VERSION ""

NS_ :

BS_:

BU_: AGSM BCM BSM CADM DMSM DTCM ECM EVCU2 GNMM HCP IPC RFHM SGW TCM
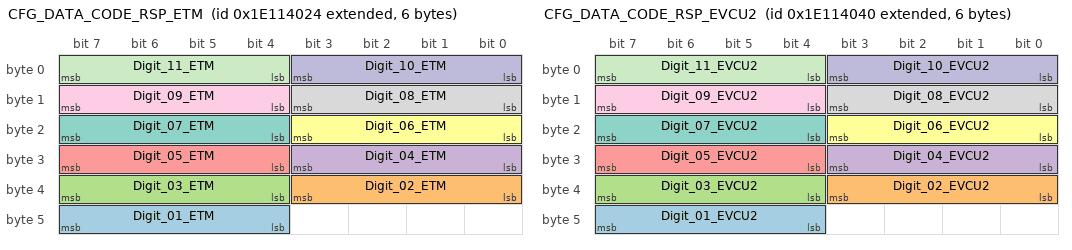
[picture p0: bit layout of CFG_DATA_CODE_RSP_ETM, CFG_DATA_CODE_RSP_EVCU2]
BO_ 2651930660 CFG_DATA_CODE_RSP_ETM: 6 SGW
 SG_ Digit_01_ETM : 47|4@0+ (1,0) [0|15] "-" BCM
 SG_ Digit_02_ETM : 35|4@0+ (1,0) [0|15] "-" BCM
 SG_ Digit_03_ETM : 39|4@0+ (1,0) [0|15] "-" BCM
 SG_ Digit_04_ETM : 27|4@0+ (1,0) [0|15] "-" BCM
 SG_ Digit_05_ETM : 31|4@0+ (1,0) [0|15] "-" BCM
 SG_ Digit_06_ETM : 19|4@0+ (1,0) [0|15] "-" BCM
 SG_ Digit_07_ETM : 23|4@0+ (1,0) [0|15] "-" BCM
 SG_ Digit_08_ETM : 11|4@0+ (1,0) [0|15] "-" BCM
 SG_ Digit_09_ETM : 15|4@0+ (1,0) [0|15] "-" BCM
 SG_ Digit_10_ETM : 3|4@0+ (1,0) [0|15] "-" BCM
 SG_ Digit_11_ETM : 7|4@0+ (1,0) [0|15] "-" BCM

BO_ 2651930688 CFG_DATA_CODE_RSP_EVCU2: 6 EVCU2
 SG_ Digit_01_EVCU2 : 47|4@0+ (1,0) [0|15] "-" BCM
 SG_ Digit_02_EVCU2 : 35|4@0+ (1,0) [0|15] "-" BCM
 SG_ Digit_03_EVCU2 : 39|4@0+ (1,0) [0|15] "-" BCM
 SG_ Digit_04_EVCU2 : 27|4@0+ (1,0) [0|15] "-" BCM
 SG_ Digit_05_EVCU2 : 31|4@0+ (1,0) [0|15] "-" BCM
 SG_ Digit_06_EVCU2 : 19|4@0+ (1,0) [0|15] "-" BCM
 SG_ Digit_07_EVCU2 : 23|4@0+ (1,0) [0|15] "-" BCM
 SG_ Digit_08_EVCU2 : 11|4@0+ (1,0) [0|15] "-" BCM
 SG_ Digit_09_EVCU2 : 15|4@0+ (1,0) [0|15] "-" BCM
 SG_ Digit_10_EVCU2 : 3|4@0+ (1,0) [0|15] "-" BCM
 SG_ Digit_11_EVCU2 : 7|4@0+ (1,0) [0|15] "-" BCM

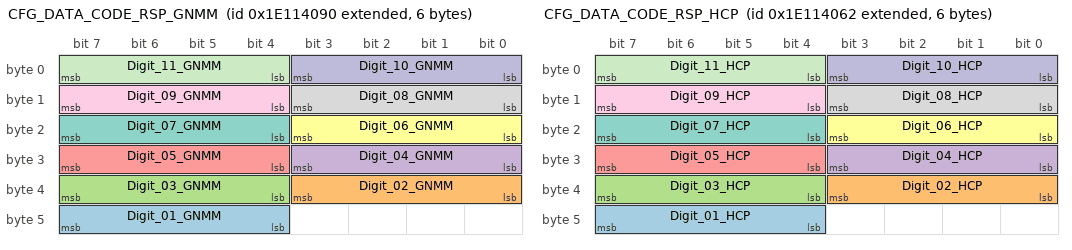
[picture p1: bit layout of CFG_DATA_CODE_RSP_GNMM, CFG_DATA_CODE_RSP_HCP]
BO_ 2651930768 CFG_DATA_CODE_RSP_GNMM: 6 GNMM
 SG_ Digit_01_GNMM : 47|4@0+ (1,0) [0|15] "-" BCM
 SG_ Digit_02_GNMM : 35|4@0+ (1,0) [0|15] "-" BCM
 SG_ Digit_03_GNMM : 39|4@0+ (1,0) [0|15] "-" BCM
 SG_ Digit_04_GNMM : 27|4@0+ (1,0) [0|15] "-" BCM
 SG_ Digit_05_GNMM : 31|4@0+ (1,0) [0|15] "-" BCM
 SG_ Digit_06_GNMM : 19|4@0+ (1,0) [0|15] "-" BCM
 SG_ Digit_07_GNMM : 23|4@0+ (1,0) [0|15] "-" BCM
 SG_ Digit_08_GNMM : 11|4@0+ (1,0) [0|15] "-" BCM
 SG_ Digit_09_GNMM : 15|4@0+ (1,0) [0|15] "-" BCM
 SG_ Digit_10_GNMM : 3|4@0+ (1,0) [0|15] "-" BCM
 SG_ Digit_11_GNMM : 7|4@0+ (1,0) [0|15] "-" BCM

BO_ 2651930722 CFG_DATA_CODE_RSP_HCP: 6 HCP
 SG_ Digit_01_HCP : 47|4@0+ (1,0) [0|15] "-" BCM
 SG_ Digit_02_HCP : 35|4@0+ (1,0) [0|15] "-" BCM
 SG_ Digit_03_HCP : 39|4@0+ (1,0) [0|15] "-" BCM
 SG_ Digit_04_HCP : 27|4@0+ (1,0) [0|15] "-" BCM
 SG_ Digit_05_HCP : 31|4@0+ (1,0) [0|15] "-" BCM
 SG_ Digit_06_HCP : 19|4@0+ (1,0) [0|15] "-" BCM
 SG_ Digit_07_HCP : 23|4@0+ (1,0) [0|15] "-" BCM
 SG_ Digit_08_HCP : 11|4@0+ (1,0) [0|15] "-" BCM
 SG_ Digit_09_HCP : 15|4@0+ (1,0) [0|15] "-" BCM
 SG_ Digit_10_HCP : 3|4@0+ (1,0) [0|15] "-" BCM
 SG_ Digit_11_HCP : 7|4@0+ (1,0) [0|15] "-" BCM

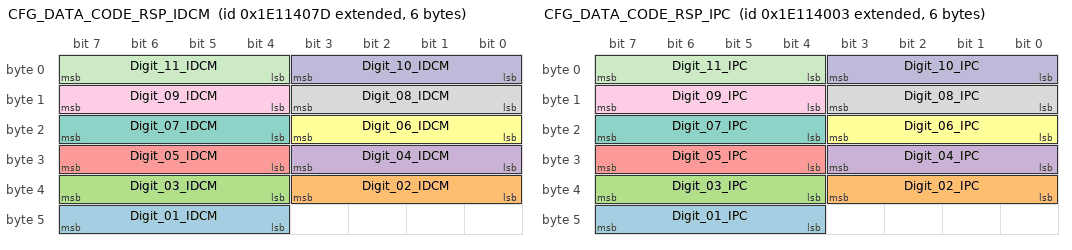
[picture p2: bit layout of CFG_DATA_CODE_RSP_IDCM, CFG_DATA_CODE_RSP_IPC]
BO_ 2651930749 CFG_DATA_CODE_RSP_IDCM: 6 EVCU2
 SG_ Digit_01_IDCM : 47|4@0+ (1,0) [0|15] "-" BCM
 SG_ Digit_02_IDCM : 35|4@0+ (1,0) [0|15] "-" BCM
 SG_ Digit_03_IDCM : 39|4@0+ (1,0) [0|15] "-" BCM
 SG_ Digit_04_IDCM : 27|4@0+ (1,0) [0|15] "-" BCM
 SG_ Digit_05_IDCM : 31|4@0+ (1,0) [0|15] "-" BCM
 SG_ Digit_06_IDCM : 19|4@0+ (1,0) [0|15] "-" BCM
 SG_ Digit_07_IDCM : 23|4@0+ (1,0) [0|15] "-" BCM
 SG_ Digit_08_IDCM : 11|4@0+ (1,0) [0|15] "-" BCM
 SG_ Digit_09_IDCM : 15|4@0+ (1,0) [0|15] "-" BCM
 SG_ Digit_10_IDCM : 3|4@0+ (1,0) [0|15] "-" BCM
 SG_ Digit_11_IDCM : 7|4@0+ (1,0) [0|15] "-" BCM

BO_ 2651930627 CFG_DATA_CODE_RSP_IPC: 6 IPC
 SG_ Digit_01_IPC : 47|4@0+ (1,0) [0|15] "-" BCM
 SG_ Digit_02_IPC : 35|4@0+ (1,0) [0|15] "-" BCM
 SG_ Digit_03_IPC : 39|4@0+ (1,0) [0|15] "-" BCM
 SG_ Digit_04_IPC : 27|4@0+ (1,0) [0|15] "-" BCM
 SG_ Digit_05_IPC : 31|4@0+ (1,0) [0|15] "-" BCM
 SG_ Digit_06_IPC : 19|4@0+ (1,0) [0|15] "-" BCM
 SG_ Digit_07_IPC : 23|4@0+ (1,0) [0|15] "-" BCM
 SG_ Digit_08_IPC : 11|4@0+ (1,0) [0|15] "-" BCM
 SG_ Digit_09_IPC : 15|4@0+ (1,0) [0|15] "-" BCM
 SG_ Digit_10_IPC : 3|4@0+ (1,0) [0|15] "-" BCM
 SG_ Digit_11_IPC : 7|4@0+ (1,0) [0|15] "-" BCM

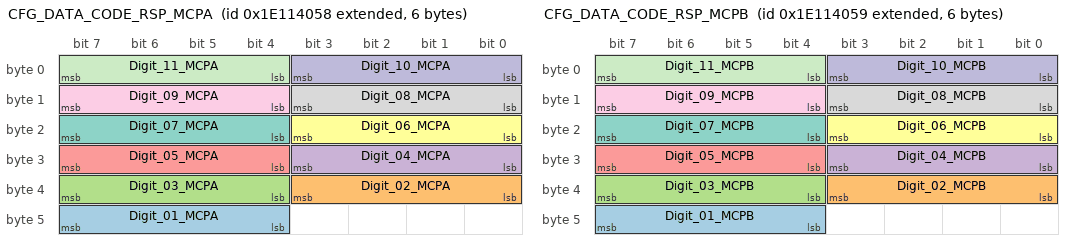
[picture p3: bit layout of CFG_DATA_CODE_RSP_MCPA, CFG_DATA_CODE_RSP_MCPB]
BO_ 2651930712 CFG_DATA_CODE_RSP_MCPA: 6 EVCU2
 SG_ Digit_01_MCPA : 47|4@0+ (1,0) [0|15] "-" BCM
 SG_ Digit_02_MCPA : 35|4@0+ (1,0) [0|15] "-" BCM
 SG_ Digit_03_MCPA : 39|4@0+ (1,0) [0|15] "-" BCM
 SG_ Digit_04_MCPA : 27|4@0+ (1,0) [0|15] "-" BCM
 SG_ Digit_05_MCPA : 31|4@0+ (1,0) [0|15] "-" BCM
 SG_ Digit_06_MCPA : 19|4@0+ (1,0) [0|15] "-" BCM
 SG_ Digit_07_MCPA : 23|4@0+ (1,0) [0|15] "-" BCM
 SG_ Digit_08_MCPA : 11|4@0+ (1,0) [0|15] "-" BCM
 SG_ Digit_09_MCPA : 15|4@0+ (1,0) [0|15] "-" BCM
 SG_ Digit_10_MCPA : 3|4@0+ (1,0) [0|15] "-" BCM
 SG_ Digit_11_MCPA : 7|4@0+ (1,0) [0|15] "-" BCM

BO_ 2651930713 CFG_DATA_CODE_RSP_MCPB: 6 EVCU2
 SG_ Digit_01_MCPB : 47|4@0+ (1,0) [0|15] "-" BCM
 SG_ Digit_02_MCPB : 35|4@0+ (1,0) [0|15] "-" BCM
 SG_ Digit_03_MCPB : 39|4@0+ (1,0) [0|15] "-" BCM
 SG_ Digit_04_MCPB : 27|4@0+ (1,0) [0|15] "-" BCM
 SG_ Digit_05_MCPB : 31|4@0+ (1,0) [0|15] "-" BCM
 SG_ Digit_06_MCPB : 19|4@0+ (1,0) [0|15] "-" BCM
 SG_ Digit_07_MCPB : 23|4@0+ (1,0) [0|15] "-" BCM
 SG_ Digit_08_MCPB : 11|4@0+ (1,0) [0|15] "-" BCM
 SG_ Digit_09_MCPB : 15|4@0+ (1,0) [0|15] "-" BCM
 SG_ Digit_10_MCPB : 3|4@0+ (1,0) [0|15] "-" BCM
 SG_ Digit_11_MCPB : 7|4@0+ (1,0) [0|15] "-" BCM

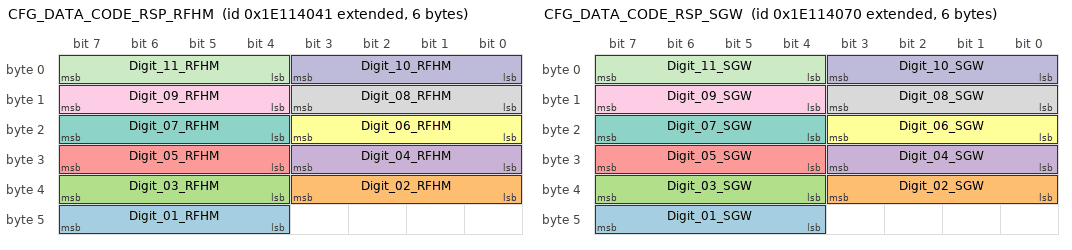
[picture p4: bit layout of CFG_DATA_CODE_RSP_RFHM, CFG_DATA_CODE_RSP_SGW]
BO_ 2651930689 CFG_DATA_CODE_RSP_RFHM: 6 RFHM
 SG_ Digit_01_RFHM : 47|4@0+ (1,0) [0|15] "-" BCM
 SG_ Digit_02_RFHM : 35|4@0+ (1,0) [0|15] "-" BCM
 SG_ Digit_03_RFHM : 39|4@0+ (1,0) [0|15] "-" BCM
 SG_ Digit_04_RFHM : 27|4@0+ (1,0) [0|15] "-" BCM
 SG_ Digit_05_RFHM : 31|4@0+ (1,0) [0|15] "-" BCM
 SG_ Digit_06_RFHM : 19|4@0+ (1,0) [0|15] "-" BCM
 SG_ Digit_07_RFHM : 23|4@0+ (1,0) [0|15] "-" BCM
 SG_ Digit_08_RFHM : 11|4@0+ (1,0) [0|15] "-" BCM
 SG_ Digit_09_RFHM : 15|4@0+ (1,0) [0|15] "-" BCM
 SG_ Digit_10_RFHM : 3|4@0+ (1,0) [0|15] "-" BCM
 SG_ Digit_11_RFHM : 7|4@0+ (1,0) [0|15] "-" BCM

BO_ 2651930736 CFG_DATA_CODE_RSP_SGW: 6 SGW
 SG_ Digit_01_SGW : 47|4@0+ (1,0) [0|15] "-" BCM
 SG_ Digit_02_SGW : 35|4@0+ (1,0) [0|15] "-" BCM
 SG_ Digit_03_SGW : 39|4@0+ (1,0) [0|15] "-" BCM
 SG_ Digit_04_SGW : 27|4@0+ (1,0) [0|15] "-" BCM
 SG_ Digit_05_SGW : 31|4@0+ (1,0) [0|15] "-" BCM
 SG_ Digit_06_SGW : 19|4@0+ (1,0) [0|15] "-" BCM
 SG_ Digit_07_SGW : 23|4@0+ (1,0) [0|15] "-" BCM
 SG_ Digit_08_SGW : 11|4@0+ (1,0) [0|15] "-" BCM
 SG_ Digit_09_SGW : 15|4@0+ (1,0) [0|15] "-" BCM
 SG_ Digit_10_SGW : 3|4@0+ (1,0) [0|15] "-" BCM
 SG_ Digit_11_SGW : 7|4@0+ (1,0) [0|15] "-" BCM

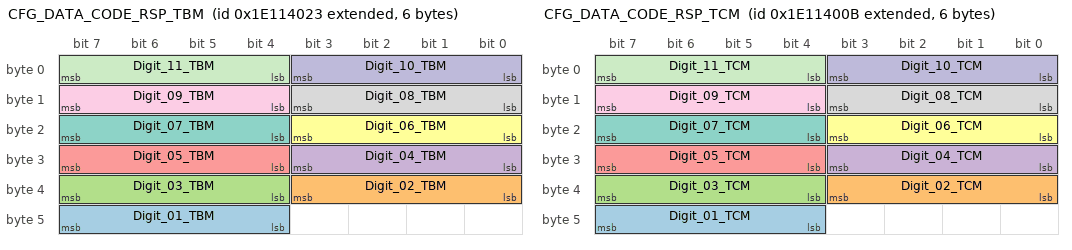
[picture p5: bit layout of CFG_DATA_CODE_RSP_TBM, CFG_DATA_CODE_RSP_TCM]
BO_ 2651930659 CFG_DATA_CODE_RSP_TBM: 6 SGW
 SG_ Digit_01_TBM : 47|4@0+ (1,0) [0|15] "-" BCM
 SG_ Digit_02_TBM : 35|4@0+ (1,0) [0|15] "-" BCM
 SG_ Digit_03_TBM : 39|4@0+ (1,0) [0|15] "-" BCM
 SG_ Digit_04_TBM : 27|4@0+ (1,0) [0|15] "-" BCM
 SG_ Digit_05_TBM : 31|4@0+ (1,0) [0|15] "-" BCM
 SG_ Digit_06_TBM : 19|4@0+ (1,0) [0|15] "-" BCM
 SG_ Digit_07_TBM : 23|4@0+ (1,0) [0|15] "-" BCM
 SG_ Digit_08_TBM : 11|4@0+ (1,0) [0|15] "-" BCM
 SG_ Digit_09_TBM : 15|4@0+ (1,0) [0|15] "-" BCM
 SG_ Digit_10_TBM : 3|4@0+ (1,0) [0|15] "-" BCM
 SG_ Digit_11_TBM : 7|4@0+ (1,0) [0|15] "-" BCM

BO_ 2651930635 CFG_DATA_CODE_RSP_TCM: 6 TCM
 SG_ Digit_01_TCM : 47|4@0+ (1,0) [0|15] "-" BCM
 SG_ Digit_02_TCM : 35|4@0+ (1,0) [0|15] "-" BCM
 SG_ Digit_03_TCM : 39|4@0+ (1,0) [0|15] "-" BCM
 SG_ Digit_04_TCM : 27|4@0+ (1,0) [0|15] "-" BCM
 SG_ Digit_05_TCM : 31|4@0+ (1,0) [0|15] "-" BCM
 SG_ Digit_06_TCM : 19|4@0+ (1,0) [0|15] "-" BCM
 SG_ Digit_07_TCM : 23|4@0+ (1,0) [0|15] "-" BCM
 SG_ Digit_08_TCM : 11|4@0+ (1,0) [0|15] "-" BCM
 SG_ Digit_09_TCM : 15|4@0+ (1,0) [0|15] "-" BCM
 SG_ Digit_10_TCM : 3|4@0+ (1,0) [0|15] "-" BCM
 SG_ Digit_11_TCM : 7|4@0+ (1,0) [0|15] "-" BCM

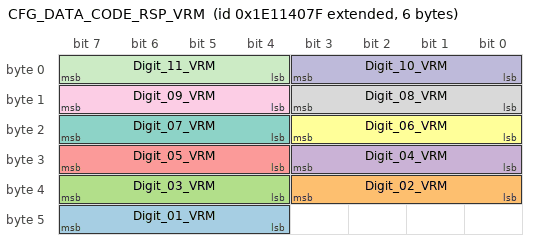
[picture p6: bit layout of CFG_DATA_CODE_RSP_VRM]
BO_ 2651930751 CFG_DATA_CODE_RSP_VRM: 6 SGW
 SG_ Digit_01_VRM : 47|4@0+ (1,0) [0|15] "-" BCM
 SG_ Digit_02_VRM : 35|4@0+ (1,0) [0|15] "-" BCM
 SG_ Digit_03_VRM : 39|4@0+ (1,0) [0|15] "-" BCM
 SG_ Digit_04_VRM : 27|4@0+ (1,0) [0|15] "-" BCM
 SG_ Digit_05_VRM : 31|4@0+ (1,0) [0|15] "-" BCM
 SG_ Digit_06_VRM : 19|4@0+ (1,0) [0|15] "-" BCM
 SG_ Digit_07_VRM : 23|4@0+ (1,0) [0|15] "-" BCM
 SG_ Digit_08_VRM : 11|4@0+ (1,0) [0|15] "-" BCM
 SG_ Digit_09_VRM : 15|4@0+ (1,0) [0|15] "-" BCM
 SG_ Digit_10_VRM : 3|4@0+ (1,0) [0|15] "-" BCM
 SG_ Digit_11_VRM : 7|4@0+ (1,0) [0|15] "-" BCM

BO_ 1457 CHARGE_SCHEDULE_HCP1: 32 EVCU2
 SG_ Charge_Schedule_Type1_Sts : 98|2@0+ (1,0) [0|3] "" SGW
 SG_ Charge_Schedule_Type2_Sts : 107|2@0+ (1,0) [0|3] "" SGW
 SG_ ChargeUntilFull1_Sts : 8|1@0+ (1,0) [0|1] "-" SGW
 SG_ ChargeUntilFull2_Sts : 32|1@0+ (1,0) [0|1] "-" SGW
 SG_ End_Time_Hr1_Sts : 39|5@0+ (1,0) [0|23] "Hours" SGW
 SG_ End_Time_Hr2_Sts : 71|5@0+ (1,0) [0|23] "Hours" SGW
 SG_ End_Time_Min1_Sts : 27|4@0+ (5,0) [0|55] "min" SGW
 SG_ End_Time_Min2_Sts : 79|4@0+ (5,0) [0|55] "min" SGW
 SG_ External_ChargeTarget1_Sts : 120|4@0+ (5,50) [50|125] "%" SGW
 SG_ External_ChargeTarget2_Sts : 132|4@0+ (5,50) [50|125] "%" SGW
 SG_ Immediate_ChargeTarget1_Sts : 117|4@0+ (5,0) [0|15] "%" SGW
 SG_ Immediate_ChargeTarget2_Sts : 124|4@0+ (5,0) [0|15] "%" SGW
 SG_ Schedule_Confirmed1 : 16|1@0+ (1,0) [0|1] "-" SGW
 SG_ Schedule_Confirmed2 : 48|1@0+ (1,0) [0|1] "-" SGW
 SG_ Schedule_Day1_Sts : 7|8@0+ (1,0) [0|255] "-" SGW
 SG_ Schedule_Day2_Sts : 47|8@0+ (1,0) [0|255] "-" SGW
 SG_ Start_Time_Hr1_Sts : 22|5@0+ (1,0) [0|23] "Hours" SGW
 SG_ Start_Time_Hr2_Sts : 54|5@0+ (1,0) [0|23] "Hours" SGW
 SG_ Start_Time_Min1_Sts : 31|4@0+ (5,0) [0|55] "min" SGW
 SG_ Start_Time_Min2_Sts : 63|4@0+ (5,0) [0|55] "min" SGW

BO_ 1464 CHARGE_SCHEDULE_HU1: 32 SGW
 SG_ Charge_Schedule_Type1 : 98|2@0+ (1,0) [0|3] "" EVCU2
 SG_ Charge_Schedule_Type2 : 106|2@0+ (1,0) [0|3] "" EVCU2
 SG_ ChargeUntilFull1 : 8|1@0+ (1,0) [0|1] "-" EVCU2
 SG_ ChargeUntilFull2 : 32|1@0+ (1,0) [0|1] "-" EVCU2
 SG_ Enable_Schedule1 : 72|1@0+ (1,0) [0|1] "-" EVCU2
 SG_ Enable_Schedule2 : 73|1@0+ (1,0) [0|1] "-" EVCU2
 SG_ End_Time_Hr1 : 39|5@0+ (1,0) [0|23] "Hours" EVCU2
 SG_ End_Time_Hr2 : 71|5@0+ (1,0) [0|23] "Hours" EVCU2
 SG_ End_Time_Min1 : 27|4@0+ (5,0) [0|55] "min" EVCU2
 SG_ End_Time_Min2 : 79|4@0+ (5,0) [0|55] "min" EVCU2
 SG_ External_ChargeTarget1 : 143|4@0+ (5,50) [50|125] "%" EVCU2
 SG_ External_ChargeTarget2 : 139|4@0+ (5,50) [50|125] "%" EVCU2
 SG_ Immediate_ChargeTarget1 : 135|4@0+ (5,0) [0|75] "%" EVCU2
 SG_ Immediate_ChargeTarget2 : 131|4@0+ (5,0) [0|75] "%" EVCU2
 SG_ Schedule_Day1 : 7|8@0+ (1,0) [0|255] "-" EVCU2
 SG_ Schedule_Day2 : 47|8@0+ (1,0) [0|255] "-" EVCU2
 SG_ Start_Time_Hr1 : 22|5@0+ (1,0) [0|23] "Hours" EVCU2
 SG_ Start_Time_Hr2 : 54|5@0+ (1,0) [0|23] "Hours" EVCU2
 SG_ Start_Time_Min1 : 31|4@0+ (5,0) [0|55] "min" EVCU2
 SG_ Start_Time_Min2 : 63|4@0+ (5,0) [0|55] "min" EVCU2
 SG_ Submit_Schedule1 : 16|1@0+ (1,0) [0|1] "-" EVCU2
 SG_ Submit_Schedule2 : 48|1@0+ (1,0) [0|1] "-" EVCU2

CM_ SG_ 1457 Charge_Schedule_Type1_Sts "ECVU/HCP Schedule 1 Currently Set Charge Schedule Type";
CM_ SG_ 1457 Charge_Schedule_Type2_Sts "ECVU/HCP Schedule 2 Currently Set Charge Schedule Type";
CM_ SG_ 1457 ChargeUntilFull1_Sts "Charge until battery is fully charged with schedule 1";
CM_ SG_ 1457 ChargeUntilFull2_Sts "Charge until battery is fully charged with schedule 2 confirmation";
CM_ SG_ 1457 End_Time_Hr1_Sts "End Time of schedule 1 (hours in 24 hrs. format)";
CM_ SG_ 1457 End_Time_Hr2_Sts "End Time of schedule  2 (hours in 24 hrs. format) feedback";
CM_ SG_ 1457 End_Time_Min1_Sts "End Time of schedule 1(Minutes)";
CM_ SG_ 1457 End_Time_Min2_Sts "End Time of schedule  2 (Minutes) feedback";
CM_ SG_ 1457 External_ChargeTarget1_Sts "ECVU/HCP Schedule 1 Currently Set External Charge Target Value";
CM_ SG_ 1457 External_ChargeTarget2_Sts "ECVU/HCP Schedule 2 Currently Set External Charge Target Value";
CM_ SG_ 1457 Immediate_ChargeTarget1_Sts "ECVU/HCP Schedule 1 Currently Set Immediate Charge Target Value";
CM_ SG_ 1457 Immediate_ChargeTarget2_Sts "ECVU/HCP Schedule 2 Currently Set Immediate Charge Target Value
0 to 50% with 5% Increment";
CM_ SG_ 1457 Schedule_Confirmed1 "Confirm the requested schedule 1";
CM_ SG_ 1457 Schedule_Confirmed2 "Confirm the requested schedule 2";
CM_ SG_ 1457 Schedule_Day1_Sts "Schedule#1 Day for charging or cabin conditioning";
CM_ SG_ 1457 Schedule_Day2_Sts "Scheduled#2 Day for charging or cabin conditioning confirmation";
CM_ SG_ 1457 Start_Time_Hr1_Sts "Start Time of schedule  1 (hours in 24 hrs. format)";
CM_ SG_ 1457 Start_Time_Hr2_Sts "Start Time of schedule  2(hours in 24 hrs. format) feedback";
CM_ SG_ 1457 Start_Time_Min1_Sts "Start Time of schedule  1 (minutes)";
CM_ SG_ 1457 Start_Time_Min2_Sts "Start Time of schedule  2 (minutes) feedback";
CM_ SG_ 1464 Charge_Schedule_Type1 "HU Schedule 1 Setter Signal for Changing the Current Charge Schedule Type";
CM_ SG_ 1464 Charge_Schedule_Type2 "HU Schedule 2 Setter Signal for Changing the Current Charge Schedule Type";
CM_ SG_ 1464 ChargeUntilFull1 "Charge until battery is fully charged with schedule 1";
CM_ SG_ 1464 ChargeUntilFull2 "Charge until battery is fully charged with schedule 2";
CM_ SG_ 1464 Enable_Schedule1 "Schedule 1 checkbox enabled";
CM_ SG_ 1464 Enable_Schedule2 "Schedule 2 checkbox enabled";
CM_ SG_ 1464 End_Time_Hr1 "End Time of schedule 1 (hours in 24 hrs. format)";
CM_ SG_ 1464 End_Time_Hr2 "End Time of schedule  2 (hours in 24 hrs. format)";
CM_ SG_ 1464 End_Time_Min1 "End Time of schedule 1(Minutes)";
CM_ SG_ 1464 End_Time_Min2 "End Time of schedule  2(Minutes)";
CM_ SG_ 1464 External_ChargeTarget1 "HU Schedule 1 Setter Signal for Changing the Current External Charge Target Value 50 to 100% with 5% Increment";
CM_ SG_ 1464 External_ChargeTarget2 "HU Schedule 2 Setter Signal for Changing the Current External Charge Target Value";
CM_ SG_ 1464 Immediate_ChargeTarget1 "HU Schedule 1 Setter Signal for Changing the Current Immediate Charge Target Value";
CM_ SG_ 1464 Immediate_ChargeTarget2 "HU Schedule 2 Setter Signal for Changing the Current Immediate Charge Target Value";
CM_ SG_ 1464 Schedule_Day1 "Schedule#1 Day for charging or cabin conditioning";
CM_ SG_ 1464 Schedule_Day2 "Schedule#2 Day for charging or cabin conditioning";
CM_ SG_ 1464 Start_Time_Hr1 "Start Time of schedule  1 (hours in 24 hrs. format)";
CM_ SG_ 1464 Start_Time_Hr2 "Start Time of schedule  2(hours in 24 hrs. format)";
CM_ SG_ 1464 Start_Time_Min1 "Start Time of schedule  1 (minutes)";
CM_ SG_ 1464 Start_Time_Min2 "Start Time of schedule  2 (minutes)";
CM_ SG_ 1464 Submit_Schedule1 "Schedule 1 submitted";
CM_ SG_ 1464 Submit_Schedule2 "Schedule 2 submitted";

BA_DEF_ SG_ "GenSigStartValue" INT 0 2147483647;
BA_DEF_ SG_ "GenSigInactiveValue" INT 0 2147483647;
BA_DEF_ SG_ "GenSigSendType" ENUM "NotUsed","OnWrite","OnWriteWithRepetition","OnChange","OnChangeWithRepetition","IfActive","IfActiveWithRepetition","NoSigSendType";
BA_DEF_ SG_ "SystemSignalLongSymbol" STRING ;
BA_DEF_ SG_ "GenSigTimeoutTime_AGSM" INT 0 65535;
BA_DEF_ SG_ "GenSigTimeoutTime_BCM" INT 0 65535;
BA_DEF_ SG_ "GenSigTimeoutTime_BSM" INT 0 65535;
BA_DEF_ SG_ "GenSigTimeoutTime_CADM" INT 0 65535;
BA_DEF_ SG_ "GenSigTimeoutTime_DMSM" INT 0 65535;
BA_DEF_ SG_ "GenSigTimeoutTime_DTCM" INT 0 65535;
BA_DEF_ SG_ "GenSigTimeoutTime_ECM" INT 0 65535;
BA_DEF_ SG_ "GenSigTimeoutTime_EVCU2" INT 0 65535;
BA_DEF_ SG_ "GenSigTimeoutTime_GNMM" INT 0 65535;
BA_DEF_ SG_ "GenSigTimeoutTime_HCP" INT 0 65535;
BA_DEF_ SG_ "GenSigTimeoutTime_IPC" INT 0 65535;
BA_DEF_ SG_ "GenSigTimeoutTime_RFHM" INT 0 65535;
BA_DEF_ SG_ "GenSigTimeoutTime_SGW" INT 0 65535;
BA_DEF_ SG_ "GenSigTimeoutTime_TCM" INT 0 65535;
BA_DEF_ BO_ "DiagRequest" ENUM "No","Yes";
BA_DEF_ BO_ "Type" ENUM "P","C","PE","COC","PE_Cntrl","E","E_Cntrl","OC","S","BAF","DC","EM","MM","ISO-TP","-";
BA_DEF_ BO_ "DiagResponse" ENUM "No","Yes";
BA_DEF_ BO_ "NmMessage" ENUM "No","Yes";
BA_DEF_ BO_ "GenMsgSendType" ENUM "Cyclic","NotUsed","NotUsed","NotUsed","NotUsed","NotUsed","NotUsed","NotUsed","NoMsgSendType";
BA_DEF_ BO_ "GenMsgNrOfRepetition" INT 0 255;
BA_DEF_ BO_ "GenMsgILSupport" ENUM "No","Yes";
BA_DEF_ BO_ "GenMsgStartDelayTime" INT 0 65535;
BA_DEF_ BO_ "GenMsgCycleTimeFast" INT 0 65535;
BA_DEF_ BO_ "GenMsgCycleTime" INT 0 65535;
BA_DEF_ BO_ "GenMsgDelayTime" INT 0 65535;
BA_DEF_ BO_ "NmAsrMessage" ENUM "No","Yes";
BA_DEF_ BO_ "DiagState" ENUM "No","Yes";
BA_DEF_ BO_ "DiagConnection" HEX 0 65535;
BA_DEF_ BO_ "VFrameFormat" ENUM "StandardCAN","ExtendedCAN","reserved","reserved","reserved","reserved","reserved","reserved","reserved","reserved","reserved","reserved","reserved","reserved","StandardCAN_FD","ExtendedCAN_FD";
BA_DEF_ BO_ "CANFD_BRS" ENUM "0","1";
BA_DEF_DEF_ "DiagRequest" "No";
BA_DEF_DEF_ "Type" "-";
BA_DEF_DEF_ "DiagResponse" "No";
BA_DEF_DEF_ "NmMessage" "No";
BA_DEF_DEF_ "GenMsgSendType" "NoMsgSendType";
BA_DEF_DEF_ "GenMsgNrOfRepetition" 0;
BA_DEF_DEF_ "GenMsgILSupport" "No";
BA_DEF_DEF_ "GenMsgStartDelayTime" 0;
BA_DEF_DEF_ "GenMsgCycleTimeFast" 0;
BA_DEF_DEF_ "GenMsgCycleTime" 0;
BA_DEF_DEF_ "GenMsgDelayTime" 0;
BA_DEF_DEF_ "NmAsrMessage" "No";
BA_DEF_DEF_ "DiagState" "No";
BA_DEF_DEF_ "DiagConnection" 0;
BA_DEF_DEF_ "VFrameFormat" "StandardCAN_FD";
BA_DEF_DEF_ "CANFD_BRS" "0";
BA_DEF_DEF_ "GenSigStartValue" 0;
BA_DEF_DEF_ "GenSigInactiveValue" 0;
BA_DEF_DEF_ "GenSigSendType" "NoSigSendType";
BA_DEF_DEF_ "SystemSignalLongSymbol" "";
BA_DEF_DEF_ "GenSigTimeoutTime_AGSM" 2500;
BA_DEF_DEF_ "GenSigTimeoutTime_BCM" 2500;
BA_DEF_DEF_ "GenSigTimeoutTime_BSM" 2500;
BA_DEF_DEF_ "GenSigTimeoutTime_CADM" 2500;
BA_DEF_DEF_ "GenSigTimeoutTime_DMSM" 2500;
BA_DEF_DEF_ "GenSigTimeoutTime_DTCM" 2500;
BA_DEF_DEF_ "GenSigTimeoutTime_ECM" 2500;
BA_DEF_DEF_ "GenSigTimeoutTime_EVCU2" 2500;
BA_DEF_DEF_ "GenSigTimeoutTime_GNMM" 2500;
BA_DEF_DEF_ "GenSigTimeoutTime_HCP" 2500;
BA_DEF_DEF_ "GenSigTimeoutTime_IPC" 2500;
BA_DEF_DEF_ "GenSigTimeoutTime_RFHM" 2500;
BA_DEF_DEF_ "GenSigTimeoutTime_SGW" 2500;
BA_DEF_DEF_ "GenSigTimeoutTime_TCM" 2500;
BA_ "Type" BO_ 2651930660 11;
BA_ "GenMsgILSupport" BO_ 2651930660 1;
BA_ "VFrameFormat" BO_ 2651930660 15;
BA_ "CANFD_BRS" BO_ 2651930660 1;
BA_ "Type" BO_ 2651930688 11;
BA_ "GenMsgILSupport" BO_ 2651930688 1;
BA_ "VFrameFormat" BO_ 2651930688 15;
BA_ "CANFD_BRS" BO_ 2651930688 1;
BA_ "Type" BO_ 2651930768 11;
BA_ "GenMsgILSupport" BO_ 2651930768 1;
BA_ "VFrameFormat" BO_ 2651930768 15;
BA_ "CANFD_BRS" BO_ 2651930768 1;
BA_ "Type" BO_ 2651930722 11;
BA_ "GenMsgILSupport" BO_ 2651930722 1;
BA_ "VFrameFormat" BO_ 2651930722 15;
BA_ "CANFD_BRS" BO_ 2651930722 1;
BA_ "Type" BO_ 2651930749 11;
BA_ "GenMsgILSupport" BO_ 2651930749 1;
BA_ "VFrameFormat" BO_ 2651930749 15;
BA_ "CANFD_BRS" BO_ 2651930749 1;
BA_ "Type" BO_ 2651930627 11;
BA_ "GenMsgILSupport" BO_ 2651930627 1;
BA_ "VFrameFormat" BO_ 2651930627 15;
BA_ "CANFD_BRS" BO_ 2651930627 1;
BA_ "Type" BO_ 2651930712 11;
BA_ "GenMsgILSupport" BO_ 2651930712 1;
BA_ "VFrameFormat" BO_ 2651930712 15;
BA_ "CANFD_BRS" BO_ 2651930712 1;
BA_ "Type" BO_ 2651930713 11;
BA_ "GenMsgILSupport" BO_ 2651930713 1;
BA_ "VFrameFormat" BO_ 2651930713 15;
BA_ "CANFD_BRS" BO_ 2651930713 1;
BA_ "Type" BO_ 2651930689 11;
BA_ "GenMsgILSupport" BO_ 2651930689 1;
BA_ "VFrameFormat" BO_ 2651930689 15;
BA_ "CANFD_BRS" BO_ 2651930689 1;
BA_ "Type" BO_ 2651930736 11;
BA_ "GenMsgILSupport" BO_ 2651930736 1;
BA_ "VFrameFormat" BO_ 2651930736 15;
BA_ "CANFD_BRS" BO_ 2651930736 1;
BA_ "Type" BO_ 2651930659 11;
BA_ "GenMsgILSupport" BO_ 2651930659 1;
BA_ "VFrameFormat" BO_ 2651930659 15;
BA_ "CANFD_BRS" BO_ 2651930659 1;
BA_ "Type" BO_ 2651930635 11;
BA_ "GenMsgILSupport" BO_ 2651930635 1;
BA_ "VFrameFormat" BO_ 2651930635 15;
BA_ "CANFD_BRS" BO_ 2651930635 1;
BA_ "Type" BO_ 2651930751 11;
BA_ "GenMsgILSupport" BO_ 2651930751 1;
BA_ "VFrameFormat" BO_ 2651930751 15;
BA_ "CANFD_BRS" BO_ 2651930751 1;
BA_ "Type" BO_ 1457 3;
BA_ "GenMsgSendType" BO_ 1457 0;
BA_ "GenMsgILSupport" BO_ 1457 1;
BA_ "GenMsgCycleTime" BO_ 1457 1000;
BA_ "GenMsgDelayTime" BO_ 1457 20;
BA_ "CANFD_BRS" BO_ 1457 1;
BA_ "Type" BO_ 1464 3;
BA_ "GenMsgSendType" BO_ 1464 0;
BA_ "GenMsgILSupport" BO_ 1464 1;
BA_ "GenMsgCycleTime" BO_ 1464 1000;
BA_ "GenMsgDelayTime" BO_ 1464 20;
BA_ "CANFD_BRS" BO_ 1464 1;
BA_ "GenSigSendType" SG_ 2651930660 Digit_01_ETM 1;
BA_ "GenSigTimeoutTime_AGSM" SG_ 2651930660 Digit_01_ETM 0;
BA_ "GenSigTimeoutTime_BSM" SG_ 2651930660 Digit_01_ETM 0;
BA_ "GenSigTimeoutTime_CADM" SG_ 2651930660 Digit_01_ETM 0;
BA_ "GenSigTimeoutTime_DMSM" SG_ 2651930660 Digit_01_ETM 0;
BA_ "GenSigTimeoutTime_DTCM" SG_ 2651930660 Digit_01_ETM 0;
BA_ "GenSigTimeoutTime_ECM" SG_ 2651930660 Digit_01_ETM 0;
BA_ "GenSigTimeoutTime_EVCU2" SG_ 2651930660 Digit_01_ETM 0;
BA_ "GenSigTimeoutTime_GNMM" SG_ 2651930660 Digit_01_ETM 0;
BA_ "GenSigTimeoutTime_HCP" SG_ 2651930660 Digit_01_ETM 0;
BA_ "GenSigTimeoutTime_IPC" SG_ 2651930660 Digit_01_ETM 0;
BA_ "GenSigTimeoutTime_RFHM" SG_ 2651930660 Digit_01_ETM 0;
BA_ "GenSigTimeoutTime_SGW" SG_ 2651930660 Digit_01_ETM 0;
BA_ "GenSigTimeoutTime_TCM" SG_ 2651930660 Digit_01_ETM 0;
BA_ "GenSigTimeoutTime_AGSM" SG_ 2651930660 Digit_02_ETM 0;
BA_ "GenSigTimeoutTime_BSM" SG_ 2651930660 Digit_02_ETM 0;
BA_ "GenSigTimeoutTime_CADM" SG_ 2651930660 Digit_02_ETM 0;
BA_ "GenSigTimeoutTime_DMSM" SG_ 2651930660 Digit_02_ETM 0;
BA_ "GenSigTimeoutTime_DTCM" SG_ 2651930660 Digit_02_ETM 0;
BA_ "GenSigTimeoutTime_ECM" SG_ 2651930660 Digit_02_ETM 0;
BA_ "GenSigTimeoutTime_EVCU2" SG_ 2651930660 Digit_02_ETM 0;
BA_ "GenSigTimeoutTime_GNMM" SG_ 2651930660 Digit_02_ETM 0;
BA_ "GenSigTimeoutTime_HCP" SG_ 2651930660 Digit_02_ETM 0;
BA_ "GenSigTimeoutTime_IPC" SG_ 2651930660 Digit_02_ETM 0;
BA_ "GenSigTimeoutTime_RFHM" SG_ 2651930660 Digit_02_ETM 0;
BA_ "GenSigTimeoutTime_SGW" SG_ 2651930660 Digit_02_ETM 0;
BA_ "GenSigTimeoutTime_TCM" SG_ 2651930660 Digit_02_ETM 0;
BA_ "GenSigTimeoutTime_AGSM" SG_ 2651930660 Digit_03_ETM 0;
BA_ "GenSigTimeoutTime_BSM" SG_ 2651930660 Digit_03_ETM 0;
BA_ "GenSigTimeoutTime_CADM" SG_ 2651930660 Digit_03_ETM 0;
BA_ "GenSigTimeoutTime_DMSM" SG_ 2651930660 Digit_03_ETM 0;
BA_ "GenSigTimeoutTime_DTCM" SG_ 2651930660 Digit_03_ETM 0;
BA_ "GenSigTimeoutTime_ECM" SG_ 2651930660 Digit_03_ETM 0;
BA_ "GenSigTimeoutTime_EVCU2" SG_ 2651930660 Digit_03_ETM 0;
BA_ "GenSigTimeoutTime_GNMM" SG_ 2651930660 Digit_03_ETM 0;
BA_ "GenSigTimeoutTime_HCP" SG_ 2651930660 Digit_03_ETM 0;
BA_ "GenSigTimeoutTime_IPC" SG_ 2651930660 Digit_03_ETM 0;
BA_ "GenSigTimeoutTime_RFHM" SG_ 2651930660 Digit_03_ETM 0;
BA_ "GenSigTimeoutTime_SGW" SG_ 2651930660 Digit_03_ETM 0;
BA_ "GenSigTimeoutTime_TCM" SG_ 2651930660 Digit_03_ETM 0;
BA_ "GenSigTimeoutTime_AGSM" SG_ 2651930660 Digit_04_ETM 0;
BA_ "GenSigTimeoutTime_BSM" SG_ 2651930660 Digit_04_ETM 0;
BA_ "GenSigTimeoutTime_CADM" SG_ 2651930660 Digit_04_ETM 0;
BA_ "GenSigTimeoutTime_DMSM" SG_ 2651930660 Digit_04_ETM 0;
BA_ "GenSigTimeoutTime_DTCM" SG_ 2651930660 Digit_04_ETM 0;
BA_ "GenSigTimeoutTime_ECM" SG_ 2651930660 Digit_04_ETM 0;
BA_ "GenSigTimeoutTime_EVCU2" SG_ 2651930660 Digit_04_ETM 0;
BA_ "GenSigTimeoutTime_GNMM" SG_ 2651930660 Digit_04_ETM 0;
BA_ "GenSigTimeoutTime_HCP" SG_ 2651930660 Digit_04_ETM 0;
BA_ "GenSigTimeoutTime_IPC" SG_ 2651930660 Digit_04_ETM 0;
BA_ "GenSigTimeoutTime_RFHM" SG_ 2651930660 Digit_04_ETM 0;
BA_ "GenSigTimeoutTime_SGW" SG_ 2651930660 Digit_04_ETM 0;
BA_ "GenSigTimeoutTime_TCM" SG_ 2651930660 Digit_04_ETM 0;
BA_ "GenSigTimeoutTime_AGSM" SG_ 2651930660 Digit_05_ETM 0;
BA_ "GenSigTimeoutTime_BSM" SG_ 2651930660 Digit_05_ETM 0;
BA_ "GenSigTimeoutTime_CADM" SG_ 2651930660 Digit_05_ETM 0;
BA_ "GenSigTimeoutTime_DMSM" SG_ 2651930660 Digit_05_ETM 0;
BA_ "GenSigTimeoutTime_DTCM" SG_ 2651930660 Digit_05_ETM 0;
BA_ "GenSigTimeoutTime_ECM" SG_ 2651930660 Digit_05_ETM 0;
BA_ "GenSigTimeoutTime_EVCU2" SG_ 2651930660 Digit_05_ETM 0;
BA_ "GenSigTimeoutTime_GNMM" SG_ 2651930660 Digit_05_ETM 0;
BA_ "GenSigTimeoutTime_HCP" SG_ 2651930660 Digit_05_ETM 0;
BA_ "GenSigTimeoutTime_IPC" SG_ 2651930660 Digit_05_ETM 0;
BA_ "GenSigTimeoutTime_RFHM" SG_ 2651930660 Digit_05_ETM 0;
BA_ "GenSigTimeoutTime_SGW" SG_ 2651930660 Digit_05_ETM 0;
BA_ "GenSigTimeoutTime_TCM" SG_ 2651930660 Digit_05_ETM 0;
BA_ "GenSigTimeoutTime_AGSM" SG_ 2651930660 Digit_06_ETM 0;
BA_ "GenSigTimeoutTime_BSM" SG_ 2651930660 Digit_06_ETM 0;
BA_ "GenSigTimeoutTime_CADM" SG_ 2651930660 Digit_06_ETM 0;
BA_ "GenSigTimeoutTime_DMSM" SG_ 2651930660 Digit_06_ETM 0;
BA_ "GenSigTimeoutTime_DTCM" SG_ 2651930660 Digit_06_ETM 0;
BA_ "GenSigTimeoutTime_ECM" SG_ 2651930660 Digit_06_ETM 0;
BA_ "GenSigTimeoutTime_EVCU2" SG_ 2651930660 Digit_06_ETM 0;
BA_ "GenSigTimeoutTime_GNMM" SG_ 2651930660 Digit_06_ETM 0;
BA_ "GenSigTimeoutTime_HCP" SG_ 2651930660 Digit_06_ETM 0;
BA_ "GenSigTimeoutTime_IPC" SG_ 2651930660 Digit_06_ETM 0;
BA_ "GenSigTimeoutTime_RFHM" SG_ 2651930660 Digit_06_ETM 0;
BA_ "GenSigTimeoutTime_SGW" SG_ 2651930660 Digit_06_ETM 0;
BA_ "GenSigTimeoutTime_TCM" SG_ 2651930660 Digit_06_ETM 0;
BA_ "GenSigTimeoutTime_AGSM" SG_ 2651930660 Digit_07_ETM 0;
BA_ "GenSigTimeoutTime_BSM" SG_ 2651930660 Digit_07_ETM 0;
BA_ "GenSigTimeoutTime_CADM" SG_ 2651930660 Digit_07_ETM 0;
BA_ "GenSigTimeoutTime_DMSM" SG_ 2651930660 Digit_07_ETM 0;
BA_ "GenSigTimeoutTime_DTCM" SG_ 2651930660 Digit_07_ETM 0;
BA_ "GenSigTimeoutTime_ECM" SG_ 2651930660 Digit_07_ETM 0;
BA_ "GenSigTimeoutTime_EVCU2" SG_ 2651930660 Digit_07_ETM 0;
BA_ "GenSigTimeoutTime_GNMM" SG_ 2651930660 Digit_07_ETM 0;
BA_ "GenSigTimeoutTime_HCP" SG_ 2651930660 Digit_07_ETM 0;
BA_ "GenSigTimeoutTime_IPC" SG_ 2651930660 Digit_07_ETM 0;
BA_ "GenSigTimeoutTime_RFHM" SG_ 2651930660 Digit_07_ETM 0;
BA_ "GenSigTimeoutTime_SGW" SG_ 2651930660 Digit_07_ETM 0;
BA_ "GenSigTimeoutTime_TCM" SG_ 2651930660 Digit_07_ETM 0;
BA_ "GenSigTimeoutTime_AGSM" SG_ 2651930660 Digit_08_ETM 0;
BA_ "GenSigTimeoutTime_BSM" SG_ 2651930660 Digit_08_ETM 0;
BA_ "GenSigTimeoutTime_CADM" SG_ 2651930660 Digit_08_ETM 0;
BA_ "GenSigTimeoutTime_DMSM" SG_ 2651930660 Digit_08_ETM 0;
BA_ "GenSigTimeoutTime_DTCM" SG_ 2651930660 Digit_08_ETM 0;
BA_ "GenSigTimeoutTime_ECM" SG_ 2651930660 Digit_08_ETM 0;
BA_ "GenSigTimeoutTime_EVCU2" SG_ 2651930660 Digit_08_ETM 0;
BA_ "GenSigTimeoutTime_GNMM" SG_ 2651930660 Digit_08_ETM 0;
BA_ "GenSigTimeoutTime_HCP" SG_ 2651930660 Digit_08_ETM 0;
BA_ "GenSigTimeoutTime_IPC" SG_ 2651930660 Digit_08_ETM 0;
BA_ "GenSigTimeoutTime_RFHM" SG_ 2651930660 Digit_08_ETM 0;
BA_ "GenSigTimeoutTime_SGW" SG_ 2651930660 Digit_08_ETM 0;
BA_ "GenSigTimeoutTime_TCM" SG_ 2651930660 Digit_08_ETM 0;
BA_ "GenSigTimeoutTime_AGSM" SG_ 2651930660 Digit_09_ETM 0;
BA_ "GenSigTimeoutTime_BSM" SG_ 2651930660 Digit_09_ETM 0;
BA_ "GenSigTimeoutTime_CADM" SG_ 2651930660 Digit_09_ETM 0;
BA_ "GenSigTimeoutTime_DMSM" SG_ 2651930660 Digit_09_ETM 0;
BA_ "GenSigTimeoutTime_DTCM" SG_ 2651930660 Digit_09_ETM 0;
BA_ "GenSigTimeoutTime_ECM" SG_ 2651930660 Digit_09_ETM 0;
BA_ "GenSigTimeoutTime_EVCU2" SG_ 2651930660 Digit_09_ETM 0;
BA_ "GenSigTimeoutTime_GNMM" SG_ 2651930660 Digit_09_ETM 0;
BA_ "GenSigTimeoutTime_HCP" SG_ 2651930660 Digit_09_ETM 0;
BA_ "GenSigTimeoutTime_IPC" SG_ 2651930660 Digit_09_ETM 0;
BA_ "GenSigTimeoutTime_RFHM" SG_ 2651930660 Digit_09_ETM 0;
BA_ "GenSigTimeoutTime_SGW" SG_ 2651930660 Digit_09_ETM 0;
BA_ "GenSigTimeoutTime_TCM" SG_ 2651930660 Digit_09_ETM 0;
BA_ "GenSigTimeoutTime_AGSM" SG_ 2651930660 Digit_10_ETM 0;
BA_ "GenSigTimeoutTime_BSM" SG_ 2651930660 Digit_10_ETM 0;
BA_ "GenSigTimeoutTime_CADM" SG_ 2651930660 Digit_10_ETM 0;
BA_ "GenSigTimeoutTime_DMSM" SG_ 2651930660 Digit_10_ETM 0;
BA_ "GenSigTimeoutTime_DTCM" SG_ 2651930660 Digit_10_ETM 0;
BA_ "GenSigTimeoutTime_ECM" SG_ 2651930660 Digit_10_ETM 0;
BA_ "GenSigTimeoutTime_EVCU2" SG_ 2651930660 Digit_10_ETM 0;
BA_ "GenSigTimeoutTime_GNMM" SG_ 2651930660 Digit_10_ETM 0;
BA_ "GenSigTimeoutTime_HCP" SG_ 2651930660 Digit_10_ETM 0;
BA_ "GenSigTimeoutTime_IPC" SG_ 2651930660 Digit_10_ETM 0;
BA_ "GenSigTimeoutTime_RFHM" SG_ 2651930660 Digit_10_ETM 0;
BA_ "GenSigTimeoutTime_SGW" SG_ 2651930660 Digit_10_ETM 0;
BA_ "GenSigTimeoutTime_TCM" SG_ 2651930660 Digit_10_ETM 0;
BA_ "GenSigTimeoutTime_AGSM" SG_ 2651930660 Digit_11_ETM 0;
BA_ "GenSigTimeoutTime_BSM" SG_ 2651930660 Digit_11_ETM 0;
BA_ "GenSigTimeoutTime_CADM" SG_ 2651930660 Digit_11_ETM 0;
BA_ "GenSigTimeoutTime_DMSM" SG_ 2651930660 Digit_11_ETM 0;
BA_ "GenSigTimeoutTime_DTCM" SG_ 2651930660 Digit_11_ETM 0;
BA_ "GenSigTimeoutTime_ECM" SG_ 2651930660 Digit_11_ETM 0;
BA_ "GenSigTimeoutTime_EVCU2" SG_ 2651930660 Digit_11_ETM 0;
BA_ "GenSigTimeoutTime_GNMM" SG_ 2651930660 Digit_11_ETM 0;
BA_ "GenSigTimeoutTime_HCP" SG_ 2651930660 Digit_11_ETM 0;
BA_ "GenSigTimeoutTime_IPC" SG_ 2651930660 Digit_11_ETM 0;
BA_ "GenSigTimeoutTime_RFHM" SG_ 2651930660 Digit_11_ETM 0;
BA_ "GenSigTimeoutTime_SGW" SG_ 2651930660 Digit_11_ETM 0;
BA_ "GenSigTimeoutTime_TCM" SG_ 2651930660 Digit_11_ETM 0;
BA_ "GenSigSendType" SG_ 2651930688 Digit_01_EVCU2 1;
BA_ "GenSigTimeoutTime_AGSM" SG_ 2651930688 Digit_01_EVCU2 0;
BA_ "GenSigTimeoutTime_BSM" SG_ 2651930688 Digit_01_EVCU2 0;
BA_ "GenSigTimeoutTime_CADM" SG_ 2651930688 Digit_01_EVCU2 0;
BA_ "GenSigTimeoutTime_DMSM" SG_ 2651930688 Digit_01_EVCU2 0;
BA_ "GenSigTimeoutTime_DTCM" SG_ 2651930688 Digit_01_EVCU2 0;
BA_ "GenSigTimeoutTime_ECM" SG_ 2651930688 Digit_01_EVCU2 0;
BA_ "GenSigTimeoutTime_EVCU2" SG_ 2651930688 Digit_01_EVCU2 0;
BA_ "GenSigTimeoutTime_GNMM" SG_ 2651930688 Digit_01_EVCU2 0;
BA_ "GenSigTimeoutTime_HCP" SG_ 2651930688 Digit_01_EVCU2 0;
BA_ "GenSigTimeoutTime_IPC" SG_ 2651930688 Digit_01_EVCU2 0;
BA_ "GenSigTimeoutTime_RFHM" SG_ 2651930688 Digit_01_EVCU2 0;
BA_ "GenSigTimeoutTime_SGW" SG_ 2651930688 Digit_01_EVCU2 0;
BA_ "GenSigTimeoutTime_TCM" SG_ 2651930688 Digit_01_EVCU2 0;
BA_ "GenSigTimeoutTime_AGSM" SG_ 2651930688 Digit_02_EVCU2 0;
BA_ "GenSigTimeoutTime_BSM" SG_ 2651930688 Digit_02_EVCU2 0;
BA_ "GenSigTimeoutTime_CADM" SG_ 2651930688 Digit_02_EVCU2 0;
BA_ "GenSigTimeoutTime_DMSM" SG_ 2651930688 Digit_02_EVCU2 0;
BA_ "GenSigTimeoutTime_DTCM" SG_ 2651930688 Digit_02_EVCU2 0;
BA_ "GenSigTimeoutTime_ECM" SG_ 2651930688 Digit_02_EVCU2 0;
BA_ "GenSigTimeoutTime_EVCU2" SG_ 2651930688 Digit_02_EVCU2 0;
BA_ "GenSigTimeoutTime_GNMM" SG_ 2651930688 Digit_02_EVCU2 0;
BA_ "GenSigTimeoutTime_HCP" SG_ 2651930688 Digit_02_EVCU2 0;
BA_ "GenSigTimeoutTime_IPC" SG_ 2651930688 Digit_02_EVCU2 0;
BA_ "GenSigTimeoutTime_RFHM" SG_ 2651930688 Digit_02_EVCU2 0;
BA_ "GenSigTimeoutTime_SGW" SG_ 2651930688 Digit_02_EVCU2 0;
BA_ "GenSigTimeoutTime_TCM" SG_ 2651930688 Digit_02_EVCU2 0;
BA_ "GenSigTimeoutTime_AGSM" SG_ 2651930688 Digit_03_EVCU2 0;
BA_ "GenSigTimeoutTime_BSM" SG_ 2651930688 Digit_03_EVCU2 0;
BA_ "GenSigTimeoutTime_CADM" SG_ 2651930688 Digit_03_EVCU2 0;
BA_ "GenSigTimeoutTime_DMSM" SG_ 2651930688 Digit_03_EVCU2 0;
BA_ "GenSigTimeoutTime_DTCM" SG_ 2651930688 Digit_03_EVCU2 0;
BA_ "GenSigTimeoutTime_ECM" SG_ 2651930688 Digit_03_EVCU2 0;
BA_ "GenSigTimeoutTime_EVCU2" SG_ 2651930688 Digit_03_EVCU2 0;
BA_ "GenSigTimeoutTime_GNMM" SG_ 2651930688 Digit_03_EVCU2 0;
BA_ "GenSigTimeoutTime_HCP" SG_ 2651930688 Digit_03_EVCU2 0;
BA_ "GenSigTimeoutTime_IPC" SG_ 2651930688 Digit_03_EVCU2 0;
BA_ "GenSigTimeoutTime_RFHM" SG_ 2651930688 Digit_03_EVCU2 0;
BA_ "GenSigTimeoutTime_SGW" SG_ 2651930688 Digit_03_EVCU2 0;
BA_ "GenSigTimeoutTime_TCM" SG_ 2651930688 Digit_03_EVCU2 0;
BA_ "GenSigTimeoutTime_AGSM" SG_ 2651930688 Digit_04_EVCU2 0;
BA_ "GenSigTimeoutTime_BSM" SG_ 2651930688 Digit_04_EVCU2 0;
BA_ "GenSigTimeoutTime_CADM" SG_ 2651930688 Digit_04_EVCU2 0;
BA_ "GenSigTimeoutTime_DMSM" SG_ 2651930688 Digit_04_EVCU2 0;
BA_ "GenSigTimeoutTime_DTCM" SG_ 2651930688 Digit_04_EVCU2 0;
BA_ "GenSigTimeoutTime_ECM" SG_ 2651930688 Digit_04_EVCU2 0;
BA_ "GenSigTimeoutTime_EVCU2" SG_ 2651930688 Digit_04_EVCU2 0;
BA_ "GenSigTimeoutTime_GNMM" SG_ 2651930688 Digit_04_EVCU2 0;
BA_ "GenSigTimeoutTime_HCP" SG_ 2651930688 Digit_04_EVCU2 0;
BA_ "GenSigTimeoutTime_IPC" SG_ 2651930688 Digit_04_EVCU2 0;
BA_ "GenSigTimeoutTime_RFHM" SG_ 2651930688 Digit_04_EVCU2 0;
BA_ "GenSigTimeoutTime_SGW" SG_ 2651930688 Digit_04_EVCU2 0;
BA_ "GenSigTimeoutTime_TCM" SG_ 2651930688 Digit_04_EVCU2 0;
BA_ "GenSigTimeoutTime_AGSM" SG_ 2651930688 Digit_05_EVCU2 0;
BA_ "GenSigTimeoutTime_BSM" SG_ 2651930688 Digit_05_EVCU2 0;
BA_ "GenSigTimeoutTime_CADM" SG_ 2651930688 Digit_05_EVCU2 0;
BA_ "GenSigTimeoutTime_DMSM" SG_ 2651930688 Digit_05_EVCU2 0;
BA_ "GenSigTimeoutTime_DTCM" SG_ 2651930688 Digit_05_EVCU2 0;
BA_ "GenSigTimeoutTime_ECM" SG_ 2651930688 Digit_05_EVCU2 0;
BA_ "GenSigTimeoutTime_EVCU2" SG_ 2651930688 Digit_05_EVCU2 0;
BA_ "GenSigTimeoutTime_GNMM" SG_ 2651930688 Digit_05_EVCU2 0;
BA_ "GenSigTimeoutTime_HCP" SG_ 2651930688 Digit_05_EVCU2 0;
BA_ "GenSigTimeoutTime_IPC" SG_ 2651930688 Digit_05_EVCU2 0;
BA_ "GenSigTimeoutTime_RFHM" SG_ 2651930688 Digit_05_EVCU2 0;
BA_ "GenSigTimeoutTime_SGW" SG_ 2651930688 Digit_05_EVCU2 0;
BA_ "GenSigTimeoutTime_TCM" SG_ 2651930688 Digit_05_EVCU2 0;
BA_ "GenSigTimeoutTime_AGSM" SG_ 2651930688 Digit_06_EVCU2 0;
BA_ "GenSigTimeoutTime_BSM" SG_ 2651930688 Digit_06_EVCU2 0;
BA_ "GenSigTimeoutTime_CADM" SG_ 2651930688 Digit_06_EVCU2 0;
BA_ "GenSigTimeoutTime_DMSM" SG_ 2651930688 Digit_06_EVCU2 0;
BA_ "GenSigTimeoutTime_DTCM" SG_ 2651930688 Digit_06_EVCU2 0;
BA_ "GenSigTimeoutTime_ECM" SG_ 2651930688 Digit_06_EVCU2 0;
BA_ "GenSigTimeoutTime_EVCU2" SG_ 2651930688 Digit_06_EVCU2 0;
BA_ "GenSigTimeoutTime_GNMM" SG_ 2651930688 Digit_06_EVCU2 0;
BA_ "GenSigTimeoutTime_HCP" SG_ 2651930688 Digit_06_EVCU2 0;
BA_ "GenSigTimeoutTime_IPC" SG_ 2651930688 Digit_06_EVCU2 0;
BA_ "GenSigTimeoutTime_RFHM" SG_ 2651930688 Digit_06_EVCU2 0;
BA_ "GenSigTimeoutTime_SGW" SG_ 2651930688 Digit_06_EVCU2 0;
BA_ "GenSigTimeoutTime_TCM" SG_ 2651930688 Digit_06_EVCU2 0;
BA_ "GenSigTimeoutTime_AGSM" SG_ 2651930688 Digit_07_EVCU2 0;
BA_ "GenSigTimeoutTime_BSM" SG_ 2651930688 Digit_07_EVCU2 0;
BA_ "GenSigTimeoutTime_CADM" SG_ 2651930688 Digit_07_EVCU2 0;
BA_ "GenSigTimeoutTime_DMSM" SG_ 2651930688 Digit_07_EVCU2 0;
BA_ "GenSigTimeoutTime_DTCM" SG_ 2651930688 Digit_07_EVCU2 0;
BA_ "GenSigTimeoutTime_ECM" SG_ 2651930688 Digit_07_EVCU2 0;
BA_ "GenSigTimeoutTime_EVCU2" SG_ 2651930688 Digit_07_EVCU2 0;
BA_ "GenSigTimeoutTime_GNMM" SG_ 2651930688 Digit_07_EVCU2 0;
BA_ "GenSigTimeoutTime_HCP" SG_ 2651930688 Digit_07_EVCU2 0;
BA_ "GenSigTimeoutTime_IPC" SG_ 2651930688 Digit_07_EVCU2 0;
BA_ "GenSigTimeoutTime_RFHM" SG_ 2651930688 Digit_07_EVCU2 0;
BA_ "GenSigTimeoutTime_SGW" SG_ 2651930688 Digit_07_EVCU2 0;
BA_ "GenSigTimeoutTime_TCM" SG_ 2651930688 Digit_07_EVCU2 0;
BA_ "GenSigTimeoutTime_AGSM" SG_ 2651930688 Digit_08_EVCU2 0;
BA_ "GenSigTimeoutTime_BSM" SG_ 2651930688 Digit_08_EVCU2 0;
BA_ "GenSigTimeoutTime_CADM" SG_ 2651930688 Digit_08_EVCU2 0;
BA_ "GenSigTimeoutTime_DMSM" SG_ 2651930688 Digit_08_EVCU2 0;
BA_ "GenSigTimeoutTime_DTCM" SG_ 2651930688 Digit_08_EVCU2 0;
BA_ "GenSigTimeoutTime_ECM" SG_ 2651930688 Digit_08_EVCU2 0;
BA_ "GenSigTimeoutTime_EVCU2" SG_ 2651930688 Digit_08_EVCU2 0;
BA_ "GenSigTimeoutTime_GNMM" SG_ 2651930688 Digit_08_EVCU2 0;
BA_ "GenSigTimeoutTime_HCP" SG_ 2651930688 Digit_08_EVCU2 0;
BA_ "GenSigTimeoutTime_IPC" SG_ 2651930688 Digit_08_EVCU2 0;
BA_ "GenSigTimeoutTime_RFHM" SG_ 2651930688 Digit_08_EVCU2 0;
BA_ "GenSigTimeoutTime_SGW" SG_ 2651930688 Digit_08_EVCU2 0;
BA_ "GenSigTimeoutTime_TCM" SG_ 2651930688 Digit_08_EVCU2 0;
BA_ "GenSigTimeoutTime_AGSM" SG_ 2651930688 Digit_09_EVCU2 0;
BA_ "GenSigTimeoutTime_BSM" SG_ 2651930688 Digit_09_EVCU2 0;
BA_ "GenSigTimeoutTime_CADM" SG_ 2651930688 Digit_09_EVCU2 0;
BA_ "GenSigTimeoutTime_DMSM" SG_ 2651930688 Digit_09_EVCU2 0;
BA_ "GenSigTimeoutTime_DTCM" SG_ 2651930688 Digit_09_EVCU2 0;
BA_ "GenSigTimeoutTime_ECM" SG_ 2651930688 Digit_09_EVCU2 0;
BA_ "GenSigTimeoutTime_EVCU2" SG_ 2651930688 Digit_09_EVCU2 0;
BA_ "GenSigTimeoutTime_GNMM" SG_ 2651930688 Digit_09_EVCU2 0;
BA_ "GenSigTimeoutTime_HCP" SG_ 2651930688 Digit_09_EVCU2 0;
BA_ "GenSigTimeoutTime_IPC" SG_ 2651930688 Digit_09_EVCU2 0;
BA_ "GenSigTimeoutTime_RFHM" SG_ 2651930688 Digit_09_EVCU2 0;
BA_ "GenSigTimeoutTime_SGW" SG_ 2651930688 Digit_09_EVCU2 0;
BA_ "GenSigTimeoutTime_TCM" SG_ 2651930688 Digit_09_EVCU2 0;
BA_ "GenSigTimeoutTime_AGSM" SG_ 2651930688 Digit_10_EVCU2 0;
BA_ "GenSigTimeoutTime_BSM" SG_ 2651930688 Digit_10_EVCU2 0;
BA_ "GenSigTimeoutTime_CADM" SG_ 2651930688 Digit_10_EVCU2 0;
BA_ "GenSigTimeoutTime_DMSM" SG_ 2651930688 Digit_10_EVCU2 0;
BA_ "GenSigTimeoutTime_DTCM" SG_ 2651930688 Digit_10_EVCU2 0;
BA_ "GenSigTimeoutTime_ECM" SG_ 2651930688 Digit_10_EVCU2 0;
BA_ "GenSigTimeoutTime_EVCU2" SG_ 2651930688 Digit_10_EVCU2 0;
BA_ "GenSigTimeoutTime_GNMM" SG_ 2651930688 Digit_10_EVCU2 0;
BA_ "GenSigTimeoutTime_HCP" SG_ 2651930688 Digit_10_EVCU2 0;
BA_ "GenSigTimeoutTime_IPC" SG_ 2651930688 Digit_10_EVCU2 0;
BA_ "GenSigTimeoutTime_RFHM" SG_ 2651930688 Digit_10_EVCU2 0;
BA_ "GenSigTimeoutTime_SGW" SG_ 2651930688 Digit_10_EVCU2 0;
BA_ "GenSigTimeoutTime_TCM" SG_ 2651930688 Digit_10_EVCU2 0;
BA_ "GenSigTimeoutTime_AGSM" SG_ 2651930688 Digit_11_EVCU2 0;
BA_ "GenSigTimeoutTime_BSM" SG_ 2651930688 Digit_11_EVCU2 0;
BA_ "GenSigTimeoutTime_CADM" SG_ 2651930688 Digit_11_EVCU2 0;
BA_ "GenSigTimeoutTime_DMSM" SG_ 2651930688 Digit_11_EVCU2 0;
BA_ "GenSigTimeoutTime_DTCM" SG_ 2651930688 Digit_11_EVCU2 0;
BA_ "GenSigTimeoutTime_ECM" SG_ 2651930688 Digit_11_EVCU2 0;
BA_ "GenSigTimeoutTime_EVCU2" SG_ 2651930688 Digit_11_EVCU2 0;
BA_ "GenSigTimeoutTime_GNMM" SG_ 2651930688 Digit_11_EVCU2 0;
BA_ "GenSigTimeoutTime_HCP" SG_ 2651930688 Digit_11_EVCU2 0;
BA_ "GenSigTimeoutTime_IPC" SG_ 2651930688 Digit_11_EVCU2 0;
BA_ "GenSigTimeoutTime_RFHM" SG_ 2651930688 Digit_11_EVCU2 0;
BA_ "GenSigTimeoutTime_SGW" SG_ 2651930688 Digit_11_EVCU2 0;
BA_ "GenSigTimeoutTime_TCM" SG_ 2651930688 Digit_11_EVCU2 0;
BA_ "GenSigSendType" SG_ 2651930768 Digit_01_GNMM 1;
BA_ "GenSigTimeoutTime_AGSM" SG_ 2651930768 Digit_01_GNMM 0;
BA_ "GenSigTimeoutTime_BSM" SG_ 2651930768 Digit_01_GNMM 0;
BA_ "GenSigTimeoutTime_CADM" SG_ 2651930768 Digit_01_GNMM 0;
BA_ "GenSigTimeoutTime_DMSM" SG_ 2651930768 Digit_01_GNMM 0;
BA_ "GenSigTimeoutTime_DTCM" SG_ 2651930768 Digit_01_GNMM 0;
BA_ "GenSigTimeoutTime_ECM" SG_ 2651930768 Digit_01_GNMM 0;
BA_ "GenSigTimeoutTime_EVCU2" SG_ 2651930768 Digit_01_GNMM 0;
BA_ "GenSigTimeoutTime_GNMM" SG_ 2651930768 Digit_01_GNMM 0;
BA_ "GenSigTimeoutTime_HCP" SG_ 2651930768 Digit_01_GNMM 0;
BA_ "GenSigTimeoutTime_IPC" SG_ 2651930768 Digit_01_GNMM 0;
BA_ "GenSigTimeoutTime_RFHM" SG_ 2651930768 Digit_01_GNMM 0;
BA_ "GenSigTimeoutTime_SGW" SG_ 2651930768 Digit_01_GNMM 0;
BA_ "GenSigTimeoutTime_TCM" SG_ 2651930768 Digit_01_GNMM 0;
BA_ "GenSigTimeoutTime_AGSM" SG_ 2651930768 Digit_02_GNMM 0;
BA_ "GenSigTimeoutTime_BSM" SG_ 2651930768 Digit_02_GNMM 0;
BA_ "GenSigTimeoutTime_CADM" SG_ 2651930768 Digit_02_GNMM 0;
BA_ "GenSigTimeoutTime_DMSM" SG_ 2651930768 Digit_02_GNMM 0;
BA_ "GenSigTimeoutTime_DTCM" SG_ 2651930768 Digit_02_GNMM 0;
BA_ "GenSigTimeoutTime_ECM" SG_ 2651930768 Digit_02_GNMM 0;
BA_ "GenSigTimeoutTime_EVCU2" SG_ 2651930768 Digit_02_GNMM 0;
BA_ "GenSigTimeoutTime_GNMM" SG_ 2651930768 Digit_02_GNMM 0;
BA_ "GenSigTimeoutTime_HCP" SG_ 2651930768 Digit_02_GNMM 0;
BA_ "GenSigTimeoutTime_IPC" SG_ 2651930768 Digit_02_GNMM 0;
BA_ "GenSigTimeoutTime_RFHM" SG_ 2651930768 Digit_02_GNMM 0;
BA_ "GenSigTimeoutTime_SGW" SG_ 2651930768 Digit_02_GNMM 0;
BA_ "GenSigTimeoutTime_TCM" SG_ 2651930768 Digit_02_GNMM 0;
BA_ "GenSigTimeoutTime_AGSM" SG_ 2651930768 Digit_03_GNMM 0;
BA_ "GenSigTimeoutTime_BSM" SG_ 2651930768 Digit_03_GNMM 0;
BA_ "GenSigTimeoutTime_CADM" SG_ 2651930768 Digit_03_GNMM 0;
BA_ "GenSigTimeoutTime_DMSM" SG_ 2651930768 Digit_03_GNMM 0;
BA_ "GenSigTimeoutTime_DTCM" SG_ 2651930768 Digit_03_GNMM 0;
BA_ "GenSigTimeoutTime_ECM" SG_ 2651930768 Digit_03_GNMM 0;
BA_ "GenSigTimeoutTime_EVCU2" SG_ 2651930768 Digit_03_GNMM 0;
BA_ "GenSigTimeoutTime_GNMM" SG_ 2651930768 Digit_03_GNMM 0;
BA_ "GenSigTimeoutTime_HCP" SG_ 2651930768 Digit_03_GNMM 0;
BA_ "GenSigTimeoutTime_IPC" SG_ 2651930768 Digit_03_GNMM 0;
BA_ "GenSigTimeoutTime_RFHM" SG_ 2651930768 Digit_03_GNMM 0;
BA_ "GenSigTimeoutTime_SGW" SG_ 2651930768 Digit_03_GNMM 0;
BA_ "GenSigTimeoutTime_TCM" SG_ 2651930768 Digit_03_GNMM 0;
BA_ "GenSigTimeoutTime_AGSM" SG_ 2651930768 Digit_04_GNMM 0;
BA_ "GenSigTimeoutTime_BSM" SG_ 2651930768 Digit_04_GNMM 0;
BA_ "GenSigTimeoutTime_CADM" SG_ 2651930768 Digit_04_GNMM 0;
BA_ "GenSigTimeoutTime_DMSM" SG_ 2651930768 Digit_04_GNMM 0;
BA_ "GenSigTimeoutTime_DTCM" SG_ 2651930768 Digit_04_GNMM 0;
BA_ "GenSigTimeoutTime_ECM" SG_ 2651930768 Digit_04_GNMM 0;
BA_ "GenSigTimeoutTime_EVCU2" SG_ 2651930768 Digit_04_GNMM 0;
BA_ "GenSigTimeoutTime_GNMM" SG_ 2651930768 Digit_04_GNMM 0;
BA_ "GenSigTimeoutTime_HCP" SG_ 2651930768 Digit_04_GNMM 0;
BA_ "GenSigTimeoutTime_IPC" SG_ 2651930768 Digit_04_GNMM 0;
BA_ "GenSigTimeoutTime_RFHM" SG_ 2651930768 Digit_04_GNMM 0;
BA_ "GenSigTimeoutTime_SGW" SG_ 2651930768 Digit_04_GNMM 0;
BA_ "GenSigTimeoutTime_TCM" SG_ 2651930768 Digit_04_GNMM 0;
BA_ "GenSigTimeoutTime_AGSM" SG_ 2651930768 Digit_05_GNMM 0;
BA_ "GenSigTimeoutTime_BSM" SG_ 2651930768 Digit_05_GNMM 0;
BA_ "GenSigTimeoutTime_CADM" SG_ 2651930768 Digit_05_GNMM 0;
BA_ "GenSigTimeoutTime_DMSM" SG_ 2651930768 Digit_05_GNMM 0;
BA_ "GenSigTimeoutTime_DTCM" SG_ 2651930768 Digit_05_GNMM 0;
BA_ "GenSigTimeoutTime_ECM" SG_ 2651930768 Digit_05_GNMM 0;
BA_ "GenSigTimeoutTime_EVCU2" SG_ 2651930768 Digit_05_GNMM 0;
BA_ "GenSigTimeoutTime_GNMM" SG_ 2651930768 Digit_05_GNMM 0;
BA_ "GenSigTimeoutTime_HCP" SG_ 2651930768 Digit_05_GNMM 0;
BA_ "GenSigTimeoutTime_IPC" SG_ 2651930768 Digit_05_GNMM 0;
BA_ "GenSigTimeoutTime_RFHM" SG_ 2651930768 Digit_05_GNMM 0;
BA_ "GenSigTimeoutTime_SGW" SG_ 2651930768 Digit_05_GNMM 0;
BA_ "GenSigTimeoutTime_TCM" SG_ 2651930768 Digit_05_GNMM 0;
BA_ "GenSigTimeoutTime_AGSM" SG_ 2651930768 Digit_06_GNMM 0;
BA_ "GenSigTimeoutTime_BSM" SG_ 2651930768 Digit_06_GNMM 0;
BA_ "GenSigTimeoutTime_CADM" SG_ 2651930768 Digit_06_GNMM 0;
BA_ "GenSigTimeoutTime_DMSM" SG_ 2651930768 Digit_06_GNMM 0;
BA_ "GenSigTimeoutTime_DTCM" SG_ 2651930768 Digit_06_GNMM 0;
BA_ "GenSigTimeoutTime_ECM" SG_ 2651930768 Digit_06_GNMM 0;
BA_ "GenSigTimeoutTime_EVCU2" SG_ 2651930768 Digit_06_GNMM 0;
BA_ "GenSigTimeoutTime_GNMM" SG_ 2651930768 Digit_06_GNMM 0;
BA_ "GenSigTimeoutTime_HCP" SG_ 2651930768 Digit_06_GNMM 0;
BA_ "GenSigTimeoutTime_IPC" SG_ 2651930768 Digit_06_GNMM 0;
BA_ "GenSigTimeoutTime_RFHM" SG_ 2651930768 Digit_06_GNMM 0;
BA_ "GenSigTimeoutTime_SGW" SG_ 2651930768 Digit_06_GNMM 0;
BA_ "GenSigTimeoutTime_TCM" SG_ 2651930768 Digit_06_GNMM 0;
BA_ "GenSigTimeoutTime_AGSM" SG_ 2651930768 Digit_07_GNMM 0;
BA_ "GenSigTimeoutTime_BSM" SG_ 2651930768 Digit_07_GNMM 0;
BA_ "GenSigTimeoutTime_CADM" SG_ 2651930768 Digit_07_GNMM 0;
BA_ "GenSigTimeoutTime_DMSM" SG_ 2651930768 Digit_07_GNMM 0;
BA_ "GenSigTimeoutTime_DTCM" SG_ 2651930768 Digit_07_GNMM 0;
BA_ "GenSigTimeoutTime_ECM" SG_ 2651930768 Digit_07_GNMM 0;
BA_ "GenSigTimeoutTime_EVCU2" SG_ 2651930768 Digit_07_GNMM 0;
BA_ "GenSigTimeoutTime_GNMM" SG_ 2651930768 Digit_07_GNMM 0;
BA_ "GenSigTimeoutTime_HCP" SG_ 2651930768 Digit_07_GNMM 0;
BA_ "GenSigTimeoutTime_IPC" SG_ 2651930768 Digit_07_GNMM 0;
BA_ "GenSigTimeoutTime_RFHM" SG_ 2651930768 Digit_07_GNMM 0;
BA_ "GenSigTimeoutTime_SGW" SG_ 2651930768 Digit_07_GNMM 0;
BA_ "GenSigTimeoutTime_TCM" SG_ 2651930768 Digit_07_GNMM 0;
BA_ "GenSigTimeoutTime_AGSM" SG_ 2651930768 Digit_08_GNMM 0;
BA_ "GenSigTimeoutTime_BSM" SG_ 2651930768 Digit_08_GNMM 0;
BA_ "GenSigTimeoutTime_CADM" SG_ 2651930768 Digit_08_GNMM 0;
BA_ "GenSigTimeoutTime_DMSM" SG_ 2651930768 Digit_08_GNMM 0;
BA_ "GenSigTimeoutTime_DTCM" SG_ 2651930768 Digit_08_GNMM 0;
BA_ "GenSigTimeoutTime_ECM" SG_ 2651930768 Digit_08_GNMM 0;
BA_ "GenSigTimeoutTime_EVCU2" SG_ 2651930768 Digit_08_GNMM 0;
BA_ "GenSigTimeoutTime_GNMM" SG_ 2651930768 Digit_08_GNMM 0;
BA_ "GenSigTimeoutTime_HCP" SG_ 2651930768 Digit_08_GNMM 0;
BA_ "GenSigTimeoutTime_IPC" SG_ 2651930768 Digit_08_GNMM 0;
BA_ "GenSigTimeoutTime_RFHM" SG_ 2651930768 Digit_08_GNMM 0;
BA_ "GenSigTimeoutTime_SGW" SG_ 2651930768 Digit_08_GNMM 0;
BA_ "GenSigTimeoutTime_TCM" SG_ 2651930768 Digit_08_GNMM 0;
BA_ "GenSigTimeoutTime_AGSM" SG_ 2651930768 Digit_09_GNMM 0;
BA_ "GenSigTimeoutTime_BSM" SG_ 2651930768 Digit_09_GNMM 0;
BA_ "GenSigTimeoutTime_CADM" SG_ 2651930768 Digit_09_GNMM 0;
BA_ "GenSigTimeoutTime_DMSM" SG_ 2651930768 Digit_09_GNMM 0;
BA_ "GenSigTimeoutTime_DTCM" SG_ 2651930768 Digit_09_GNMM 0;
BA_ "GenSigTimeoutTime_ECM" SG_ 2651930768 Digit_09_GNMM 0;
BA_ "GenSigTimeoutTime_EVCU2" SG_ 2651930768 Digit_09_GNMM 0;
BA_ "GenSigTimeoutTime_GNMM" SG_ 2651930768 Digit_09_GNMM 0;
BA_ "GenSigTimeoutTime_HCP" SG_ 2651930768 Digit_09_GNMM 0;
BA_ "GenSigTimeoutTime_IPC" SG_ 2651930768 Digit_09_GNMM 0;
BA_ "GenSigTimeoutTime_RFHM" SG_ 2651930768 Digit_09_GNMM 0;
BA_ "GenSigTimeoutTime_SGW" SG_ 2651930768 Digit_09_GNMM 0;
BA_ "GenSigTimeoutTime_TCM" SG_ 2651930768 Digit_09_GNMM 0;
BA_ "GenSigTimeoutTime_AGSM" SG_ 2651930768 Digit_10_GNMM 0;
BA_ "GenSigTimeoutTime_BSM" SG_ 2651930768 Digit_10_GNMM 0;
BA_ "GenSigTimeoutTime_CADM" SG_ 2651930768 Digit_10_GNMM 0;
BA_ "GenSigTimeoutTime_DMSM" SG_ 2651930768 Digit_10_GNMM 0;
BA_ "GenSigTimeoutTime_DTCM" SG_ 2651930768 Digit_10_GNMM 0;
BA_ "GenSigTimeoutTime_ECM" SG_ 2651930768 Digit_10_GNMM 0;
BA_ "GenSigTimeoutTime_EVCU2" SG_ 2651930768 Digit_10_GNMM 0;
BA_ "GenSigTimeoutTime_GNMM" SG_ 2651930768 Digit_10_GNMM 0;
BA_ "GenSigTimeoutTime_HCP" SG_ 2651930768 Digit_10_GNMM 0;
BA_ "GenSigTimeoutTime_IPC" SG_ 2651930768 Digit_10_GNMM 0;
BA_ "GenSigTimeoutTime_RFHM" SG_ 2651930768 Digit_10_GNMM 0;
BA_ "GenSigTimeoutTime_SGW" SG_ 2651930768 Digit_10_GNMM 0;
BA_ "GenSigTimeoutTime_TCM" SG_ 2651930768 Digit_10_GNMM 0;
BA_ "GenSigTimeoutTime_AGSM" SG_ 2651930768 Digit_11_GNMM 0;
BA_ "GenSigTimeoutTime_BSM" SG_ 2651930768 Digit_11_GNMM 0;
BA_ "GenSigTimeoutTime_CADM" SG_ 2651930768 Digit_11_GNMM 0;
BA_ "GenSigTimeoutTime_DMSM" SG_ 2651930768 Digit_11_GNMM 0;
BA_ "GenSigTimeoutTime_DTCM" SG_ 2651930768 Digit_11_GNMM 0;
BA_ "GenSigTimeoutTime_ECM" SG_ 2651930768 Digit_11_GNMM 0;
BA_ "GenSigTimeoutTime_EVCU2" SG_ 2651930768 Digit_11_GNMM 0;
BA_ "GenSigTimeoutTime_GNMM" SG_ 2651930768 Digit_11_GNMM 0;
BA_ "GenSigTimeoutTime_HCP" SG_ 2651930768 Digit_11_GNMM 0;
BA_ "GenSigTimeoutTime_IPC" SG_ 2651930768 Digit_11_GNMM 0;
BA_ "GenSigTimeoutTime_RFHM" SG_ 2651930768 Digit_11_GNMM 0;
BA_ "GenSigTimeoutTime_SGW" SG_ 2651930768 Digit_11_GNMM 0;
BA_ "GenSigTimeoutTime_TCM" SG_ 2651930768 Digit_11_GNMM 0;
BA_ "GenSigSendType" SG_ 2651930722 Digit_01_HCP 1;
BA_ "GenSigTimeoutTime_AGSM" SG_ 2651930722 Digit_01_HCP 0;
BA_ "GenSigTimeoutTime_BSM" SG_ 2651930722 Digit_01_HCP 0;
BA_ "GenSigTimeoutTime_CADM" SG_ 2651930722 Digit_01_HCP 0;
BA_ "GenSigTimeoutTime_DMSM" SG_ 2651930722 Digit_01_HCP 0;
BA_ "GenSigTimeoutTime_DTCM" SG_ 2651930722 Digit_01_HCP 0;
BA_ "GenSigTimeoutTime_ECM" SG_ 2651930722 Digit_01_HCP 0;
BA_ "GenSigTimeoutTime_EVCU2" SG_ 2651930722 Digit_01_HCP 0;
BA_ "GenSigTimeoutTime_GNMM" SG_ 2651930722 Digit_01_HCP 0;
BA_ "GenSigTimeoutTime_HCP" SG_ 2651930722 Digit_01_HCP 0;
BA_ "GenSigTimeoutTime_IPC" SG_ 2651930722 Digit_01_HCP 0;
BA_ "GenSigTimeoutTime_RFHM" SG_ 2651930722 Digit_01_HCP 0;
BA_ "GenSigTimeoutTime_SGW" SG_ 2651930722 Digit_01_HCP 0;
BA_ "GenSigTimeoutTime_TCM" SG_ 2651930722 Digit_01_HCP 0;
BA_ "GenSigTimeoutTime_AGSM" SG_ 2651930722 Digit_02_HCP 0;
BA_ "GenSigTimeoutTime_BSM" SG_ 2651930722 Digit_02_HCP 0;
BA_ "GenSigTimeoutTime_CADM" SG_ 2651930722 Digit_02_HCP 0;
BA_ "GenSigTimeoutTime_DMSM" SG_ 2651930722 Digit_02_HCP 0;
BA_ "GenSigTimeoutTime_DTCM" SG_ 2651930722 Digit_02_HCP 0;
BA_ "GenSigTimeoutTime_ECM" SG_ 2651930722 Digit_02_HCP 0;
BA_ "GenSigTimeoutTime_EVCU2" SG_ 2651930722 Digit_02_HCP 0;
BA_ "GenSigTimeoutTime_GNMM" SG_ 2651930722 Digit_02_HCP 0;
BA_ "GenSigTimeoutTime_HCP" SG_ 2651930722 Digit_02_HCP 0;
BA_ "GenSigTimeoutTime_IPC" SG_ 2651930722 Digit_02_HCP 0;
BA_ "GenSigTimeoutTime_RFHM" SG_ 2651930722 Digit_02_HCP 0;
BA_ "GenSigTimeoutTime_SGW" SG_ 2651930722 Digit_02_HCP 0;
BA_ "GenSigTimeoutTime_TCM" SG_ 2651930722 Digit_02_HCP 0;
BA_ "GenSigTimeoutTime_AGSM" SG_ 2651930722 Digit_03_HCP 0;
BA_ "GenSigTimeoutTime_BSM" SG_ 2651930722 Digit_03_HCP 0;
BA_ "GenSigTimeoutTime_CADM" SG_ 2651930722 Digit_03_HCP 0;
BA_ "GenSigTimeoutTime_DMSM" SG_ 2651930722 Digit_03_HCP 0;
BA_ "GenSigTimeoutTime_DTCM" SG_ 2651930722 Digit_03_HCP 0;
BA_ "GenSigTimeoutTime_ECM" SG_ 2651930722 Digit_03_HCP 0;
BA_ "GenSigTimeoutTime_EVCU2" SG_ 2651930722 Digit_03_HCP 0;
BA_ "GenSigTimeoutTime_GNMM" SG_ 2651930722 Digit_03_HCP 0;
BA_ "GenSigTimeoutTime_HCP" SG_ 2651930722 Digit_03_HCP 0;
BA_ "GenSigTimeoutTime_IPC" SG_ 2651930722 Digit_03_HCP 0;
BA_ "GenSigTimeoutTime_RFHM" SG_ 2651930722 Digit_03_HCP 0;
BA_ "GenSigTimeoutTime_SGW" SG_ 2651930722 Digit_03_HCP 0;
BA_ "GenSigTimeoutTime_TCM" SG_ 2651930722 Digit_03_HCP 0;
BA_ "GenSigTimeoutTime_AGSM" SG_ 2651930722 Digit_04_HCP 0;
BA_ "GenSigTimeoutTime_BSM" SG_ 2651930722 Digit_04_HCP 0;
BA_ "GenSigTimeoutTime_CADM" SG_ 2651930722 Digit_04_HCP 0;
BA_ "GenSigTimeoutTime_DMSM" SG_ 2651930722 Digit_04_HCP 0;
BA_ "GenSigTimeoutTime_DTCM" SG_ 2651930722 Digit_04_HCP 0;
BA_ "GenSigTimeoutTime_ECM" SG_ 2651930722 Digit_04_HCP 0;
BA_ "GenSigTimeoutTime_EVCU2" SG_ 2651930722 Digit_04_HCP 0;
BA_ "GenSigTimeoutTime_GNMM" SG_ 2651930722 Digit_04_HCP 0;
BA_ "GenSigTimeoutTime_HCP" SG_ 2651930722 Digit_04_HCP 0;
BA_ "GenSigTimeoutTime_IPC" SG_ 2651930722 Digit_04_HCP 0;
BA_ "GenSigTimeoutTime_RFHM" SG_ 2651930722 Digit_04_HCP 0;
BA_ "GenSigTimeoutTime_SGW" SG_ 2651930722 Digit_04_HCP 0;
BA_ "GenSigTimeoutTime_TCM" SG_ 2651930722 Digit_04_HCP 0;
BA_ "GenSigTimeoutTime_AGSM" SG_ 2651930722 Digit_05_HCP 0;
BA_ "GenSigTimeoutTime_BSM" SG_ 2651930722 Digit_05_HCP 0;
BA_ "GenSigTimeoutTime_CADM" SG_ 2651930722 Digit_05_HCP 0;
BA_ "GenSigTimeoutTime_DMSM" SG_ 2651930722 Digit_05_HCP 0;
BA_ "GenSigTimeoutTime_DTCM" SG_ 2651930722 Digit_05_HCP 0;
BA_ "GenSigTimeoutTime_ECM" SG_ 2651930722 Digit_05_HCP 0;
BA_ "GenSigTimeoutTime_EVCU2" SG_ 2651930722 Digit_05_HCP 0;
BA_ "GenSigTimeoutTime_GNMM" SG_ 2651930722 Digit_05_HCP 0;
BA_ "GenSigTimeoutTime_HCP" SG_ 2651930722 Digit_05_HCP 0;
BA_ "GenSigTimeoutTime_IPC" SG_ 2651930722 Digit_05_HCP 0;
BA_ "GenSigTimeoutTime_RFHM" SG_ 2651930722 Digit_05_HCP 0;
BA_ "GenSigTimeoutTime_SGW" SG_ 2651930722 Digit_05_HCP 0;
BA_ "GenSigTimeoutTime_TCM" SG_ 2651930722 Digit_05_HCP 0;
BA_ "GenSigTimeoutTime_AGSM" SG_ 2651930722 Digit_06_HCP 0;
BA_ "GenSigTimeoutTime_BSM" SG_ 2651930722 Digit_06_HCP 0;
BA_ "GenSigTimeoutTime_CADM" SG_ 2651930722 Digit_06_HCP 0;
BA_ "GenSigTimeoutTime_DMSM" SG_ 2651930722 Digit_06_HCP 0;
BA_ "GenSigTimeoutTime_DTCM" SG_ 2651930722 Digit_06_HCP 0;
BA_ "GenSigTimeoutTime_ECM" SG_ 2651930722 Digit_06_HCP 0;
BA_ "GenSigTimeoutTime_EVCU2" SG_ 2651930722 Digit_06_HCP 0;
BA_ "GenSigTimeoutTime_GNMM" SG_ 2651930722 Digit_06_HCP 0;
BA_ "GenSigTimeoutTime_HCP" SG_ 2651930722 Digit_06_HCP 0;
BA_ "GenSigTimeoutTime_IPC" SG_ 2651930722 Digit_06_HCP 0;
BA_ "GenSigTimeoutTime_RFHM" SG_ 2651930722 Digit_06_HCP 0;
BA_ "GenSigTimeoutTime_SGW" SG_ 2651930722 Digit_06_HCP 0;
BA_ "GenSigTimeoutTime_TCM" SG_ 2651930722 Digit_06_HCP 0;
BA_ "GenSigTimeoutTime_AGSM" SG_ 2651930722 Digit_07_HCP 0;
BA_ "GenSigTimeoutTime_BSM" SG_ 2651930722 Digit_07_HCP 0;
BA_ "GenSigTimeoutTime_CADM" SG_ 2651930722 Digit_07_HCP 0;
BA_ "GenSigTimeoutTime_DMSM" SG_ 2651930722 Digit_07_HCP 0;
BA_ "GenSigTimeoutTime_DTCM" SG_ 2651930722 Digit_07_HCP 0;
BA_ "GenSigTimeoutTime_ECM" SG_ 2651930722 Digit_07_HCP 0;
BA_ "GenSigTimeoutTime_EVCU2" SG_ 2651930722 Digit_07_HCP 0;
BA_ "GenSigTimeoutTime_GNMM" SG_ 2651930722 Digit_07_HCP 0;
BA_ "GenSigTimeoutTime_HCP" SG_ 2651930722 Digit_07_HCP 0;
BA_ "GenSigTimeoutTime_IPC" SG_ 2651930722 Digit_07_HCP 0;
BA_ "GenSigTimeoutTime_RFHM" SG_ 2651930722 Digit_07_HCP 0;
BA_ "GenSigTimeoutTime_SGW" SG_ 2651930722 Digit_07_HCP 0;
BA_ "GenSigTimeoutTime_TCM" SG_ 2651930722 Digit_07_HCP 0;
BA_ "GenSigTimeoutTime_AGSM" SG_ 2651930722 Digit_08_HCP 0;
BA_ "GenSigTimeoutTime_BSM" SG_ 2651930722 Digit_08_HCP 0;
BA_ "GenSigTimeoutTime_CADM" SG_ 2651930722 Digit_08_HCP 0;
BA_ "GenSigTimeoutTime_DMSM" SG_ 2651930722 Digit_08_HCP 0;
BA_ "GenSigTimeoutTime_DTCM" SG_ 2651930722 Digit_08_HCP 0;
BA_ "GenSigTimeoutTime_ECM" SG_ 2651930722 Digit_08_HCP 0;
BA_ "GenSigTimeoutTime_EVCU2" SG_ 2651930722 Digit_08_HCP 0;
BA_ "GenSigTimeoutTime_GNMM" SG_ 2651930722 Digit_08_HCP 0;
BA_ "GenSigTimeoutTime_HCP" SG_ 2651930722 Digit_08_HCP 0;
BA_ "GenSigTimeoutTime_IPC" SG_ 2651930722 Digit_08_HCP 0;
BA_ "GenSigTimeoutTime_RFHM" SG_ 2651930722 Digit_08_HCP 0;
BA_ "GenSigTimeoutTime_SGW" SG_ 2651930722 Digit_08_HCP 0;
BA_ "GenSigTimeoutTime_TCM" SG_ 2651930722 Digit_08_HCP 0;
BA_ "GenSigTimeoutTime_AGSM" SG_ 2651930722 Digit_09_HCP 0;
BA_ "GenSigTimeoutTime_BSM" SG_ 2651930722 Digit_09_HCP 0;
BA_ "GenSigTimeoutTime_CADM" SG_ 2651930722 Digit_09_HCP 0;
BA_ "GenSigTimeoutTime_DMSM" SG_ 2651930722 Digit_09_HCP 0;
BA_ "GenSigTimeoutTime_DTCM" SG_ 2651930722 Digit_09_HCP 0;
BA_ "GenSigTimeoutTime_ECM" SG_ 2651930722 Digit_09_HCP 0;
BA_ "GenSigTimeoutTime_EVCU2" SG_ 2651930722 Digit_09_HCP 0;
BA_ "GenSigTimeoutTime_GNMM" SG_ 2651930722 Digit_09_HCP 0;
BA_ "GenSigTimeoutTime_HCP" SG_ 2651930722 Digit_09_HCP 0;
BA_ "GenSigTimeoutTime_IPC" SG_ 2651930722 Digit_09_HCP 0;
BA_ "GenSigTimeoutTime_RFHM" SG_ 2651930722 Digit_09_HCP 0;
BA_ "GenSigTimeoutTime_SGW" SG_ 2651930722 Digit_09_HCP 0;
BA_ "GenSigTimeoutTime_TCM" SG_ 2651930722 Digit_09_HCP 0;
BA_ "GenSigTimeoutTime_AGSM" SG_ 2651930722 Digit_10_HCP 0;
BA_ "GenSigTimeoutTime_BSM" SG_ 2651930722 Digit_10_HCP 0;
BA_ "GenSigTimeoutTime_CADM" SG_ 2651930722 Digit_10_HCP 0;
BA_ "GenSigTimeoutTime_DMSM" SG_ 2651930722 Digit_10_HCP 0;
BA_ "GenSigTimeoutTime_DTCM" SG_ 2651930722 Digit_10_HCP 0;
BA_ "GenSigTimeoutTime_ECM" SG_ 2651930722 Digit_10_HCP 0;
BA_ "GenSigTimeoutTime_EVCU2" SG_ 2651930722 Digit_10_HCP 0;
BA_ "GenSigTimeoutTime_GNMM" SG_ 2651930722 Digit_10_HCP 0;
BA_ "GenSigTimeoutTime_HCP" SG_ 2651930722 Digit_10_HCP 0;
BA_ "GenSigTimeoutTime_IPC" SG_ 2651930722 Digit_10_HCP 0;
BA_ "GenSigTimeoutTime_RFHM" SG_ 2651930722 Digit_10_HCP 0;
BA_ "GenSigTimeoutTime_SGW" SG_ 2651930722 Digit_10_HCP 0;
BA_ "GenSigTimeoutTime_TCM" SG_ 2651930722 Digit_10_HCP 0;
BA_ "GenSigTimeoutTime_AGSM" SG_ 2651930722 Digit_11_HCP 0;
BA_ "GenSigTimeoutTime_BSM" SG_ 2651930722 Digit_11_HCP 0;
BA_ "GenSigTimeoutTime_CADM" SG_ 2651930722 Digit_11_HCP 0;
BA_ "GenSigTimeoutTime_DMSM" SG_ 2651930722 Digit_11_HCP 0;
BA_ "GenSigTimeoutTime_DTCM" SG_ 2651930722 Digit_11_HCP 0;
BA_ "GenSigTimeoutTime_ECM" SG_ 2651930722 Digit_11_HCP 0;
BA_ "GenSigTimeoutTime_EVCU2" SG_ 2651930722 Digit_11_HCP 0;
BA_ "GenSigTimeoutTime_GNMM" SG_ 2651930722 Digit_11_HCP 0;
BA_ "GenSigTimeoutTime_HCP" SG_ 2651930722 Digit_11_HCP 0;
BA_ "GenSigTimeoutTime_IPC" SG_ 2651930722 Digit_11_HCP 0;
BA_ "GenSigTimeoutTime_RFHM" SG_ 2651930722 Digit_11_HCP 0;
BA_ "GenSigTimeoutTime_SGW" SG_ 2651930722 Digit_11_HCP 0;
BA_ "GenSigTimeoutTime_TCM" SG_ 2651930722 Digit_11_HCP 0;
BA_ "GenSigSendType" SG_ 2651930749 Digit_01_IDCM 1;
BA_ "GenSigTimeoutTime_AGSM" SG_ 2651930749 Digit_01_IDCM 0;
BA_ "GenSigTimeoutTime_BSM" SG_ 2651930749 Digit_01_IDCM 0;
BA_ "GenSigTimeoutTime_CADM" SG_ 2651930749 Digit_01_IDCM 0;
BA_ "GenSigTimeoutTime_DMSM" SG_ 2651930749 Digit_01_IDCM 0;
BA_ "GenSigTimeoutTime_DTCM" SG_ 2651930749 Digit_01_IDCM 0;
BA_ "GenSigTimeoutTime_ECM" SG_ 2651930749 Digit_01_IDCM 0;
BA_ "GenSigTimeoutTime_EVCU2" SG_ 2651930749 Digit_01_IDCM 0;
BA_ "GenSigTimeoutTime_GNMM" SG_ 2651930749 Digit_01_IDCM 0;
BA_ "GenSigTimeoutTime_HCP" SG_ 2651930749 Digit_01_IDCM 0;
BA_ "GenSigTimeoutTime_IPC" SG_ 2651930749 Digit_01_IDCM 0;
BA_ "GenSigTimeoutTime_RFHM" SG_ 2651930749 Digit_01_IDCM 0;
BA_ "GenSigTimeoutTime_SGW" SG_ 2651930749 Digit_01_IDCM 0;
BA_ "GenSigTimeoutTime_TCM" SG_ 2651930749 Digit_01_IDCM 0;
BA_ "GenSigTimeoutTime_AGSM" SG_ 2651930749 Digit_02_IDCM 0;
BA_ "GenSigTimeoutTime_BSM" SG_ 2651930749 Digit_02_IDCM 0;
BA_ "GenSigTimeoutTime_CADM" SG_ 2651930749 Digit_02_IDCM 0;
BA_ "GenSigTimeoutTime_DMSM" SG_ 2651930749 Digit_02_IDCM 0;
BA_ "GenSigTimeoutTime_DTCM" SG_ 2651930749 Digit_02_IDCM 0;
BA_ "GenSigTimeoutTime_ECM" SG_ 2651930749 Digit_02_IDCM 0;
BA_ "GenSigTimeoutTime_EVCU2" SG_ 2651930749 Digit_02_IDCM 0;
BA_ "GenSigTimeoutTime_GNMM" SG_ 2651930749 Digit_02_IDCM 0;
BA_ "GenSigTimeoutTime_HCP" SG_ 2651930749 Digit_02_IDCM 0;
BA_ "GenSigTimeoutTime_IPC" SG_ 2651930749 Digit_02_IDCM 0;
BA_ "GenSigTimeoutTime_RFHM" SG_ 2651930749 Digit_02_IDCM 0;
BA_ "GenSigTimeoutTime_SGW" SG_ 2651930749 Digit_02_IDCM 0;
BA_ "GenSigTimeoutTime_TCM" SG_ 2651930749 Digit_02_IDCM 0;
BA_ "GenSigTimeoutTime_AGSM" SG_ 2651930749 Digit_03_IDCM 0;
BA_ "GenSigTimeoutTime_BSM" SG_ 2651930749 Digit_03_IDCM 0;
BA_ "GenSigTimeoutTime_CADM" SG_ 2651930749 Digit_03_IDCM 0;
BA_ "GenSigTimeoutTime_DMSM" SG_ 2651930749 Digit_03_IDCM 0;
BA_ "GenSigTimeoutTime_DTCM" SG_ 2651930749 Digit_03_IDCM 0;
BA_ "GenSigTimeoutTime_ECM" SG_ 2651930749 Digit_03_IDCM 0;
BA_ "GenSigTimeoutTime_EVCU2" SG_ 2651930749 Digit_03_IDCM 0;
BA_ "GenSigTimeoutTime_GNMM" SG_ 2651930749 Digit_03_IDCM 0;
BA_ "GenSigTimeoutTime_HCP" SG_ 2651930749 Digit_03_IDCM 0;
BA_ "GenSigTimeoutTime_IPC" SG_ 2651930749 Digit_03_IDCM 0;
BA_ "GenSigTimeoutTime_RFHM" SG_ 2651930749 Digit_03_IDCM 0;
BA_ "GenSigTimeoutTime_SGW" SG_ 2651930749 Digit_03_IDCM 0;
BA_ "GenSigTimeoutTime_TCM" SG_ 2651930749 Digit_03_IDCM 0;
BA_ "GenSigTimeoutTime_AGSM" SG_ 2651930749 Digit_04_IDCM 0;
BA_ "GenSigTimeoutTime_BSM" SG_ 2651930749 Digit_04_IDCM 0;
BA_ "GenSigTimeoutTime_CADM" SG_ 2651930749 Digit_04_IDCM 0;
BA_ "GenSigTimeoutTime_DMSM" SG_ 2651930749 Digit_04_IDCM 0;
BA_ "GenSigTimeoutTime_DTCM" SG_ 2651930749 Digit_04_IDCM 0;
BA_ "GenSigTimeoutTime_ECM" SG_ 2651930749 Digit_04_IDCM 0;
BA_ "GenSigTimeoutTime_EVCU2" SG_ 2651930749 Digit_04_IDCM 0;
BA_ "GenSigTimeoutTime_GNMM" SG_ 2651930749 Digit_04_IDCM 0;
BA_ "GenSigTimeoutTime_HCP" SG_ 2651930749 Digit_04_IDCM 0;
BA_ "GenSigTimeoutTime_IPC" SG_ 2651930749 Digit_04_IDCM 0;
BA_ "GenSigTimeoutTime_RFHM" SG_ 2651930749 Digit_04_IDCM 0;
BA_ "GenSigTimeoutTime_SGW" SG_ 2651930749 Digit_04_IDCM 0;
BA_ "GenSigTimeoutTime_TCM" SG_ 2651930749 Digit_04_IDCM 0;
BA_ "GenSigTimeoutTime_AGSM" SG_ 2651930749 Digit_05_IDCM 0;
BA_ "GenSigTimeoutTime_BSM" SG_ 2651930749 Digit_05_IDCM 0;
BA_ "GenSigTimeoutTime_CADM" SG_ 2651930749 Digit_05_IDCM 0;
BA_ "GenSigTimeoutTime_DMSM" SG_ 2651930749 Digit_05_IDCM 0;
BA_ "GenSigTimeoutTime_DTCM" SG_ 2651930749 Digit_05_IDCM 0;
BA_ "GenSigTimeoutTime_ECM" SG_ 2651930749 Digit_05_IDCM 0;
BA_ "GenSigTimeoutTime_EVCU2" SG_ 2651930749 Digit_05_IDCM 0;
BA_ "GenSigTimeoutTime_GNMM" SG_ 2651930749 Digit_05_IDCM 0;
BA_ "GenSigTimeoutTime_HCP" SG_ 2651930749 Digit_05_IDCM 0;
BA_ "GenSigTimeoutTime_IPC" SG_ 2651930749 Digit_05_IDCM 0;
BA_ "GenSigTimeoutTime_RFHM" SG_ 2651930749 Digit_05_IDCM 0;
BA_ "GenSigTimeoutTime_SGW" SG_ 2651930749 Digit_05_IDCM 0;
BA_ "GenSigTimeoutTime_TCM" SG_ 2651930749 Digit_05_IDCM 0;
BA_ "GenSigTimeoutTime_AGSM" SG_ 2651930749 Digit_06_IDCM 0;
BA_ "GenSigTimeoutTime_BSM" SG_ 2651930749 Digit_06_IDCM 0;
BA_ "GenSigTimeoutTime_CADM" SG_ 2651930749 Digit_06_IDCM 0;
BA_ "GenSigTimeoutTime_DMSM" SG_ 2651930749 Digit_06_IDCM 0;
BA_ "GenSigTimeoutTime_DTCM" SG_ 2651930749 Digit_06_IDCM 0;
BA_ "GenSigTimeoutTime_ECM" SG_ 2651930749 Digit_06_IDCM 0;
BA_ "GenSigTimeoutTime_EVCU2" SG_ 2651930749 Digit_06_IDCM 0;
BA_ "GenSigTimeoutTime_GNMM" SG_ 2651930749 Digit_06_IDCM 0;
BA_ "GenSigTimeoutTime_HCP" SG_ 2651930749 Digit_06_IDCM 0;
BA_ "GenSigTimeoutTime_IPC" SG_ 2651930749 Digit_06_IDCM 0;
BA_ "GenSigTimeoutTime_RFHM" SG_ 2651930749 Digit_06_IDCM 0;
BA_ "GenSigTimeoutTime_SGW" SG_ 2651930749 Digit_06_IDCM 0;
BA_ "GenSigTimeoutTime_TCM" SG_ 2651930749 Digit_06_IDCM 0;
BA_ "GenSigTimeoutTime_AGSM" SG_ 2651930749 Digit_07_IDCM 0;
BA_ "GenSigTimeoutTime_BSM" SG_ 2651930749 Digit_07_IDCM 0;
BA_ "GenSigTimeoutTime_CADM" SG_ 2651930749 Digit_07_IDCM 0;
BA_ "GenSigTimeoutTime_DMSM" SG_ 2651930749 Digit_07_IDCM 0;
BA_ "GenSigTimeoutTime_DTCM" SG_ 2651930749 Digit_07_IDCM 0;
BA_ "GenSigTimeoutTime_ECM" SG_ 2651930749 Digit_07_IDCM 0;
BA_ "GenSigTimeoutTime_EVCU2" SG_ 2651930749 Digit_07_IDCM 0;
BA_ "GenSigTimeoutTime_GNMM" SG_ 2651930749 Digit_07_IDCM 0;
BA_ "GenSigTimeoutTime_HCP" SG_ 2651930749 Digit_07_IDCM 0;
BA_ "GenSigTimeoutTime_IPC" SG_ 2651930749 Digit_07_IDCM 0;
BA_ "GenSigTimeoutTime_RFHM" SG_ 2651930749 Digit_07_IDCM 0;
BA_ "GenSigTimeoutTime_SGW" SG_ 2651930749 Digit_07_IDCM 0;
BA_ "GenSigTimeoutTime_TCM" SG_ 2651930749 Digit_07_IDCM 0;
BA_ "GenSigTimeoutTime_AGSM" SG_ 2651930749 Digit_08_IDCM 0;
BA_ "GenSigTimeoutTime_BSM" SG_ 2651930749 Digit_08_IDCM 0;
BA_ "GenSigTimeoutTime_CADM" SG_ 2651930749 Digit_08_IDCM 0;
BA_ "GenSigTimeoutTime_DMSM" SG_ 2651930749 Digit_08_IDCM 0;
BA_ "GenSigTimeoutTime_DTCM" SG_ 2651930749 Digit_08_IDCM 0;
BA_ "GenSigTimeoutTime_ECM" SG_ 2651930749 Digit_08_IDCM 0;
BA_ "GenSigTimeoutTime_EVCU2" SG_ 2651930749 Digit_08_IDCM 0;
BA_ "GenSigTimeoutTime_GNMM" SG_ 2651930749 Digit_08_IDCM 0;
BA_ "GenSigTimeoutTime_HCP" SG_ 2651930749 Digit_08_IDCM 0;
BA_ "GenSigTimeoutTime_IPC" SG_ 2651930749 Digit_08_IDCM 0;
BA_ "GenSigTimeoutTime_RFHM" SG_ 2651930749 Digit_08_IDCM 0;
BA_ "GenSigTimeoutTime_SGW" SG_ 2651930749 Digit_08_IDCM 0;
BA_ "GenSigTimeoutTime_TCM" SG_ 2651930749 Digit_08_IDCM 0;
BA_ "GenSigTimeoutTime_AGSM" SG_ 2651930749 Digit_09_IDCM 0;
BA_ "GenSigTimeoutTime_BSM" SG_ 2651930749 Digit_09_IDCM 0;
BA_ "GenSigTimeoutTime_CADM" SG_ 2651930749 Digit_09_IDCM 0;
BA_ "GenSigTimeoutTime_DMSM" SG_ 2651930749 Digit_09_IDCM 0;
BA_ "GenSigTimeoutTime_DTCM" SG_ 2651930749 Digit_09_IDCM 0;
BA_ "GenSigTimeoutTime_ECM" SG_ 2651930749 Digit_09_IDCM 0;
BA_ "GenSigTimeoutTime_EVCU2" SG_ 2651930749 Digit_09_IDCM 0;
BA_ "GenSigTimeoutTime_GNMM" SG_ 2651930749 Digit_09_IDCM 0;
BA_ "GenSigTimeoutTime_HCP" SG_ 2651930749 Digit_09_IDCM 0;
BA_ "GenSigTimeoutTime_IPC" SG_ 2651930749 Digit_09_IDCM 0;
BA_ "GenSigTimeoutTime_RFHM" SG_ 2651930749 Digit_09_IDCM 0;
BA_ "GenSigTimeoutTime_SGW" SG_ 2651930749 Digit_09_IDCM 0;
BA_ "GenSigTimeoutTime_TCM" SG_ 2651930749 Digit_09_IDCM 0;
BA_ "GenSigTimeoutTime_AGSM" SG_ 2651930749 Digit_10_IDCM 0;
BA_ "GenSigTimeoutTime_BSM" SG_ 2651930749 Digit_10_IDCM 0;
BA_ "GenSigTimeoutTime_CADM" SG_ 2651930749 Digit_10_IDCM 0;
BA_ "GenSigTimeoutTime_DMSM" SG_ 2651930749 Digit_10_IDCM 0;
BA_ "GenSigTimeoutTime_DTCM" SG_ 2651930749 Digit_10_IDCM 0;
BA_ "GenSigTimeoutTime_ECM" SG_ 2651930749 Digit_10_IDCM 0;
BA_ "GenSigTimeoutTime_EVCU2" SG_ 2651930749 Digit_10_IDCM 0;
BA_ "GenSigTimeoutTime_GNMM" SG_ 2651930749 Digit_10_IDCM 0;
BA_ "GenSigTimeoutTime_HCP" SG_ 2651930749 Digit_10_IDCM 0;
BA_ "GenSigTimeoutTime_IPC" SG_ 2651930749 Digit_10_IDCM 0;
BA_ "GenSigTimeoutTime_RFHM" SG_ 2651930749 Digit_10_IDCM 0;
BA_ "GenSigTimeoutTime_SGW" SG_ 2651930749 Digit_10_IDCM 0;
BA_ "GenSigTimeoutTime_TCM" SG_ 2651930749 Digit_10_IDCM 0;
BA_ "GenSigTimeoutTime_AGSM" SG_ 2651930749 Digit_11_IDCM 0;
BA_ "GenSigTimeoutTime_BSM" SG_ 2651930749 Digit_11_IDCM 0;
BA_ "GenSigTimeoutTime_CADM" SG_ 2651930749 Digit_11_IDCM 0;
BA_ "GenSigTimeoutTime_DMSM" SG_ 2651930749 Digit_11_IDCM 0;
BA_ "GenSigTimeoutTime_DTCM" SG_ 2651930749 Digit_11_IDCM 0;
BA_ "GenSigTimeoutTime_ECM" SG_ 2651930749 Digit_11_IDCM 0;
BA_ "GenSigTimeoutTime_EVCU2" SG_ 2651930749 Digit_11_IDCM 0;
BA_ "GenSigTimeoutTime_GNMM" SG_ 2651930749 Digit_11_IDCM 0;
BA_ "GenSigTimeoutTime_HCP" SG_ 2651930749 Digit_11_IDCM 0;
BA_ "GenSigTimeoutTime_IPC" SG_ 2651930749 Digit_11_IDCM 0;
BA_ "GenSigTimeoutTime_RFHM" SG_ 2651930749 Digit_11_IDCM 0;
BA_ "GenSigTimeoutTime_SGW" SG_ 2651930749 Digit_11_IDCM 0;
BA_ "GenSigTimeoutTime_TCM" SG_ 2651930749 Digit_11_IDCM 0;
BA_ "GenSigSendType" SG_ 2651930627 Digit_01_IPC 1;
BA_ "GenSigTimeoutTime_AGSM" SG_ 2651930627 Digit_01_IPC 0;
BA_ "GenSigTimeoutTime_BSM" SG_ 2651930627 Digit_01_IPC 0;
BA_ "GenSigTimeoutTime_CADM" SG_ 2651930627 Digit_01_IPC 0;
BA_ "GenSigTimeoutTime_DMSM" SG_ 2651930627 Digit_01_IPC 0;
BA_ "GenSigTimeoutTime_DTCM" SG_ 2651930627 Digit_01_IPC 0;
BA_ "GenSigTimeoutTime_ECM" SG_ 2651930627 Digit_01_IPC 0;
BA_ "GenSigTimeoutTime_EVCU2" SG_ 2651930627 Digit_01_IPC 0;
BA_ "GenSigTimeoutTime_GNMM" SG_ 2651930627 Digit_01_IPC 0;
BA_ "GenSigTimeoutTime_HCP" SG_ 2651930627 Digit_01_IPC 0;
BA_ "GenSigTimeoutTime_IPC" SG_ 2651930627 Digit_01_IPC 0;
BA_ "GenSigTimeoutTime_RFHM" SG_ 2651930627 Digit_01_IPC 0;
BA_ "GenSigTimeoutTime_SGW" SG_ 2651930627 Digit_01_IPC 0;
BA_ "GenSigTimeoutTime_TCM" SG_ 2651930627 Digit_01_IPC 0;
BA_ "GenSigTimeoutTime_AGSM" SG_ 2651930627 Digit_02_IPC 0;
BA_ "GenSigTimeoutTime_BSM" SG_ 2651930627 Digit_02_IPC 0;
BA_ "GenSigTimeoutTime_CADM" SG_ 2651930627 Digit_02_IPC 0;
BA_ "GenSigTimeoutTime_DMSM" SG_ 2651930627 Digit_02_IPC 0;
BA_ "GenSigTimeoutTime_DTCM" SG_ 2651930627 Digit_02_IPC 0;
BA_ "GenSigTimeoutTime_ECM" SG_ 2651930627 Digit_02_IPC 0;
BA_ "GenSigTimeoutTime_EVCU2" SG_ 2651930627 Digit_02_IPC 0;
BA_ "GenSigTimeoutTime_GNMM" SG_ 2651930627 Digit_02_IPC 0;
BA_ "GenSigTimeoutTime_HCP" SG_ 2651930627 Digit_02_IPC 0;
BA_ "GenSigTimeoutTime_IPC" SG_ 2651930627 Digit_02_IPC 0;
BA_ "GenSigTimeoutTime_RFHM" SG_ 2651930627 Digit_02_IPC 0;
BA_ "GenSigTimeoutTime_SGW" SG_ 2651930627 Digit_02_IPC 0;
BA_ "GenSigTimeoutTime_TCM" SG_ 2651930627 Digit_02_IPC 0;
BA_ "GenSigTimeoutTime_AGSM" SG_ 2651930627 Digit_03_IPC 0;
BA_ "GenSigTimeoutTime_BSM" SG_ 2651930627 Digit_03_IPC 0;
BA_ "GenSigTimeoutTime_CADM" SG_ 2651930627 Digit_03_IPC 0;
BA_ "GenSigTimeoutTime_DMSM" SG_ 2651930627 Digit_03_IPC 0;
BA_ "GenSigTimeoutTime_DTCM" SG_ 2651930627 Digit_03_IPC 0;
BA_ "GenSigTimeoutTime_ECM" SG_ 2651930627 Digit_03_IPC 0;
BA_ "GenSigTimeoutTime_EVCU2" SG_ 2651930627 Digit_03_IPC 0;
BA_ "GenSigTimeoutTime_GNMM" SG_ 2651930627 Digit_03_IPC 0;
BA_ "GenSigTimeoutTime_HCP" SG_ 2651930627 Digit_03_IPC 0;
BA_ "GenSigTimeoutTime_IPC" SG_ 2651930627 Digit_03_IPC 0;
BA_ "GenSigTimeoutTime_RFHM" SG_ 2651930627 Digit_03_IPC 0;
BA_ "GenSigTimeoutTime_SGW" SG_ 2651930627 Digit_03_IPC 0;
BA_ "GenSigTimeoutTime_TCM" SG_ 2651930627 Digit_03_IPC 0;
BA_ "GenSigTimeoutTime_AGSM" SG_ 2651930627 Digit_04_IPC 0;
BA_ "GenSigTimeoutTime_BSM" SG_ 2651930627 Digit_04_IPC 0;
BA_ "GenSigTimeoutTime_CADM" SG_ 2651930627 Digit_04_IPC 0;
BA_ "GenSigTimeoutTime_DMSM" SG_ 2651930627 Digit_04_IPC 0;
BA_ "GenSigTimeoutTime_DTCM" SG_ 2651930627 Digit_04_IPC 0;
BA_ "GenSigTimeoutTime_ECM" SG_ 2651930627 Digit_04_IPC 0;
BA_ "GenSigTimeoutTime_EVCU2" SG_ 2651930627 Digit_04_IPC 0;
BA_ "GenSigTimeoutTime_GNMM" SG_ 2651930627 Digit_04_IPC 0;
BA_ "GenSigTimeoutTime_HCP" SG_ 2651930627 Digit_04_IPC 0;
BA_ "GenSigTimeoutTime_IPC" SG_ 2651930627 Digit_04_IPC 0;
BA_ "GenSigTimeoutTime_RFHM" SG_ 2651930627 Digit_04_IPC 0;
BA_ "GenSigTimeoutTime_SGW" SG_ 2651930627 Digit_04_IPC 0;
BA_ "GenSigTimeoutTime_TCM" SG_ 2651930627 Digit_04_IPC 0;
BA_ "GenSigTimeoutTime_AGSM" SG_ 2651930627 Digit_05_IPC 0;
BA_ "GenSigTimeoutTime_BSM" SG_ 2651930627 Digit_05_IPC 0;
BA_ "GenSigTimeoutTime_CADM" SG_ 2651930627 Digit_05_IPC 0;
BA_ "GenSigTimeoutTime_DMSM" SG_ 2651930627 Digit_05_IPC 0;
BA_ "GenSigTimeoutTime_DTCM" SG_ 2651930627 Digit_05_IPC 0;
BA_ "GenSigTimeoutTime_ECM" SG_ 2651930627 Digit_05_IPC 0;
BA_ "GenSigTimeoutTime_EVCU2" SG_ 2651930627 Digit_05_IPC 0;
BA_ "GenSigTimeoutTime_GNMM" SG_ 2651930627 Digit_05_IPC 0;
BA_ "GenSigTimeoutTime_HCP" SG_ 2651930627 Digit_05_IPC 0;
BA_ "GenSigTimeoutTime_IPC" SG_ 2651930627 Digit_05_IPC 0;
BA_ "GenSigTimeoutTime_RFHM" SG_ 2651930627 Digit_05_IPC 0;
BA_ "GenSigTimeoutTime_SGW" SG_ 2651930627 Digit_05_IPC 0;
BA_ "GenSigTimeoutTime_TCM" SG_ 2651930627 Digit_05_IPC 0;
BA_ "GenSigTimeoutTime_AGSM" SG_ 2651930627 Digit_06_IPC 0;
BA_ "GenSigTimeoutTime_BSM" SG_ 2651930627 Digit_06_IPC 0;
BA_ "GenSigTimeoutTime_CADM" SG_ 2651930627 Digit_06_IPC 0;
BA_ "GenSigTimeoutTime_DMSM" SG_ 2651930627 Digit_06_IPC 0;
BA_ "GenSigTimeoutTime_DTCM" SG_ 2651930627 Digit_06_IPC 0;
BA_ "GenSigTimeoutTime_ECM" SG_ 2651930627 Digit_06_IPC 0;
BA_ "GenSigTimeoutTime_EVCU2" SG_ 2651930627 Digit_06_IPC 0;
BA_ "GenSigTimeoutTime_GNMM" SG_ 2651930627 Digit_06_IPC 0;
BA_ "GenSigTimeoutTime_HCP" SG_ 2651930627 Digit_06_IPC 0;
BA_ "GenSigTimeoutTime_IPC" SG_ 2651930627 Digit_06_IPC 0;
BA_ "GenSigTimeoutTime_RFHM" SG_ 2651930627 Digit_06_IPC 0;
BA_ "GenSigTimeoutTime_SGW" SG_ 2651930627 Digit_06_IPC 0;
BA_ "GenSigTimeoutTime_TCM" SG_ 2651930627 Digit_06_IPC 0;
BA_ "GenSigTimeoutTime_AGSM" SG_ 2651930627 Digit_07_IPC 0;
BA_ "GenSigTimeoutTime_BSM" SG_ 2651930627 Digit_07_IPC 0;
BA_ "GenSigTimeoutTime_CADM" SG_ 2651930627 Digit_07_IPC 0;
BA_ "GenSigTimeoutTime_DMSM" SG_ 2651930627 Digit_07_IPC 0;
BA_ "GenSigTimeoutTime_DTCM" SG_ 2651930627 Digit_07_IPC 0;
BA_ "GenSigTimeoutTime_ECM" SG_ 2651930627 Digit_07_IPC 0;
BA_ "GenSigTimeoutTime_EVCU2" SG_ 2651930627 Digit_07_IPC 0;
BA_ "GenSigTimeoutTime_GNMM" SG_ 2651930627 Digit_07_IPC 0;
BA_ "GenSigTimeoutTime_HCP" SG_ 2651930627 Digit_07_IPC 0;
BA_ "GenSigTimeoutTime_IPC" SG_ 2651930627 Digit_07_IPC 0;
BA_ "GenSigTimeoutTime_RFHM" SG_ 2651930627 Digit_07_IPC 0;
BA_ "GenSigTimeoutTime_SGW" SG_ 2651930627 Digit_07_IPC 0;
BA_ "GenSigTimeoutTime_TCM" SG_ 2651930627 Digit_07_IPC 0;
BA_ "GenSigTimeoutTime_AGSM" SG_ 2651930627 Digit_08_IPC 0;
BA_ "GenSigTimeoutTime_BSM" SG_ 2651930627 Digit_08_IPC 0;
BA_ "GenSigTimeoutTime_CADM" SG_ 2651930627 Digit_08_IPC 0;
BA_ "GenSigTimeoutTime_DMSM" SG_ 2651930627 Digit_08_IPC 0;
BA_ "GenSigTimeoutTime_DTCM" SG_ 2651930627 Digit_08_IPC 0;
BA_ "GenSigTimeoutTime_ECM" SG_ 2651930627 Digit_08_IPC 0;
BA_ "GenSigTimeoutTime_EVCU2" SG_ 2651930627 Digit_08_IPC 0;
BA_ "GenSigTimeoutTime_GNMM" SG_ 2651930627 Digit_08_IPC 0;
BA_ "GenSigTimeoutTime_HCP" SG_ 2651930627 Digit_08_IPC 0;
BA_ "GenSigTimeoutTime_IPC" SG_ 2651930627 Digit_08_IPC 0;
BA_ "GenSigTimeoutTime_RFHM" SG_ 2651930627 Digit_08_IPC 0;
BA_ "GenSigTimeoutTime_SGW" SG_ 2651930627 Digit_08_IPC 0;
BA_ "GenSigTimeoutTime_TCM" SG_ 2651930627 Digit_08_IPC 0;
BA_ "GenSigTimeoutTime_AGSM" SG_ 2651930627 Digit_09_IPC 0;
BA_ "GenSigTimeoutTime_BSM" SG_ 2651930627 Digit_09_IPC 0;
BA_ "GenSigTimeoutTime_CADM" SG_ 2651930627 Digit_09_IPC 0;
BA_ "GenSigTimeoutTime_DMSM" SG_ 2651930627 Digit_09_IPC 0;
BA_ "GenSigTimeoutTime_DTCM" SG_ 2651930627 Digit_09_IPC 0;
BA_ "GenSigTimeoutTime_ECM" SG_ 2651930627 Digit_09_IPC 0;
BA_ "GenSigTimeoutTime_EVCU2" SG_ 2651930627 Digit_09_IPC 0;
BA_ "GenSigTimeoutTime_GNMM" SG_ 2651930627 Digit_09_IPC 0;
BA_ "GenSigTimeoutTime_HCP" SG_ 2651930627 Digit_09_IPC 0;
BA_ "GenSigTimeoutTime_IPC" SG_ 2651930627 Digit_09_IPC 0;
BA_ "GenSigTimeoutTime_RFHM" SG_ 2651930627 Digit_09_IPC 0;
BA_ "GenSigTimeoutTime_SGW" SG_ 2651930627 Digit_09_IPC 0;
BA_ "GenSigTimeoutTime_TCM" SG_ 2651930627 Digit_09_IPC 0;
BA_ "GenSigTimeoutTime_AGSM" SG_ 2651930627 Digit_10_IPC 0;
BA_ "GenSigTimeoutTime_BSM" SG_ 2651930627 Digit_10_IPC 0;
BA_ "GenSigTimeoutTime_CADM" SG_ 2651930627 Digit_10_IPC 0;
BA_ "GenSigTimeoutTime_DMSM" SG_ 2651930627 Digit_10_IPC 0;
BA_ "GenSigTimeoutTime_DTCM" SG_ 2651930627 Digit_10_IPC 0;
BA_ "GenSigTimeoutTime_ECM" SG_ 2651930627 Digit_10_IPC 0;
BA_ "GenSigTimeoutTime_EVCU2" SG_ 2651930627 Digit_10_IPC 0;
BA_ "GenSigTimeoutTime_GNMM" SG_ 2651930627 Digit_10_IPC 0;
BA_ "GenSigTimeoutTime_HCP" SG_ 2651930627 Digit_10_IPC 0;
BA_ "GenSigTimeoutTime_IPC" SG_ 2651930627 Digit_10_IPC 0;
BA_ "GenSigTimeoutTime_RFHM" SG_ 2651930627 Digit_10_IPC 0;
BA_ "GenSigTimeoutTime_SGW" SG_ 2651930627 Digit_10_IPC 0;
BA_ "GenSigTimeoutTime_TCM" SG_ 2651930627 Digit_10_IPC 0;
BA_ "GenSigTimeoutTime_AGSM" SG_ 2651930627 Digit_11_IPC 0;
BA_ "GenSigTimeoutTime_BSM" SG_ 2651930627 Digit_11_IPC 0;
BA_ "GenSigTimeoutTime_CADM" SG_ 2651930627 Digit_11_IPC 0;
BA_ "GenSigTimeoutTime_DMSM" SG_ 2651930627 Digit_11_IPC 0;
BA_ "GenSigTimeoutTime_DTCM" SG_ 2651930627 Digit_11_IPC 0;
BA_ "GenSigTimeoutTime_ECM" SG_ 2651930627 Digit_11_IPC 0;
BA_ "GenSigTimeoutTime_EVCU2" SG_ 2651930627 Digit_11_IPC 0;
BA_ "GenSigTimeoutTime_GNMM" SG_ 2651930627 Digit_11_IPC 0;
BA_ "GenSigTimeoutTime_HCP" SG_ 2651930627 Digit_11_IPC 0;
BA_ "GenSigTimeoutTime_IPC" SG_ 2651930627 Digit_11_IPC 0;
BA_ "GenSigTimeoutTime_RFHM" SG_ 2651930627 Digit_11_IPC 0;
BA_ "GenSigTimeoutTime_SGW" SG_ 2651930627 Digit_11_IPC 0;
BA_ "GenSigTimeoutTime_TCM" SG_ 2651930627 Digit_11_IPC 0;
BA_ "GenSigSendType" SG_ 2651930712 Digit_01_MCPA 1;
BA_ "GenSigTimeoutTime_AGSM" SG_ 2651930712 Digit_01_MCPA 0;
BA_ "GenSigTimeoutTime_BSM" SG_ 2651930712 Digit_01_MCPA 0;
BA_ "GenSigTimeoutTime_CADM" SG_ 2651930712 Digit_01_MCPA 0;
BA_ "GenSigTimeoutTime_DMSM" SG_ 2651930712 Digit_01_MCPA 0;
BA_ "GenSigTimeoutTime_DTCM" SG_ 2651930712 Digit_01_MCPA 0;
BA_ "GenSigTimeoutTime_ECM" SG_ 2651930712 Digit_01_MCPA 0;
BA_ "GenSigTimeoutTime_EVCU2" SG_ 2651930712 Digit_01_MCPA 0;
BA_ "GenSigTimeoutTime_GNMM" SG_ 2651930712 Digit_01_MCPA 0;
BA_ "GenSigTimeoutTime_HCP" SG_ 2651930712 Digit_01_MCPA 0;
BA_ "GenSigTimeoutTime_IPC" SG_ 2651930712 Digit_01_MCPA 0;
BA_ "GenSigTimeoutTime_RFHM" SG_ 2651930712 Digit_01_MCPA 0;
BA_ "GenSigTimeoutTime_SGW" SG_ 2651930712 Digit_01_MCPA 0;
BA_ "GenSigTimeoutTime_TCM" SG_ 2651930712 Digit_01_MCPA 0;
BA_ "GenSigTimeoutTime_AGSM" SG_ 2651930712 Digit_02_MCPA 0;
BA_ "GenSigTimeoutTime_BSM" SG_ 2651930712 Digit_02_MCPA 0;
BA_ "GenSigTimeoutTime_CADM" SG_ 2651930712 Digit_02_MCPA 0;
BA_ "GenSigTimeoutTime_DMSM" SG_ 2651930712 Digit_02_MCPA 0;
BA_ "GenSigTimeoutTime_DTCM" SG_ 2651930712 Digit_02_MCPA 0;
BA_ "GenSigTimeoutTime_ECM" SG_ 2651930712 Digit_02_MCPA 0;
BA_ "GenSigTimeoutTime_EVCU2" SG_ 2651930712 Digit_02_MCPA 0;
BA_ "GenSigTimeoutTime_GNMM" SG_ 2651930712 Digit_02_MCPA 0;
BA_ "GenSigTimeoutTime_HCP" SG_ 2651930712 Digit_02_MCPA 0;
BA_ "GenSigTimeoutTime_IPC" SG_ 2651930712 Digit_02_MCPA 0;
BA_ "GenSigTimeoutTime_RFHM" SG_ 2651930712 Digit_02_MCPA 0;
BA_ "GenSigTimeoutTime_SGW" SG_ 2651930712 Digit_02_MCPA 0;
BA_ "GenSigTimeoutTime_TCM" SG_ 2651930712 Digit_02_MCPA 0;
BA_ "GenSigTimeoutTime_AGSM" SG_ 2651930712 Digit_03_MCPA 0;
BA_ "GenSigTimeoutTime_BSM" SG_ 2651930712 Digit_03_MCPA 0;
BA_ "GenSigTimeoutTime_CADM" SG_ 2651930712 Digit_03_MCPA 0;
BA_ "GenSigTimeoutTime_DMSM" SG_ 2651930712 Digit_03_MCPA 0;
BA_ "GenSigTimeoutTime_DTCM" SG_ 2651930712 Digit_03_MCPA 0;
BA_ "GenSigTimeoutTime_ECM" SG_ 2651930712 Digit_03_MCPA 0;
BA_ "GenSigTimeoutTime_EVCU2" SG_ 2651930712 Digit_03_MCPA 0;
BA_ "GenSigTimeoutTime_GNMM" SG_ 2651930712 Digit_03_MCPA 0;
BA_ "GenSigTimeoutTime_HCP" SG_ 2651930712 Digit_03_MCPA 0;
BA_ "GenSigTimeoutTime_IPC" SG_ 2651930712 Digit_03_MCPA 0;
BA_ "GenSigTimeoutTime_RFHM" SG_ 2651930712 Digit_03_MCPA 0;
BA_ "GenSigTimeoutTime_SGW" SG_ 2651930712 Digit_03_MCPA 0;
BA_ "GenSigTimeoutTime_TCM" SG_ 2651930712 Digit_03_MCPA 0;
BA_ "GenSigTimeoutTime_AGSM" SG_ 2651930712 Digit_04_MCPA 0;
BA_ "GenSigTimeoutTime_BSM" SG_ 2651930712 Digit_04_MCPA 0;
BA_ "GenSigTimeoutTime_CADM" SG_ 2651930712 Digit_04_MCPA 0;
BA_ "GenSigTimeoutTime_DMSM" SG_ 2651930712 Digit_04_MCPA 0;
BA_ "GenSigTimeoutTime_DTCM" SG_ 2651930712 Digit_04_MCPA 0;
BA_ "GenSigTimeoutTime_ECM" SG_ 2651930712 Digit_04_MCPA 0;
BA_ "GenSigTimeoutTime_EVCU2" SG_ 2651930712 Digit_04_MCPA 0;
BA_ "GenSigTimeoutTime_GNMM" SG_ 2651930712 Digit_04_MCPA 0;
BA_ "GenSigTimeoutTime_HCP" SG_ 2651930712 Digit_04_MCPA 0;
BA_ "GenSigTimeoutTime_IPC" SG_ 2651930712 Digit_04_MCPA 0;
BA_ "GenSigTimeoutTime_RFHM" SG_ 2651930712 Digit_04_MCPA 0;
BA_ "GenSigTimeoutTime_SGW" SG_ 2651930712 Digit_04_MCPA 0;
BA_ "GenSigTimeoutTime_TCM" SG_ 2651930712 Digit_04_MCPA 0;
BA_ "GenSigTimeoutTime_AGSM" SG_ 2651930712 Digit_05_MCPA 0;
BA_ "GenSigTimeoutTime_BSM" SG_ 2651930712 Digit_05_MCPA 0;
BA_ "GenSigTimeoutTime_CADM" SG_ 2651930712 Digit_05_MCPA 0;
BA_ "GenSigTimeoutTime_DMSM" SG_ 2651930712 Digit_05_MCPA 0;
BA_ "GenSigTimeoutTime_DTCM" SG_ 2651930712 Digit_05_MCPA 0;
BA_ "GenSigTimeoutTime_ECM" SG_ 2651930712 Digit_05_MCPA 0;
BA_ "GenSigTimeoutTime_EVCU2" SG_ 2651930712 Digit_05_MCPA 0;
BA_ "GenSigTimeoutTime_GNMM" SG_ 2651930712 Digit_05_MCPA 0;
BA_ "GenSigTimeoutTime_HCP" SG_ 2651930712 Digit_05_MCPA 0;
BA_ "GenSigTimeoutTime_IPC" SG_ 2651930712 Digit_05_MCPA 0;
BA_ "GenSigTimeoutTime_RFHM" SG_ 2651930712 Digit_05_MCPA 0;
BA_ "GenSigTimeoutTime_SGW" SG_ 2651930712 Digit_05_MCPA 0;
BA_ "GenSigTimeoutTime_TCM" SG_ 2651930712 Digit_05_MCPA 0;
BA_ "GenSigTimeoutTime_AGSM" SG_ 2651930712 Digit_06_MCPA 0;
BA_ "GenSigTimeoutTime_BSM" SG_ 2651930712 Digit_06_MCPA 0;
BA_ "GenSigTimeoutTime_CADM" SG_ 2651930712 Digit_06_MCPA 0;
BA_ "GenSigTimeoutTime_DMSM" SG_ 2651930712 Digit_06_MCPA 0;
BA_ "GenSigTimeoutTime_DTCM" SG_ 2651930712 Digit_06_MCPA 0;
BA_ "GenSigTimeoutTime_ECM" SG_ 2651930712 Digit_06_MCPA 0;
BA_ "GenSigTimeoutTime_EVCU2" SG_ 2651930712 Digit_06_MCPA 0;
BA_ "GenSigTimeoutTime_GNMM" SG_ 2651930712 Digit_06_MCPA 0;
BA_ "GenSigTimeoutTime_HCP" SG_ 2651930712 Digit_06_MCPA 0;
BA_ "GenSigTimeoutTime_IPC" SG_ 2651930712 Digit_06_MCPA 0;
BA_ "GenSigTimeoutTime_RFHM" SG_ 2651930712 Digit_06_MCPA 0;
BA_ "GenSigTimeoutTime_SGW" SG_ 2651930712 Digit_06_MCPA 0;
BA_ "GenSigTimeoutTime_TCM" SG_ 2651930712 Digit_06_MCPA 0;
BA_ "GenSigTimeoutTime_AGSM" SG_ 2651930712 Digit_07_MCPA 0;
BA_ "GenSigTimeoutTime_BSM" SG_ 2651930712 Digit_07_MCPA 0;
BA_ "GenSigTimeoutTime_CADM" SG_ 2651930712 Digit_07_MCPA 0;
BA_ "GenSigTimeoutTime_DMSM" SG_ 2651930712 Digit_07_MCPA 0;
BA_ "GenSigTimeoutTime_DTCM" SG_ 2651930712 Digit_07_MCPA 0;
BA_ "GenSigTimeoutTime_ECM" SG_ 2651930712 Digit_07_MCPA 0;
BA_ "GenSigTimeoutTime_EVCU2" SG_ 2651930712 Digit_07_MCPA 0;
BA_ "GenSigTimeoutTime_GNMM" SG_ 2651930712 Digit_07_MCPA 0;
BA_ "GenSigTimeoutTime_HCP" SG_ 2651930712 Digit_07_MCPA 0;
BA_ "GenSigTimeoutTime_IPC" SG_ 2651930712 Digit_07_MCPA 0;
BA_ "GenSigTimeoutTime_RFHM" SG_ 2651930712 Digit_07_MCPA 0;
BA_ "GenSigTimeoutTime_SGW" SG_ 2651930712 Digit_07_MCPA 0;
BA_ "GenSigTimeoutTime_TCM" SG_ 2651930712 Digit_07_MCPA 0;
BA_ "GenSigTimeoutTime_AGSM" SG_ 2651930712 Digit_08_MCPA 0;
BA_ "GenSigTimeoutTime_BSM" SG_ 2651930712 Digit_08_MCPA 0;
BA_ "GenSigTimeoutTime_CADM" SG_ 2651930712 Digit_08_MCPA 0;
BA_ "GenSigTimeoutTime_DMSM" SG_ 2651930712 Digit_08_MCPA 0;
BA_ "GenSigTimeoutTime_DTCM" SG_ 2651930712 Digit_08_MCPA 0;
BA_ "GenSigTimeoutTime_ECM" SG_ 2651930712 Digit_08_MCPA 0;
BA_ "GenSigTimeoutTime_EVCU2" SG_ 2651930712 Digit_08_MCPA 0;
BA_ "GenSigTimeoutTime_GNMM" SG_ 2651930712 Digit_08_MCPA 0;
BA_ "GenSigTimeoutTime_HCP" SG_ 2651930712 Digit_08_MCPA 0;
BA_ "GenSigTimeoutTime_IPC" SG_ 2651930712 Digit_08_MCPA 0;
BA_ "GenSigTimeoutTime_RFHM" SG_ 2651930712 Digit_08_MCPA 0;
BA_ "GenSigTimeoutTime_SGW" SG_ 2651930712 Digit_08_MCPA 0;
BA_ "GenSigTimeoutTime_TCM" SG_ 2651930712 Digit_08_MCPA 0;
BA_ "GenSigTimeoutTime_AGSM" SG_ 2651930712 Digit_09_MCPA 0;
BA_ "GenSigTimeoutTime_BSM" SG_ 2651930712 Digit_09_MCPA 0;
BA_ "GenSigTimeoutTime_CADM" SG_ 2651930712 Digit_09_MCPA 0;
BA_ "GenSigTimeoutTime_DMSM" SG_ 2651930712 Digit_09_MCPA 0;
BA_ "GenSigTimeoutTime_DTCM" SG_ 2651930712 Digit_09_MCPA 0;
BA_ "GenSigTimeoutTime_ECM" SG_ 2651930712 Digit_09_MCPA 0;
BA_ "GenSigTimeoutTime_EVCU2" SG_ 2651930712 Digit_09_MCPA 0;
BA_ "GenSigTimeoutTime_GNMM" SG_ 2651930712 Digit_09_MCPA 0;
BA_ "GenSigTimeoutTime_HCP" SG_ 2651930712 Digit_09_MCPA 0;
BA_ "GenSigTimeoutTime_IPC" SG_ 2651930712 Digit_09_MCPA 0;
BA_ "GenSigTimeoutTime_RFHM" SG_ 2651930712 Digit_09_MCPA 0;
BA_ "GenSigTimeoutTime_SGW" SG_ 2651930712 Digit_09_MCPA 0;
BA_ "GenSigTimeoutTime_TCM" SG_ 2651930712 Digit_09_MCPA 0;
BA_ "GenSigTimeoutTime_AGSM" SG_ 2651930712 Digit_10_MCPA 0;
BA_ "GenSigTimeoutTime_BSM" SG_ 2651930712 Digit_10_MCPA 0;
BA_ "GenSigTimeoutTime_CADM" SG_ 2651930712 Digit_10_MCPA 0;
BA_ "GenSigTimeoutTime_DMSM" SG_ 2651930712 Digit_10_MCPA 0;
BA_ "GenSigTimeoutTime_DTCM" SG_ 2651930712 Digit_10_MCPA 0;
BA_ "GenSigTimeoutTime_ECM" SG_ 2651930712 Digit_10_MCPA 0;
BA_ "GenSigTimeoutTime_EVCU2" SG_ 2651930712 Digit_10_MCPA 0;
BA_ "GenSigTimeoutTime_GNMM" SG_ 2651930712 Digit_10_MCPA 0;
BA_ "GenSigTimeoutTime_HCP" SG_ 2651930712 Digit_10_MCPA 0;
BA_ "GenSigTimeoutTime_IPC" SG_ 2651930712 Digit_10_MCPA 0;
BA_ "GenSigTimeoutTime_RFHM" SG_ 2651930712 Digit_10_MCPA 0;
BA_ "GenSigTimeoutTime_SGW" SG_ 2651930712 Digit_10_MCPA 0;
BA_ "GenSigTimeoutTime_TCM" SG_ 2651930712 Digit_10_MCPA 0;
BA_ "GenSigTimeoutTime_AGSM" SG_ 2651930712 Digit_11_MCPA 0;
BA_ "GenSigTimeoutTime_BSM" SG_ 2651930712 Digit_11_MCPA 0;
BA_ "GenSigTimeoutTime_CADM" SG_ 2651930712 Digit_11_MCPA 0;
BA_ "GenSigTimeoutTime_DMSM" SG_ 2651930712 Digit_11_MCPA 0;
BA_ "GenSigTimeoutTime_DTCM" SG_ 2651930712 Digit_11_MCPA 0;
BA_ "GenSigTimeoutTime_ECM" SG_ 2651930712 Digit_11_MCPA 0;
BA_ "GenSigTimeoutTime_EVCU2" SG_ 2651930712 Digit_11_MCPA 0;
BA_ "GenSigTimeoutTime_GNMM" SG_ 2651930712 Digit_11_MCPA 0;
BA_ "GenSigTimeoutTime_HCP" SG_ 2651930712 Digit_11_MCPA 0;
BA_ "GenSigTimeoutTime_IPC" SG_ 2651930712 Digit_11_MCPA 0;
BA_ "GenSigTimeoutTime_RFHM" SG_ 2651930712 Digit_11_MCPA 0;
BA_ "GenSigTimeoutTime_SGW" SG_ 2651930712 Digit_11_MCPA 0;
BA_ "GenSigTimeoutTime_TCM" SG_ 2651930712 Digit_11_MCPA 0;
BA_ "GenSigSendType" SG_ 2651930713 Digit_01_MCPB 1;
BA_ "GenSigTimeoutTime_AGSM" SG_ 2651930713 Digit_01_MCPB 0;
BA_ "GenSigTimeoutTime_BSM" SG_ 2651930713 Digit_01_MCPB 0;
BA_ "GenSigTimeoutTime_CADM" SG_ 2651930713 Digit_01_MCPB 0;
BA_ "GenSigTimeoutTime_DMSM" SG_ 2651930713 Digit_01_MCPB 0;
BA_ "GenSigTimeoutTime_DTCM" SG_ 2651930713 Digit_01_MCPB 0;
BA_ "GenSigTimeoutTime_ECM" SG_ 2651930713 Digit_01_MCPB 0;
BA_ "GenSigTimeoutTime_EVCU2" SG_ 2651930713 Digit_01_MCPB 0;
BA_ "GenSigTimeoutTime_GNMM" SG_ 2651930713 Digit_01_MCPB 0;
BA_ "GenSigTimeoutTime_HCP" SG_ 2651930713 Digit_01_MCPB 0;
BA_ "GenSigTimeoutTime_IPC" SG_ 2651930713 Digit_01_MCPB 0;
BA_ "GenSigTimeoutTime_RFHM" SG_ 2651930713 Digit_01_MCPB 0;
BA_ "GenSigTimeoutTime_SGW" SG_ 2651930713 Digit_01_MCPB 0;
BA_ "GenSigTimeoutTime_TCM" SG_ 2651930713 Digit_01_MCPB 0;
BA_ "GenSigTimeoutTime_AGSM" SG_ 2651930713 Digit_02_MCPB 0;
BA_ "GenSigTimeoutTime_BSM" SG_ 2651930713 Digit_02_MCPB 0;
BA_ "GenSigTimeoutTime_CADM" SG_ 2651930713 Digit_02_MCPB 0;
BA_ "GenSigTimeoutTime_DMSM" SG_ 2651930713 Digit_02_MCPB 0;
BA_ "GenSigTimeoutTime_DTCM" SG_ 2651930713 Digit_02_MCPB 0;
BA_ "GenSigTimeoutTime_ECM" SG_ 2651930713 Digit_02_MCPB 0;
BA_ "GenSigTimeoutTime_EVCU2" SG_ 2651930713 Digit_02_MCPB 0;
BA_ "GenSigTimeoutTime_GNMM" SG_ 2651930713 Digit_02_MCPB 0;
BA_ "GenSigTimeoutTime_HCP" SG_ 2651930713 Digit_02_MCPB 0;
BA_ "GenSigTimeoutTime_IPC" SG_ 2651930713 Digit_02_MCPB 0;
BA_ "GenSigTimeoutTime_RFHM" SG_ 2651930713 Digit_02_MCPB 0;
BA_ "GenSigTimeoutTime_SGW" SG_ 2651930713 Digit_02_MCPB 0;
BA_ "GenSigTimeoutTime_TCM" SG_ 2651930713 Digit_02_MCPB 0;
BA_ "GenSigTimeoutTime_AGSM" SG_ 2651930713 Digit_03_MCPB 0;
BA_ "GenSigTimeoutTime_BSM" SG_ 2651930713 Digit_03_MCPB 0;
BA_ "GenSigTimeoutTime_CADM" SG_ 2651930713 Digit_03_MCPB 0;
BA_ "GenSigTimeoutTime_DMSM" SG_ 2651930713 Digit_03_MCPB 0;
BA_ "GenSigTimeoutTime_DTCM" SG_ 2651930713 Digit_03_MCPB 0;
BA_ "GenSigTimeoutTime_ECM" SG_ 2651930713 Digit_03_MCPB 0;
BA_ "GenSigTimeoutTime_EVCU2" SG_ 2651930713 Digit_03_MCPB 0;
BA_ "GenSigTimeoutTime_GNMM" SG_ 2651930713 Digit_03_MCPB 0;
BA_ "GenSigTimeoutTime_HCP" SG_ 2651930713 Digit_03_MCPB 0;
BA_ "GenSigTimeoutTime_IPC" SG_ 2651930713 Digit_03_MCPB 0;
BA_ "GenSigTimeoutTime_RFHM" SG_ 2651930713 Digit_03_MCPB 0;
BA_ "GenSigTimeoutTime_SGW" SG_ 2651930713 Digit_03_MCPB 0;
BA_ "GenSigTimeoutTime_TCM" SG_ 2651930713 Digit_03_MCPB 0;
BA_ "GenSigTimeoutTime_AGSM" SG_ 2651930713 Digit_04_MCPB 0;
BA_ "GenSigTimeoutTime_BSM" SG_ 2651930713 Digit_04_MCPB 0;
BA_ "GenSigTimeoutTime_CADM" SG_ 2651930713 Digit_04_MCPB 0;
BA_ "GenSigTimeoutTime_DMSM" SG_ 2651930713 Digit_04_MCPB 0;
BA_ "GenSigTimeoutTime_DTCM" SG_ 2651930713 Digit_04_MCPB 0;
BA_ "GenSigTimeoutTime_ECM" SG_ 2651930713 Digit_04_MCPB 0;
BA_ "GenSigTimeoutTime_EVCU2" SG_ 2651930713 Digit_04_MCPB 0;
BA_ "GenSigTimeoutTime_GNMM" SG_ 2651930713 Digit_04_MCPB 0;
BA_ "GenSigTimeoutTime_HCP" SG_ 2651930713 Digit_04_MCPB 0;
BA_ "GenSigTimeoutTime_IPC" SG_ 2651930713 Digit_04_MCPB 0;
BA_ "GenSigTimeoutTime_RFHM" SG_ 2651930713 Digit_04_MCPB 0;
BA_ "GenSigTimeoutTime_SGW" SG_ 2651930713 Digit_04_MCPB 0;
BA_ "GenSigTimeoutTime_TCM" SG_ 2651930713 Digit_04_MCPB 0;
BA_ "GenSigTimeoutTime_AGSM" SG_ 2651930713 Digit_05_MCPB 0;
BA_ "GenSigTimeoutTime_BSM" SG_ 2651930713 Digit_05_MCPB 0;
BA_ "GenSigTimeoutTime_CADM" SG_ 2651930713 Digit_05_MCPB 0;
BA_ "GenSigTimeoutTime_DMSM" SG_ 2651930713 Digit_05_MCPB 0;
BA_ "GenSigTimeoutTime_DTCM" SG_ 2651930713 Digit_05_MCPB 0;
BA_ "GenSigTimeoutTime_ECM" SG_ 2651930713 Digit_05_MCPB 0;
BA_ "GenSigTimeoutTime_EVCU2" SG_ 2651930713 Digit_05_MCPB 0;
BA_ "GenSigTimeoutTime_GNMM" SG_ 2651930713 Digit_05_MCPB 0;
BA_ "GenSigTimeoutTime_HCP" SG_ 2651930713 Digit_05_MCPB 0;
BA_ "GenSigTimeoutTime_IPC" SG_ 2651930713 Digit_05_MCPB 0;
BA_ "GenSigTimeoutTime_RFHM" SG_ 2651930713 Digit_05_MCPB 0;
BA_ "GenSigTimeoutTime_SGW" SG_ 2651930713 Digit_05_MCPB 0;
BA_ "GenSigTimeoutTime_TCM" SG_ 2651930713 Digit_05_MCPB 0;
BA_ "GenSigTimeoutTime_AGSM" SG_ 2651930713 Digit_06_MCPB 0;
BA_ "GenSigTimeoutTime_BSM" SG_ 2651930713 Digit_06_MCPB 0;
BA_ "GenSigTimeoutTime_CADM" SG_ 2651930713 Digit_06_MCPB 0;
BA_ "GenSigTimeoutTime_DMSM" SG_ 2651930713 Digit_06_MCPB 0;
BA_ "GenSigTimeoutTime_DTCM" SG_ 2651930713 Digit_06_MCPB 0;
BA_ "GenSigTimeoutTime_ECM" SG_ 2651930713 Digit_06_MCPB 0;
BA_ "GenSigTimeoutTime_EVCU2" SG_ 2651930713 Digit_06_MCPB 0;
BA_ "GenSigTimeoutTime_GNMM" SG_ 2651930713 Digit_06_MCPB 0;
BA_ "GenSigTimeoutTime_HCP" SG_ 2651930713 Digit_06_MCPB 0;
BA_ "GenSigTimeoutTime_IPC" SG_ 2651930713 Digit_06_MCPB 0;
BA_ "GenSigTimeoutTime_RFHM" SG_ 2651930713 Digit_06_MCPB 0;
BA_ "GenSigTimeoutTime_SGW" SG_ 2651930713 Digit_06_MCPB 0;
BA_ "GenSigTimeoutTime_TCM" SG_ 2651930713 Digit_06_MCPB 0;
BA_ "GenSigTimeoutTime_AGSM" SG_ 2651930713 Digit_07_MCPB 0;
BA_ "GenSigTimeoutTime_BSM" SG_ 2651930713 Digit_07_MCPB 0;
BA_ "GenSigTimeoutTime_CADM" SG_ 2651930713 Digit_07_MCPB 0;
BA_ "GenSigTimeoutTime_DMSM" SG_ 2651930713 Digit_07_MCPB 0;
BA_ "GenSigTimeoutTime_DTCM" SG_ 2651930713 Digit_07_MCPB 0;
BA_ "GenSigTimeoutTime_ECM" SG_ 2651930713 Digit_07_MCPB 0;
BA_ "GenSigTimeoutTime_EVCU2" SG_ 2651930713 Digit_07_MCPB 0;
BA_ "GenSigTimeoutTime_GNMM" SG_ 2651930713 Digit_07_MCPB 0;
BA_ "GenSigTimeoutTime_HCP" SG_ 2651930713 Digit_07_MCPB 0;
BA_ "GenSigTimeoutTime_IPC" SG_ 2651930713 Digit_07_MCPB 0;
BA_ "GenSigTimeoutTime_RFHM" SG_ 2651930713 Digit_07_MCPB 0;
BA_ "GenSigTimeoutTime_SGW" SG_ 2651930713 Digit_07_MCPB 0;
BA_ "GenSigTimeoutTime_TCM" SG_ 2651930713 Digit_07_MCPB 0;
BA_ "GenSigTimeoutTime_AGSM" SG_ 2651930713 Digit_08_MCPB 0;
BA_ "GenSigTimeoutTime_BSM" SG_ 2651930713 Digit_08_MCPB 0;
BA_ "GenSigTimeoutTime_CADM" SG_ 2651930713 Digit_08_MCPB 0;
BA_ "GenSigTimeoutTime_DMSM" SG_ 2651930713 Digit_08_MCPB 0;
BA_ "GenSigTimeoutTime_DTCM" SG_ 2651930713 Digit_08_MCPB 0;
BA_ "GenSigTimeoutTime_ECM" SG_ 2651930713 Digit_08_MCPB 0;
BA_ "GenSigTimeoutTime_EVCU2" SG_ 2651930713 Digit_08_MCPB 0;
BA_ "GenSigTimeoutTime_GNMM" SG_ 2651930713 Digit_08_MCPB 0;
BA_ "GenSigTimeoutTime_HCP" SG_ 2651930713 Digit_08_MCPB 0;
BA_ "GenSigTimeoutTime_IPC" SG_ 2651930713 Digit_08_MCPB 0;
BA_ "GenSigTimeoutTime_RFHM" SG_ 2651930713 Digit_08_MCPB 0;
BA_ "GenSigTimeoutTime_SGW" SG_ 2651930713 Digit_08_MCPB 0;
BA_ "GenSigTimeoutTime_TCM" SG_ 2651930713 Digit_08_MCPB 0;
BA_ "GenSigTimeoutTime_AGSM" SG_ 2651930713 Digit_09_MCPB 0;
BA_ "GenSigTimeoutTime_BSM" SG_ 2651930713 Digit_09_MCPB 0;
BA_ "GenSigTimeoutTime_CADM" SG_ 2651930713 Digit_09_MCPB 0;
BA_ "GenSigTimeoutTime_DMSM" SG_ 2651930713 Digit_09_MCPB 0;
BA_ "GenSigTimeoutTime_DTCM" SG_ 2651930713 Digit_09_MCPB 0;
BA_ "GenSigTimeoutTime_ECM" SG_ 2651930713 Digit_09_MCPB 0;
BA_ "GenSigTimeoutTime_EVCU2" SG_ 2651930713 Digit_09_MCPB 0;
BA_ "GenSigTimeoutTime_GNMM" SG_ 2651930713 Digit_09_MCPB 0;
BA_ "GenSigTimeoutTime_HCP" SG_ 2651930713 Digit_09_MCPB 0;
BA_ "GenSigTimeoutTime_IPC" SG_ 2651930713 Digit_09_MCPB 0;
BA_ "GenSigTimeoutTime_RFHM" SG_ 2651930713 Digit_09_MCPB 0;
BA_ "GenSigTimeoutTime_SGW" SG_ 2651930713 Digit_09_MCPB 0;
BA_ "GenSigTimeoutTime_TCM" SG_ 2651930713 Digit_09_MCPB 0;
BA_ "GenSigTimeoutTime_AGSM" SG_ 2651930713 Digit_10_MCPB 0;
BA_ "GenSigTimeoutTime_BSM" SG_ 2651930713 Digit_10_MCPB 0;
BA_ "GenSigTimeoutTime_CADM" SG_ 2651930713 Digit_10_MCPB 0;
BA_ "GenSigTimeoutTime_DMSM" SG_ 2651930713 Digit_10_MCPB 0;
BA_ "GenSigTimeoutTime_DTCM" SG_ 2651930713 Digit_10_MCPB 0;
BA_ "GenSigTimeoutTime_ECM" SG_ 2651930713 Digit_10_MCPB 0;
BA_ "GenSigTimeoutTime_EVCU2" SG_ 2651930713 Digit_10_MCPB 0;
BA_ "GenSigTimeoutTime_GNMM" SG_ 2651930713 Digit_10_MCPB 0;
BA_ "GenSigTimeoutTime_HCP" SG_ 2651930713 Digit_10_MCPB 0;
BA_ "GenSigTimeoutTime_IPC" SG_ 2651930713 Digit_10_MCPB 0;
BA_ "GenSigTimeoutTime_RFHM" SG_ 2651930713 Digit_10_MCPB 0;
BA_ "GenSigTimeoutTime_SGW" SG_ 2651930713 Digit_10_MCPB 0;
BA_ "GenSigTimeoutTime_TCM" SG_ 2651930713 Digit_10_MCPB 0;
BA_ "GenSigTimeoutTime_AGSM" SG_ 2651930713 Digit_11_MCPB 0;
BA_ "GenSigTimeoutTime_BSM" SG_ 2651930713 Digit_11_MCPB 0;
BA_ "GenSigTimeoutTime_CADM" SG_ 2651930713 Digit_11_MCPB 0;
BA_ "GenSigTimeoutTime_DMSM" SG_ 2651930713 Digit_11_MCPB 0;
BA_ "GenSigTimeoutTime_DTCM" SG_ 2651930713 Digit_11_MCPB 0;
BA_ "GenSigTimeoutTime_ECM" SG_ 2651930713 Digit_11_MCPB 0;
BA_ "GenSigTimeoutTime_EVCU2" SG_ 2651930713 Digit_11_MCPB 0;
BA_ "GenSigTimeoutTime_GNMM" SG_ 2651930713 Digit_11_MCPB 0;
BA_ "GenSigTimeoutTime_HCP" SG_ 2651930713 Digit_11_MCPB 0;
BA_ "GenSigTimeoutTime_IPC" SG_ 2651930713 Digit_11_MCPB 0;
BA_ "GenSigTimeoutTime_RFHM" SG_ 2651930713 Digit_11_MCPB 0;
BA_ "GenSigTimeoutTime_SGW" SG_ 2651930713 Digit_11_MCPB 0;
BA_ "GenSigTimeoutTime_TCM" SG_ 2651930713 Digit_11_MCPB 0;
BA_ "GenSigSendType" SG_ 2651930689 Digit_01_RFHM 1;
BA_ "GenSigTimeoutTime_AGSM" SG_ 2651930689 Digit_01_RFHM 0;
BA_ "GenSigTimeoutTime_BSM" SG_ 2651930689 Digit_01_RFHM 0;
BA_ "GenSigTimeoutTime_CADM" SG_ 2651930689 Digit_01_RFHM 0;
BA_ "GenSigTimeoutTime_DMSM" SG_ 2651930689 Digit_01_RFHM 0;
BA_ "GenSigTimeoutTime_DTCM" SG_ 2651930689 Digit_01_RFHM 0;
BA_ "GenSigTimeoutTime_ECM" SG_ 2651930689 Digit_01_RFHM 0;
BA_ "GenSigTimeoutTime_EVCU2" SG_ 2651930689 Digit_01_RFHM 0;
BA_ "GenSigTimeoutTime_GNMM" SG_ 2651930689 Digit_01_RFHM 0;
BA_ "GenSigTimeoutTime_HCP" SG_ 2651930689 Digit_01_RFHM 0;
BA_ "GenSigTimeoutTime_IPC" SG_ 2651930689 Digit_01_RFHM 0;
BA_ "GenSigTimeoutTime_RFHM" SG_ 2651930689 Digit_01_RFHM 0;
BA_ "GenSigTimeoutTime_SGW" SG_ 2651930689 Digit_01_RFHM 0;
BA_ "GenSigTimeoutTime_TCM" SG_ 2651930689 Digit_01_RFHM 0;
BA_ "GenSigTimeoutTime_AGSM" SG_ 2651930689 Digit_02_RFHM 0;
BA_ "GenSigTimeoutTime_BSM" SG_ 2651930689 Digit_02_RFHM 0;
BA_ "GenSigTimeoutTime_CADM" SG_ 2651930689 Digit_02_RFHM 0;
BA_ "GenSigTimeoutTime_DMSM" SG_ 2651930689 Digit_02_RFHM 0;
BA_ "GenSigTimeoutTime_DTCM" SG_ 2651930689 Digit_02_RFHM 0;
BA_ "GenSigTimeoutTime_ECM" SG_ 2651930689 Digit_02_RFHM 0;
BA_ "GenSigTimeoutTime_EVCU2" SG_ 2651930689 Digit_02_RFHM 0;
BA_ "GenSigTimeoutTime_GNMM" SG_ 2651930689 Digit_02_RFHM 0;
BA_ "GenSigTimeoutTime_HCP" SG_ 2651930689 Digit_02_RFHM 0;
BA_ "GenSigTimeoutTime_IPC" SG_ 2651930689 Digit_02_RFHM 0;
BA_ "GenSigTimeoutTime_RFHM" SG_ 2651930689 Digit_02_RFHM 0;
BA_ "GenSigTimeoutTime_SGW" SG_ 2651930689 Digit_02_RFHM 0;
BA_ "GenSigTimeoutTime_TCM" SG_ 2651930689 Digit_02_RFHM 0;
BA_ "GenSigTimeoutTime_AGSM" SG_ 2651930689 Digit_03_RFHM 0;
BA_ "GenSigTimeoutTime_BSM" SG_ 2651930689 Digit_03_RFHM 0;
BA_ "GenSigTimeoutTime_CADM" SG_ 2651930689 Digit_03_RFHM 0;
BA_ "GenSigTimeoutTime_DMSM" SG_ 2651930689 Digit_03_RFHM 0;
BA_ "GenSigTimeoutTime_DTCM" SG_ 2651930689 Digit_03_RFHM 0;
BA_ "GenSigTimeoutTime_ECM" SG_ 2651930689 Digit_03_RFHM 0;
BA_ "GenSigTimeoutTime_EVCU2" SG_ 2651930689 Digit_03_RFHM 0;
BA_ "GenSigTimeoutTime_GNMM" SG_ 2651930689 Digit_03_RFHM 0;
BA_ "GenSigTimeoutTime_HCP" SG_ 2651930689 Digit_03_RFHM 0;
BA_ "GenSigTimeoutTime_IPC" SG_ 2651930689 Digit_03_RFHM 0;
BA_ "GenSigTimeoutTime_RFHM" SG_ 2651930689 Digit_03_RFHM 0;
BA_ "GenSigTimeoutTime_SGW" SG_ 2651930689 Digit_03_RFHM 0;
BA_ "GenSigTimeoutTime_TCM" SG_ 2651930689 Digit_03_RFHM 0;
BA_ "GenSigTimeoutTime_AGSM" SG_ 2651930689 Digit_04_RFHM 0;
BA_ "GenSigTimeoutTime_BSM" SG_ 2651930689 Digit_04_RFHM 0;
BA_ "GenSigTimeoutTime_CADM" SG_ 2651930689 Digit_04_RFHM 0;
BA_ "GenSigTimeoutTime_DMSM" SG_ 2651930689 Digit_04_RFHM 0;
BA_ "GenSigTimeoutTime_DTCM" SG_ 2651930689 Digit_04_RFHM 0;
BA_ "GenSigTimeoutTime_ECM" SG_ 2651930689 Digit_04_RFHM 0;
BA_ "GenSigTimeoutTime_EVCU2" SG_ 2651930689 Digit_04_RFHM 0;
BA_ "GenSigTimeoutTime_GNMM" SG_ 2651930689 Digit_04_RFHM 0;
BA_ "GenSigTimeoutTime_HCP" SG_ 2651930689 Digit_04_RFHM 0;
BA_ "GenSigTimeoutTime_IPC" SG_ 2651930689 Digit_04_RFHM 0;
BA_ "GenSigTimeoutTime_RFHM" SG_ 2651930689 Digit_04_RFHM 0;
BA_ "GenSigTimeoutTime_SGW" SG_ 2651930689 Digit_04_RFHM 0;
BA_ "GenSigTimeoutTime_TCM" SG_ 2651930689 Digit_04_RFHM 0;
BA_ "GenSigTimeoutTime_AGSM" SG_ 2651930689 Digit_05_RFHM 0;
BA_ "GenSigTimeoutTime_BSM" SG_ 2651930689 Digit_05_RFHM 0;
BA_ "GenSigTimeoutTime_CADM" SG_ 2651930689 Digit_05_RFHM 0;
BA_ "GenSigTimeoutTime_DMSM" SG_ 2651930689 Digit_05_RFHM 0;
BA_ "GenSigTimeoutTime_DTCM" SG_ 2651930689 Digit_05_RFHM 0;
BA_ "GenSigTimeoutTime_ECM" SG_ 2651930689 Digit_05_RFHM 0;
BA_ "GenSigTimeoutTime_EVCU2" SG_ 2651930689 Digit_05_RFHM 0;
BA_ "GenSigTimeoutTime_GNMM" SG_ 2651930689 Digit_05_RFHM 0;
BA_ "GenSigTimeoutTime_HCP" SG_ 2651930689 Digit_05_RFHM 0;
BA_ "GenSigTimeoutTime_IPC" SG_ 2651930689 Digit_05_RFHM 0;
BA_ "GenSigTimeoutTime_RFHM" SG_ 2651930689 Digit_05_RFHM 0;
BA_ "GenSigTimeoutTime_SGW" SG_ 2651930689 Digit_05_RFHM 0;
BA_ "GenSigTimeoutTime_TCM" SG_ 2651930689 Digit_05_RFHM 0;
BA_ "GenSigTimeoutTime_AGSM" SG_ 2651930689 Digit_06_RFHM 0;
BA_ "GenSigTimeoutTime_BSM" SG_ 2651930689 Digit_06_RFHM 0;
BA_ "GenSigTimeoutTime_CADM" SG_ 2651930689 Digit_06_RFHM 0;
BA_ "GenSigTimeoutTime_DMSM" SG_ 2651930689 Digit_06_RFHM 0;
BA_ "GenSigTimeoutTime_DTCM" SG_ 2651930689 Digit_06_RFHM 0;
BA_ "GenSigTimeoutTime_ECM" SG_ 2651930689 Digit_06_RFHM 0;
BA_ "GenSigTimeoutTime_EVCU2" SG_ 2651930689 Digit_06_RFHM 0;
BA_ "GenSigTimeoutTime_GNMM" SG_ 2651930689 Digit_06_RFHM 0;
BA_ "GenSigTimeoutTime_HCP" SG_ 2651930689 Digit_06_RFHM 0;
BA_ "GenSigTimeoutTime_IPC" SG_ 2651930689 Digit_06_RFHM 0;
BA_ "GenSigTimeoutTime_RFHM" SG_ 2651930689 Digit_06_RFHM 0;
BA_ "GenSigTimeoutTime_SGW" SG_ 2651930689 Digit_06_RFHM 0;
BA_ "GenSigTimeoutTime_TCM" SG_ 2651930689 Digit_06_RFHM 0;
BA_ "GenSigTimeoutTime_AGSM" SG_ 2651930689 Digit_07_RFHM 0;
BA_ "GenSigTimeoutTime_BSM" SG_ 2651930689 Digit_07_RFHM 0;
BA_ "GenSigTimeoutTime_CADM" SG_ 2651930689 Digit_07_RFHM 0;
BA_ "GenSigTimeoutTime_DMSM" SG_ 2651930689 Digit_07_RFHM 0;
BA_ "GenSigTimeoutTime_DTCM" SG_ 2651930689 Digit_07_RFHM 0;
BA_ "GenSigTimeoutTime_ECM" SG_ 2651930689 Digit_07_RFHM 0;
BA_ "GenSigTimeoutTime_EVCU2" SG_ 2651930689 Digit_07_RFHM 0;
BA_ "GenSigTimeoutTime_GNMM" SG_ 2651930689 Digit_07_RFHM 0;
BA_ "GenSigTimeoutTime_HCP" SG_ 2651930689 Digit_07_RFHM 0;
BA_ "GenSigTimeoutTime_IPC" SG_ 2651930689 Digit_07_RFHM 0;
BA_ "GenSigTimeoutTime_RFHM" SG_ 2651930689 Digit_07_RFHM 0;
BA_ "GenSigTimeoutTime_SGW" SG_ 2651930689 Digit_07_RFHM 0;
BA_ "GenSigTimeoutTime_TCM" SG_ 2651930689 Digit_07_RFHM 0;
BA_ "GenSigTimeoutTime_AGSM" SG_ 2651930689 Digit_08_RFHM 0;
BA_ "GenSigTimeoutTime_BSM" SG_ 2651930689 Digit_08_RFHM 0;
BA_ "GenSigTimeoutTime_CADM" SG_ 2651930689 Digit_08_RFHM 0;
BA_ "GenSigTimeoutTime_DMSM" SG_ 2651930689 Digit_08_RFHM 0;
BA_ "GenSigTimeoutTime_DTCM" SG_ 2651930689 Digit_08_RFHM 0;
BA_ "GenSigTimeoutTime_ECM" SG_ 2651930689 Digit_08_RFHM 0;
BA_ "GenSigTimeoutTime_EVCU2" SG_ 2651930689 Digit_08_RFHM 0;
BA_ "GenSigTimeoutTime_GNMM" SG_ 2651930689 Digit_08_RFHM 0;
BA_ "GenSigTimeoutTime_HCP" SG_ 2651930689 Digit_08_RFHM 0;
BA_ "GenSigTimeoutTime_IPC" SG_ 2651930689 Digit_08_RFHM 0;
BA_ "GenSigTimeoutTime_RFHM" SG_ 2651930689 Digit_08_RFHM 0;
BA_ "GenSigTimeoutTime_SGW" SG_ 2651930689 Digit_08_RFHM 0;
BA_ "GenSigTimeoutTime_TCM" SG_ 2651930689 Digit_08_RFHM 0;
BA_ "GenSigTimeoutTime_AGSM" SG_ 2651930689 Digit_09_RFHM 0;
BA_ "GenSigTimeoutTime_BSM" SG_ 2651930689 Digit_09_RFHM 0;
BA_ "GenSigTimeoutTime_CADM" SG_ 2651930689 Digit_09_RFHM 0;
BA_ "GenSigTimeoutTime_DMSM" SG_ 2651930689 Digit_09_RFHM 0;
BA_ "GenSigTimeoutTime_DTCM" SG_ 2651930689 Digit_09_RFHM 0;
BA_ "GenSigTimeoutTime_ECM" SG_ 2651930689 Digit_09_RFHM 0;
BA_ "GenSigTimeoutTime_EVCU2" SG_ 2651930689 Digit_09_RFHM 0;
BA_ "GenSigTimeoutTime_GNMM" SG_ 2651930689 Digit_09_RFHM 0;
BA_ "GenSigTimeoutTime_HCP" SG_ 2651930689 Digit_09_RFHM 0;
BA_ "GenSigTimeoutTime_IPC" SG_ 2651930689 Digit_09_RFHM 0;
BA_ "GenSigTimeoutTime_RFHM" SG_ 2651930689 Digit_09_RFHM 0;
BA_ "GenSigTimeoutTime_SGW" SG_ 2651930689 Digit_09_RFHM 0;
BA_ "GenSigTimeoutTime_TCM" SG_ 2651930689 Digit_09_RFHM 0;
BA_ "GenSigTimeoutTime_AGSM" SG_ 2651930689 Digit_10_RFHM 0;
BA_ "GenSigTimeoutTime_BSM" SG_ 2651930689 Digit_10_RFHM 0;
BA_ "GenSigTimeoutTime_CADM" SG_ 2651930689 Digit_10_RFHM 0;
BA_ "GenSigTimeoutTime_DMSM" SG_ 2651930689 Digit_10_RFHM 0;
BA_ "GenSigTimeoutTime_DTCM" SG_ 2651930689 Digit_10_RFHM 0;
BA_ "GenSigTimeoutTime_ECM" SG_ 2651930689 Digit_10_RFHM 0;
BA_ "GenSigTimeoutTime_EVCU2" SG_ 2651930689 Digit_10_RFHM 0;
BA_ "GenSigTimeoutTime_GNMM" SG_ 2651930689 Digit_10_RFHM 0;
BA_ "GenSigTimeoutTime_HCP" SG_ 2651930689 Digit_10_RFHM 0;
BA_ "GenSigTimeoutTime_IPC" SG_ 2651930689 Digit_10_RFHM 0;
BA_ "GenSigTimeoutTime_RFHM" SG_ 2651930689 Digit_10_RFHM 0;
BA_ "GenSigTimeoutTime_SGW" SG_ 2651930689 Digit_10_RFHM 0;
BA_ "GenSigTimeoutTime_TCM" SG_ 2651930689 Digit_10_RFHM 0;
BA_ "GenSigTimeoutTime_AGSM" SG_ 2651930689 Digit_11_RFHM 0;
BA_ "GenSigTimeoutTime_BSM" SG_ 2651930689 Digit_11_RFHM 0;
BA_ "GenSigTimeoutTime_CADM" SG_ 2651930689 Digit_11_RFHM 0;
BA_ "GenSigTimeoutTime_DMSM" SG_ 2651930689 Digit_11_RFHM 0;
BA_ "GenSigTimeoutTime_DTCM" SG_ 2651930689 Digit_11_RFHM 0;
BA_ "GenSigTimeoutTime_ECM" SG_ 2651930689 Digit_11_RFHM 0;
BA_ "GenSigTimeoutTime_EVCU2" SG_ 2651930689 Digit_11_RFHM 0;
BA_ "GenSigTimeoutTime_GNMM" SG_ 2651930689 Digit_11_RFHM 0;
BA_ "GenSigTimeoutTime_HCP" SG_ 2651930689 Digit_11_RFHM 0;
BA_ "GenSigTimeoutTime_IPC" SG_ 2651930689 Digit_11_RFHM 0;
BA_ "GenSigTimeoutTime_RFHM" SG_ 2651930689 Digit_11_RFHM 0;
BA_ "GenSigTimeoutTime_SGW" SG_ 2651930689 Digit_11_RFHM 0;
BA_ "GenSigTimeoutTime_TCM" SG_ 2651930689 Digit_11_RFHM 0;
BA_ "GenSigSendType" SG_ 2651930736 Digit_01_SGW 1;
BA_ "GenSigTimeoutTime_AGSM" SG_ 2651930736 Digit_01_SGW 0;
BA_ "GenSigTimeoutTime_BSM" SG_ 2651930736 Digit_01_SGW 0;
BA_ "GenSigTimeoutTime_CADM" SG_ 2651930736 Digit_01_SGW 0;
BA_ "GenSigTimeoutTime_DMSM" SG_ 2651930736 Digit_01_SGW 0;
BA_ "GenSigTimeoutTime_DTCM" SG_ 2651930736 Digit_01_SGW 0;
BA_ "GenSigTimeoutTime_ECM" SG_ 2651930736 Digit_01_SGW 0;
BA_ "GenSigTimeoutTime_EVCU2" SG_ 2651930736 Digit_01_SGW 0;
BA_ "GenSigTimeoutTime_GNMM" SG_ 2651930736 Digit_01_SGW 0;
BA_ "GenSigTimeoutTime_HCP" SG_ 2651930736 Digit_01_SGW 0;
BA_ "GenSigTimeoutTime_IPC" SG_ 2651930736 Digit_01_SGW 0;
BA_ "GenSigTimeoutTime_RFHM" SG_ 2651930736 Digit_01_SGW 0;
BA_ "GenSigTimeoutTime_SGW" SG_ 2651930736 Digit_01_SGW 0;
BA_ "GenSigTimeoutTime_TCM" SG_ 2651930736 Digit_01_SGW 0;
BA_ "GenSigTimeoutTime_AGSM" SG_ 2651930736 Digit_02_SGW 0;
BA_ "GenSigTimeoutTime_BSM" SG_ 2651930736 Digit_02_SGW 0;
BA_ "GenSigTimeoutTime_CADM" SG_ 2651930736 Digit_02_SGW 0;
BA_ "GenSigTimeoutTime_DMSM" SG_ 2651930736 Digit_02_SGW 0;
BA_ "GenSigTimeoutTime_DTCM" SG_ 2651930736 Digit_02_SGW 0;
BA_ "GenSigTimeoutTime_ECM" SG_ 2651930736 Digit_02_SGW 0;
BA_ "GenSigTimeoutTime_EVCU2" SG_ 2651930736 Digit_02_SGW 0;
BA_ "GenSigTimeoutTime_GNMM" SG_ 2651930736 Digit_02_SGW 0;
BA_ "GenSigTimeoutTime_HCP" SG_ 2651930736 Digit_02_SGW 0;
BA_ "GenSigTimeoutTime_IPC" SG_ 2651930736 Digit_02_SGW 0;
BA_ "GenSigTimeoutTime_RFHM" SG_ 2651930736 Digit_02_SGW 0;
BA_ "GenSigTimeoutTime_SGW" SG_ 2651930736 Digit_02_SGW 0;
BA_ "GenSigTimeoutTime_TCM" SG_ 2651930736 Digit_02_SGW 0;
BA_ "GenSigTimeoutTime_AGSM" SG_ 2651930736 Digit_03_SGW 0;
BA_ "GenSigTimeoutTime_BSM" SG_ 2651930736 Digit_03_SGW 0;
BA_ "GenSigTimeoutTime_CADM" SG_ 2651930736 Digit_03_SGW 0;
BA_ "GenSigTimeoutTime_DMSM" SG_ 2651930736 Digit_03_SGW 0;
BA_ "GenSigTimeoutTime_DTCM" SG_ 2651930736 Digit_03_SGW 0;
BA_ "GenSigTimeoutTime_ECM" SG_ 2651930736 Digit_03_SGW 0;
BA_ "GenSigTimeoutTime_EVCU2" SG_ 2651930736 Digit_03_SGW 0;
BA_ "GenSigTimeoutTime_GNMM" SG_ 2651930736 Digit_03_SGW 0;
BA_ "GenSigTimeoutTime_HCP" SG_ 2651930736 Digit_03_SGW 0;
BA_ "GenSigTimeoutTime_IPC" SG_ 2651930736 Digit_03_SGW 0;
BA_ "GenSigTimeoutTime_RFHM" SG_ 2651930736 Digit_03_SGW 0;
BA_ "GenSigTimeoutTime_SGW" SG_ 2651930736 Digit_03_SGW 0;
BA_ "GenSigTimeoutTime_TCM" SG_ 2651930736 Digit_03_SGW 0;
BA_ "GenSigTimeoutTime_AGSM" SG_ 2651930736 Digit_04_SGW 0;
BA_ "GenSigTimeoutTime_BSM" SG_ 2651930736 Digit_04_SGW 0;
BA_ "GenSigTimeoutTime_CADM" SG_ 2651930736 Digit_04_SGW 0;
BA_ "GenSigTimeoutTime_DMSM" SG_ 2651930736 Digit_04_SGW 0;
BA_ "GenSigTimeoutTime_DTCM" SG_ 2651930736 Digit_04_SGW 0;
BA_ "GenSigTimeoutTime_ECM" SG_ 2651930736 Digit_04_SGW 0;
BA_ "GenSigTimeoutTime_EVCU2" SG_ 2651930736 Digit_04_SGW 0;
BA_ "GenSigTimeoutTime_GNMM" SG_ 2651930736 Digit_04_SGW 0;
BA_ "GenSigTimeoutTime_HCP" SG_ 2651930736 Digit_04_SGW 0;
BA_ "GenSigTimeoutTime_IPC" SG_ 2651930736 Digit_04_SGW 0;
BA_ "GenSigTimeoutTime_RFHM" SG_ 2651930736 Digit_04_SGW 0;
BA_ "GenSigTimeoutTime_SGW" SG_ 2651930736 Digit_04_SGW 0;
BA_ "GenSigTimeoutTime_TCM" SG_ 2651930736 Digit_04_SGW 0;
BA_ "GenSigTimeoutTime_AGSM" SG_ 2651930736 Digit_05_SGW 0;
BA_ "GenSigTimeoutTime_BSM" SG_ 2651930736 Digit_05_SGW 0;
BA_ "GenSigTimeoutTime_CADM" SG_ 2651930736 Digit_05_SGW 0;
BA_ "GenSigTimeoutTime_DMSM" SG_ 2651930736 Digit_05_SGW 0;
BA_ "GenSigTimeoutTime_DTCM" SG_ 2651930736 Digit_05_SGW 0;
BA_ "GenSigTimeoutTime_ECM" SG_ 2651930736 Digit_05_SGW 0;
BA_ "GenSigTimeoutTime_EVCU2" SG_ 2651930736 Digit_05_SGW 0;
BA_ "GenSigTimeoutTime_GNMM" SG_ 2651930736 Digit_05_SGW 0;
BA_ "GenSigTimeoutTime_HCP" SG_ 2651930736 Digit_05_SGW 0;
BA_ "GenSigTimeoutTime_IPC" SG_ 2651930736 Digit_05_SGW 0;
BA_ "GenSigTimeoutTime_RFHM" SG_ 2651930736 Digit_05_SGW 0;
BA_ "GenSigTimeoutTime_SGW" SG_ 2651930736 Digit_05_SGW 0;
BA_ "GenSigTimeoutTime_TCM" SG_ 2651930736 Digit_05_SGW 0;
BA_ "GenSigTimeoutTime_AGSM" SG_ 2651930736 Digit_06_SGW 0;
BA_ "GenSigTimeoutTime_BSM" SG_ 2651930736 Digit_06_SGW 0;
BA_ "GenSigTimeoutTime_CADM" SG_ 2651930736 Digit_06_SGW 0;
BA_ "GenSigTimeoutTime_DMSM" SG_ 2651930736 Digit_06_SGW 0;
BA_ "GenSigTimeoutTime_DTCM" SG_ 2651930736 Digit_06_SGW 0;
BA_ "GenSigTimeoutTime_ECM" SG_ 2651930736 Digit_06_SGW 0;
BA_ "GenSigTimeoutTime_EVCU2" SG_ 2651930736 Digit_06_SGW 0;
BA_ "GenSigTimeoutTime_GNMM" SG_ 2651930736 Digit_06_SGW 0;
BA_ "GenSigTimeoutTime_HCP" SG_ 2651930736 Digit_06_SGW 0;
BA_ "GenSigTimeoutTime_IPC" SG_ 2651930736 Digit_06_SGW 0;
BA_ "GenSigTimeoutTime_RFHM" SG_ 2651930736 Digit_06_SGW 0;
BA_ "GenSigTimeoutTime_SGW" SG_ 2651930736 Digit_06_SGW 0;
BA_ "GenSigTimeoutTime_TCM" SG_ 2651930736 Digit_06_SGW 0;
BA_ "GenSigTimeoutTime_AGSM" SG_ 2651930736 Digit_07_SGW 0;
BA_ "GenSigTimeoutTime_BSM" SG_ 2651930736 Digit_07_SGW 0;
BA_ "GenSigTimeoutTime_CADM" SG_ 2651930736 Digit_07_SGW 0;
BA_ "GenSigTimeoutTime_DMSM" SG_ 2651930736 Digit_07_SGW 0;
BA_ "GenSigTimeoutTime_DTCM" SG_ 2651930736 Digit_07_SGW 0;
BA_ "GenSigTimeoutTime_ECM" SG_ 2651930736 Digit_07_SGW 0;
BA_ "GenSigTimeoutTime_EVCU2" SG_ 2651930736 Digit_07_SGW 0;
BA_ "GenSigTimeoutTime_GNMM" SG_ 2651930736 Digit_07_SGW 0;
BA_ "GenSigTimeoutTime_HCP" SG_ 2651930736 Digit_07_SGW 0;
BA_ "GenSigTimeoutTime_IPC" SG_ 2651930736 Digit_07_SGW 0;
BA_ "GenSigTimeoutTime_RFHM" SG_ 2651930736 Digit_07_SGW 0;
BA_ "GenSigTimeoutTime_SGW" SG_ 2651930736 Digit_07_SGW 0;
BA_ "GenSigTimeoutTime_TCM" SG_ 2651930736 Digit_07_SGW 0;
BA_ "GenSigTimeoutTime_AGSM" SG_ 2651930736 Digit_08_SGW 0;
BA_ "GenSigTimeoutTime_BSM" SG_ 2651930736 Digit_08_SGW 0;
BA_ "GenSigTimeoutTime_CADM" SG_ 2651930736 Digit_08_SGW 0;
BA_ "GenSigTimeoutTime_DMSM" SG_ 2651930736 Digit_08_SGW 0;
BA_ "GenSigTimeoutTime_DTCM" SG_ 2651930736 Digit_08_SGW 0;
BA_ "GenSigTimeoutTime_ECM" SG_ 2651930736 Digit_08_SGW 0;
BA_ "GenSigTimeoutTime_EVCU2" SG_ 2651930736 Digit_08_SGW 0;
BA_ "GenSigTimeoutTime_GNMM" SG_ 2651930736 Digit_08_SGW 0;
BA_ "GenSigTimeoutTime_HCP" SG_ 2651930736 Digit_08_SGW 0;
BA_ "GenSigTimeoutTime_IPC" SG_ 2651930736 Digit_08_SGW 0;
BA_ "GenSigTimeoutTime_RFHM" SG_ 2651930736 Digit_08_SGW 0;
BA_ "GenSigTimeoutTime_SGW" SG_ 2651930736 Digit_08_SGW 0;
BA_ "GenSigTimeoutTime_TCM" SG_ 2651930736 Digit_08_SGW 0;
BA_ "GenSigTimeoutTime_AGSM" SG_ 2651930736 Digit_09_SGW 0;
BA_ "GenSigTimeoutTime_BSM" SG_ 2651930736 Digit_09_SGW 0;
BA_ "GenSigTimeoutTime_CADM" SG_ 2651930736 Digit_09_SGW 0;
BA_ "GenSigTimeoutTime_DMSM" SG_ 2651930736 Digit_09_SGW 0;
BA_ "GenSigTimeoutTime_DTCM" SG_ 2651930736 Digit_09_SGW 0;
BA_ "GenSigTimeoutTime_ECM" SG_ 2651930736 Digit_09_SGW 0;
BA_ "GenSigTimeoutTime_EVCU2" SG_ 2651930736 Digit_09_SGW 0;
BA_ "GenSigTimeoutTime_GNMM" SG_ 2651930736 Digit_09_SGW 0;
BA_ "GenSigTimeoutTime_HCP" SG_ 2651930736 Digit_09_SGW 0;
BA_ "GenSigTimeoutTime_IPC" SG_ 2651930736 Digit_09_SGW 0;
BA_ "GenSigTimeoutTime_RFHM" SG_ 2651930736 Digit_09_SGW 0;
BA_ "GenSigTimeoutTime_SGW" SG_ 2651930736 Digit_09_SGW 0;
BA_ "GenSigTimeoutTime_TCM" SG_ 2651930736 Digit_09_SGW 0;
BA_ "GenSigTimeoutTime_AGSM" SG_ 2651930736 Digit_10_SGW 0;
BA_ "GenSigTimeoutTime_BSM" SG_ 2651930736 Digit_10_SGW 0;
BA_ "GenSigTimeoutTime_CADM" SG_ 2651930736 Digit_10_SGW 0;
BA_ "GenSigTimeoutTime_DMSM" SG_ 2651930736 Digit_10_SGW 0;
BA_ "GenSigTimeoutTime_DTCM" SG_ 2651930736 Digit_10_SGW 0;
BA_ "GenSigTimeoutTime_ECM" SG_ 2651930736 Digit_10_SGW 0;
BA_ "GenSigTimeoutTime_EVCU2" SG_ 2651930736 Digit_10_SGW 0;
BA_ "GenSigTimeoutTime_GNMM" SG_ 2651930736 Digit_10_SGW 0;
BA_ "GenSigTimeoutTime_HCP" SG_ 2651930736 Digit_10_SGW 0;
BA_ "GenSigTimeoutTime_IPC" SG_ 2651930736 Digit_10_SGW 0;
BA_ "GenSigTimeoutTime_RFHM" SG_ 2651930736 Digit_10_SGW 0;
BA_ "GenSigTimeoutTime_SGW" SG_ 2651930736 Digit_10_SGW 0;
BA_ "GenSigTimeoutTime_TCM" SG_ 2651930736 Digit_10_SGW 0;
BA_ "GenSigTimeoutTime_AGSM" SG_ 2651930736 Digit_11_SGW 0;
BA_ "GenSigTimeoutTime_BSM" SG_ 2651930736 Digit_11_SGW 0;
BA_ "GenSigTimeoutTime_CADM" SG_ 2651930736 Digit_11_SGW 0;
BA_ "GenSigTimeoutTime_DMSM" SG_ 2651930736 Digit_11_SGW 0;
BA_ "GenSigTimeoutTime_DTCM" SG_ 2651930736 Digit_11_SGW 0;
BA_ "GenSigTimeoutTime_ECM" SG_ 2651930736 Digit_11_SGW 0;
BA_ "GenSigTimeoutTime_EVCU2" SG_ 2651930736 Digit_11_SGW 0;
BA_ "GenSigTimeoutTime_GNMM" SG_ 2651930736 Digit_11_SGW 0;
BA_ "GenSigTimeoutTime_HCP" SG_ 2651930736 Digit_11_SGW 0;
BA_ "GenSigTimeoutTime_IPC" SG_ 2651930736 Digit_11_SGW 0;
BA_ "GenSigTimeoutTime_RFHM" SG_ 2651930736 Digit_11_SGW 0;
BA_ "GenSigTimeoutTime_SGW" SG_ 2651930736 Digit_11_SGW 0;
BA_ "GenSigTimeoutTime_TCM" SG_ 2651930736 Digit_11_SGW 0;
BA_ "GenSigSendType" SG_ 2651930659 Digit_01_TBM 1;
BA_ "GenSigTimeoutTime_AGSM" SG_ 2651930659 Digit_01_TBM 0;
BA_ "GenSigTimeoutTime_BSM" SG_ 2651930659 Digit_01_TBM 0;
BA_ "GenSigTimeoutTime_CADM" SG_ 2651930659 Digit_01_TBM 0;
BA_ "GenSigTimeoutTime_DMSM" SG_ 2651930659 Digit_01_TBM 0;
BA_ "GenSigTimeoutTime_DTCM" SG_ 2651930659 Digit_01_TBM 0;
BA_ "GenSigTimeoutTime_ECM" SG_ 2651930659 Digit_01_TBM 0;
BA_ "GenSigTimeoutTime_EVCU2" SG_ 2651930659 Digit_01_TBM 0;
BA_ "GenSigTimeoutTime_GNMM" SG_ 2651930659 Digit_01_TBM 0;
BA_ "GenSigTimeoutTime_HCP" SG_ 2651930659 Digit_01_TBM 0;
BA_ "GenSigTimeoutTime_IPC" SG_ 2651930659 Digit_01_TBM 0;
BA_ "GenSigTimeoutTime_RFHM" SG_ 2651930659 Digit_01_TBM 0;
BA_ "GenSigTimeoutTime_SGW" SG_ 2651930659 Digit_01_TBM 0;
BA_ "GenSigTimeoutTime_TCM" SG_ 2651930659 Digit_01_TBM 0;
BA_ "GenSigTimeoutTime_AGSM" SG_ 2651930659 Digit_02_TBM 0;
BA_ "GenSigTimeoutTime_BSM" SG_ 2651930659 Digit_02_TBM 0;
BA_ "GenSigTimeoutTime_CADM" SG_ 2651930659 Digit_02_TBM 0;
BA_ "GenSigTimeoutTime_DMSM" SG_ 2651930659 Digit_02_TBM 0;
BA_ "GenSigTimeoutTime_DTCM" SG_ 2651930659 Digit_02_TBM 0;
BA_ "GenSigTimeoutTime_ECM" SG_ 2651930659 Digit_02_TBM 0;
BA_ "GenSigTimeoutTime_EVCU2" SG_ 2651930659 Digit_02_TBM 0;
BA_ "GenSigTimeoutTime_GNMM" SG_ 2651930659 Digit_02_TBM 0;
BA_ "GenSigTimeoutTime_HCP" SG_ 2651930659 Digit_02_TBM 0;
BA_ "GenSigTimeoutTime_IPC" SG_ 2651930659 Digit_02_TBM 0;
BA_ "GenSigTimeoutTime_RFHM" SG_ 2651930659 Digit_02_TBM 0;
BA_ "GenSigTimeoutTime_SGW" SG_ 2651930659 Digit_02_TBM 0;
BA_ "GenSigTimeoutTime_TCM" SG_ 2651930659 Digit_02_TBM 0;
BA_ "GenSigTimeoutTime_AGSM" SG_ 2651930659 Digit_03_TBM 0;
BA_ "GenSigTimeoutTime_BSM" SG_ 2651930659 Digit_03_TBM 0;
BA_ "GenSigTimeoutTime_CADM" SG_ 2651930659 Digit_03_TBM 0;
BA_ "GenSigTimeoutTime_DMSM" SG_ 2651930659 Digit_03_TBM 0;
BA_ "GenSigTimeoutTime_DTCM" SG_ 2651930659 Digit_03_TBM 0;
BA_ "GenSigTimeoutTime_ECM" SG_ 2651930659 Digit_03_TBM 0;
BA_ "GenSigTimeoutTime_EVCU2" SG_ 2651930659 Digit_03_TBM 0;
BA_ "GenSigTimeoutTime_GNMM" SG_ 2651930659 Digit_03_TBM 0;
BA_ "GenSigTimeoutTime_HCP" SG_ 2651930659 Digit_03_TBM 0;
BA_ "GenSigTimeoutTime_IPC" SG_ 2651930659 Digit_03_TBM 0;
BA_ "GenSigTimeoutTime_RFHM" SG_ 2651930659 Digit_03_TBM 0;
BA_ "GenSigTimeoutTime_SGW" SG_ 2651930659 Digit_03_TBM 0;
BA_ "GenSigTimeoutTime_TCM" SG_ 2651930659 Digit_03_TBM 0;
BA_ "GenSigTimeoutTime_AGSM" SG_ 2651930659 Digit_04_TBM 0;
BA_ "GenSigTimeoutTime_BSM" SG_ 2651930659 Digit_04_TBM 0;
BA_ "GenSigTimeoutTime_CADM" SG_ 2651930659 Digit_04_TBM 0;
BA_ "GenSigTimeoutTime_DMSM" SG_ 2651930659 Digit_04_TBM 0;
BA_ "GenSigTimeoutTime_DTCM" SG_ 2651930659 Digit_04_TBM 0;
BA_ "GenSigTimeoutTime_ECM" SG_ 2651930659 Digit_04_TBM 0;
BA_ "GenSigTimeoutTime_EVCU2" SG_ 2651930659 Digit_04_TBM 0;
BA_ "GenSigTimeoutTime_GNMM" SG_ 2651930659 Digit_04_TBM 0;
BA_ "GenSigTimeoutTime_HCP" SG_ 2651930659 Digit_04_TBM 0;
BA_ "GenSigTimeoutTime_IPC" SG_ 2651930659 Digit_04_TBM 0;
BA_ "GenSigTimeoutTime_RFHM" SG_ 2651930659 Digit_04_TBM 0;
BA_ "GenSigTimeoutTime_SGW" SG_ 2651930659 Digit_04_TBM 0;
BA_ "GenSigTimeoutTime_TCM" SG_ 2651930659 Digit_04_TBM 0;
BA_ "GenSigTimeoutTime_AGSM" SG_ 2651930659 Digit_05_TBM 0;
BA_ "GenSigTimeoutTime_BSM" SG_ 2651930659 Digit_05_TBM 0;
BA_ "GenSigTimeoutTime_CADM" SG_ 2651930659 Digit_05_TBM 0;
BA_ "GenSigTimeoutTime_DMSM" SG_ 2651930659 Digit_05_TBM 0;
BA_ "GenSigTimeoutTime_DTCM" SG_ 2651930659 Digit_05_TBM 0;
BA_ "GenSigTimeoutTime_ECM" SG_ 2651930659 Digit_05_TBM 0;
BA_ "GenSigTimeoutTime_EVCU2" SG_ 2651930659 Digit_05_TBM 0;
BA_ "GenSigTimeoutTime_GNMM" SG_ 2651930659 Digit_05_TBM 0;
BA_ "GenSigTimeoutTime_HCP" SG_ 2651930659 Digit_05_TBM 0;
BA_ "GenSigTimeoutTime_IPC" SG_ 2651930659 Digit_05_TBM 0;
BA_ "GenSigTimeoutTime_RFHM" SG_ 2651930659 Digit_05_TBM 0;
BA_ "GenSigTimeoutTime_SGW" SG_ 2651930659 Digit_05_TBM 0;
BA_ "GenSigTimeoutTime_TCM" SG_ 2651930659 Digit_05_TBM 0;
BA_ "GenSigTimeoutTime_AGSM" SG_ 2651930659 Digit_06_TBM 0;
BA_ "GenSigTimeoutTime_BSM" SG_ 2651930659 Digit_06_TBM 0;
BA_ "GenSigTimeoutTime_CADM" SG_ 2651930659 Digit_06_TBM 0;
BA_ "GenSigTimeoutTime_DMSM" SG_ 2651930659 Digit_06_TBM 0;
BA_ "GenSigTimeoutTime_DTCM" SG_ 2651930659 Digit_06_TBM 0;
BA_ "GenSigTimeoutTime_ECM" SG_ 2651930659 Digit_06_TBM 0;
BA_ "GenSigTimeoutTime_EVCU2" SG_ 2651930659 Digit_06_TBM 0;
BA_ "GenSigTimeoutTime_GNMM" SG_ 2651930659 Digit_06_TBM 0;
BA_ "GenSigTimeoutTime_HCP" SG_ 2651930659 Digit_06_TBM 0;
BA_ "GenSigTimeoutTime_IPC" SG_ 2651930659 Digit_06_TBM 0;
BA_ "GenSigTimeoutTime_RFHM" SG_ 2651930659 Digit_06_TBM 0;
BA_ "GenSigTimeoutTime_SGW" SG_ 2651930659 Digit_06_TBM 0;
BA_ "GenSigTimeoutTime_TCM" SG_ 2651930659 Digit_06_TBM 0;
BA_ "GenSigTimeoutTime_AGSM" SG_ 2651930659 Digit_07_TBM 0;
BA_ "GenSigTimeoutTime_BSM" SG_ 2651930659 Digit_07_TBM 0;
BA_ "GenSigTimeoutTime_CADM" SG_ 2651930659 Digit_07_TBM 0;
BA_ "GenSigTimeoutTime_DMSM" SG_ 2651930659 Digit_07_TBM 0;
BA_ "GenSigTimeoutTime_DTCM" SG_ 2651930659 Digit_07_TBM 0;
BA_ "GenSigTimeoutTime_ECM" SG_ 2651930659 Digit_07_TBM 0;
BA_ "GenSigTimeoutTime_EVCU2" SG_ 2651930659 Digit_07_TBM 0;
BA_ "GenSigTimeoutTime_GNMM" SG_ 2651930659 Digit_07_TBM 0;
BA_ "GenSigTimeoutTime_HCP" SG_ 2651930659 Digit_07_TBM 0;
BA_ "GenSigTimeoutTime_IPC" SG_ 2651930659 Digit_07_TBM 0;
BA_ "GenSigTimeoutTime_RFHM" SG_ 2651930659 Digit_07_TBM 0;
BA_ "GenSigTimeoutTime_SGW" SG_ 2651930659 Digit_07_TBM 0;
BA_ "GenSigTimeoutTime_TCM" SG_ 2651930659 Digit_07_TBM 0;
BA_ "GenSigTimeoutTime_AGSM" SG_ 2651930659 Digit_08_TBM 0;
BA_ "GenSigTimeoutTime_BSM" SG_ 2651930659 Digit_08_TBM 0;
BA_ "GenSigTimeoutTime_CADM" SG_ 2651930659 Digit_08_TBM 0;
BA_ "GenSigTimeoutTime_DMSM" SG_ 2651930659 Digit_08_TBM 0;
BA_ "GenSigTimeoutTime_DTCM" SG_ 2651930659 Digit_08_TBM 0;
BA_ "GenSigTimeoutTime_ECM" SG_ 2651930659 Digit_08_TBM 0;
BA_ "GenSigTimeoutTime_EVCU2" SG_ 2651930659 Digit_08_TBM 0;
BA_ "GenSigTimeoutTime_GNMM" SG_ 2651930659 Digit_08_TBM 0;
BA_ "GenSigTimeoutTime_HCP" SG_ 2651930659 Digit_08_TBM 0;
BA_ "GenSigTimeoutTime_IPC" SG_ 2651930659 Digit_08_TBM 0;
BA_ "GenSigTimeoutTime_RFHM" SG_ 2651930659 Digit_08_TBM 0;
BA_ "GenSigTimeoutTime_SGW" SG_ 2651930659 Digit_08_TBM 0;
BA_ "GenSigTimeoutTime_TCM" SG_ 2651930659 Digit_08_TBM 0;
BA_ "GenSigTimeoutTime_AGSM" SG_ 2651930659 Digit_09_TBM 0;
BA_ "GenSigTimeoutTime_BSM" SG_ 2651930659 Digit_09_TBM 0;
BA_ "GenSigTimeoutTime_CADM" SG_ 2651930659 Digit_09_TBM 0;
BA_ "GenSigTimeoutTime_DMSM" SG_ 2651930659 Digit_09_TBM 0;
BA_ "GenSigTimeoutTime_DTCM" SG_ 2651930659 Digit_09_TBM 0;
BA_ "GenSigTimeoutTime_ECM" SG_ 2651930659 Digit_09_TBM 0;
BA_ "GenSigTimeoutTime_EVCU2" SG_ 2651930659 Digit_09_TBM 0;
BA_ "GenSigTimeoutTime_GNMM" SG_ 2651930659 Digit_09_TBM 0;
BA_ "GenSigTimeoutTime_HCP" SG_ 2651930659 Digit_09_TBM 0;
BA_ "GenSigTimeoutTime_IPC" SG_ 2651930659 Digit_09_TBM 0;
BA_ "GenSigTimeoutTime_RFHM" SG_ 2651930659 Digit_09_TBM 0;
BA_ "GenSigTimeoutTime_SGW" SG_ 2651930659 Digit_09_TBM 0;
BA_ "GenSigTimeoutTime_TCM" SG_ 2651930659 Digit_09_TBM 0;
BA_ "GenSigTimeoutTime_AGSM" SG_ 2651930659 Digit_10_TBM 0;
BA_ "GenSigTimeoutTime_BSM" SG_ 2651930659 Digit_10_TBM 0;
BA_ "GenSigTimeoutTime_CADM" SG_ 2651930659 Digit_10_TBM 0;
BA_ "GenSigTimeoutTime_DMSM" SG_ 2651930659 Digit_10_TBM 0;
BA_ "GenSigTimeoutTime_DTCM" SG_ 2651930659 Digit_10_TBM 0;
BA_ "GenSigTimeoutTime_ECM" SG_ 2651930659 Digit_10_TBM 0;
BA_ "GenSigTimeoutTime_EVCU2" SG_ 2651930659 Digit_10_TBM 0;
BA_ "GenSigTimeoutTime_GNMM" SG_ 2651930659 Digit_10_TBM 0;
BA_ "GenSigTimeoutTime_HCP" SG_ 2651930659 Digit_10_TBM 0;
BA_ "GenSigTimeoutTime_IPC" SG_ 2651930659 Digit_10_TBM 0;
BA_ "GenSigTimeoutTime_RFHM" SG_ 2651930659 Digit_10_TBM 0;
BA_ "GenSigTimeoutTime_SGW" SG_ 2651930659 Digit_10_TBM 0;
BA_ "GenSigTimeoutTime_TCM" SG_ 2651930659 Digit_10_TBM 0;
BA_ "GenSigTimeoutTime_AGSM" SG_ 2651930659 Digit_11_TBM 0;
BA_ "GenSigTimeoutTime_BSM" SG_ 2651930659 Digit_11_TBM 0;
BA_ "GenSigTimeoutTime_CADM" SG_ 2651930659 Digit_11_TBM 0;
BA_ "GenSigTimeoutTime_DMSM" SG_ 2651930659 Digit_11_TBM 0;
BA_ "GenSigTimeoutTime_DTCM" SG_ 2651930659 Digit_11_TBM 0;
BA_ "GenSigTimeoutTime_ECM" SG_ 2651930659 Digit_11_TBM 0;
BA_ "GenSigTimeoutTime_EVCU2" SG_ 2651930659 Digit_11_TBM 0;
BA_ "GenSigTimeoutTime_GNMM" SG_ 2651930659 Digit_11_TBM 0;
BA_ "GenSigTimeoutTime_HCP" SG_ 2651930659 Digit_11_TBM 0;
BA_ "GenSigTimeoutTime_IPC" SG_ 2651930659 Digit_11_TBM 0;
BA_ "GenSigTimeoutTime_RFHM" SG_ 2651930659 Digit_11_TBM 0;
BA_ "GenSigTimeoutTime_SGW" SG_ 2651930659 Digit_11_TBM 0;
BA_ "GenSigTimeoutTime_TCM" SG_ 2651930659 Digit_11_TBM 0;
BA_ "GenSigSendType" SG_ 2651930635 Digit_01_TCM 1;
BA_ "GenSigTimeoutTime_AGSM" SG_ 2651930635 Digit_01_TCM 0;
BA_ "GenSigTimeoutTime_BSM" SG_ 2651930635 Digit_01_TCM 0;
BA_ "GenSigTimeoutTime_CADM" SG_ 2651930635 Digit_01_TCM 0;
BA_ "GenSigTimeoutTime_DMSM" SG_ 2651930635 Digit_01_TCM 0;
BA_ "GenSigTimeoutTime_DTCM" SG_ 2651930635 Digit_01_TCM 0;
BA_ "GenSigTimeoutTime_ECM" SG_ 2651930635 Digit_01_TCM 0;
BA_ "GenSigTimeoutTime_EVCU2" SG_ 2651930635 Digit_01_TCM 0;
BA_ "GenSigTimeoutTime_GNMM" SG_ 2651930635 Digit_01_TCM 0;
BA_ "GenSigTimeoutTime_HCP" SG_ 2651930635 Digit_01_TCM 0;
BA_ "GenSigTimeoutTime_IPC" SG_ 2651930635 Digit_01_TCM 0;
BA_ "GenSigTimeoutTime_RFHM" SG_ 2651930635 Digit_01_TCM 0;
BA_ "GenSigTimeoutTime_SGW" SG_ 2651930635 Digit_01_TCM 0;
BA_ "GenSigTimeoutTime_TCM" SG_ 2651930635 Digit_01_TCM 0;
BA_ "GenSigTimeoutTime_AGSM" SG_ 2651930635 Digit_02_TCM 0;
BA_ "GenSigTimeoutTime_BSM" SG_ 2651930635 Digit_02_TCM 0;
BA_ "GenSigTimeoutTime_CADM" SG_ 2651930635 Digit_02_TCM 0;
BA_ "GenSigTimeoutTime_DMSM" SG_ 2651930635 Digit_02_TCM 0;
BA_ "GenSigTimeoutTime_DTCM" SG_ 2651930635 Digit_02_TCM 0;
BA_ "GenSigTimeoutTime_ECM" SG_ 2651930635 Digit_02_TCM 0;
BA_ "GenSigTimeoutTime_EVCU2" SG_ 2651930635 Digit_02_TCM 0;
BA_ "GenSigTimeoutTime_GNMM" SG_ 2651930635 Digit_02_TCM 0;
BA_ "GenSigTimeoutTime_HCP" SG_ 2651930635 Digit_02_TCM 0;
BA_ "GenSigTimeoutTime_IPC" SG_ 2651930635 Digit_02_TCM 0;
BA_ "GenSigTimeoutTime_RFHM" SG_ 2651930635 Digit_02_TCM 0;
BA_ "GenSigTimeoutTime_SGW" SG_ 2651930635 Digit_02_TCM 0;
BA_ "GenSigTimeoutTime_TCM" SG_ 2651930635 Digit_02_TCM 0;
BA_ "GenSigTimeoutTime_AGSM" SG_ 2651930635 Digit_03_TCM 0;
BA_ "GenSigTimeoutTime_BSM" SG_ 2651930635 Digit_03_TCM 0;
BA_ "GenSigTimeoutTime_CADM" SG_ 2651930635 Digit_03_TCM 0;
BA_ "GenSigTimeoutTime_DMSM" SG_ 2651930635 Digit_03_TCM 0;
BA_ "GenSigTimeoutTime_DTCM" SG_ 2651930635 Digit_03_TCM 0;
BA_ "GenSigTimeoutTime_ECM" SG_ 2651930635 Digit_03_TCM 0;
BA_ "GenSigTimeoutTime_EVCU2" SG_ 2651930635 Digit_03_TCM 0;
BA_ "GenSigTimeoutTime_GNMM" SG_ 2651930635 Digit_03_TCM 0;
BA_ "GenSigTimeoutTime_HCP" SG_ 2651930635 Digit_03_TCM 0;
BA_ "GenSigTimeoutTime_IPC" SG_ 2651930635 Digit_03_TCM 0;
BA_ "GenSigTimeoutTime_RFHM" SG_ 2651930635 Digit_03_TCM 0;
BA_ "GenSigTimeoutTime_SGW" SG_ 2651930635 Digit_03_TCM 0;
BA_ "GenSigTimeoutTime_TCM" SG_ 2651930635 Digit_03_TCM 0;
BA_ "GenSigTimeoutTime_AGSM" SG_ 2651930635 Digit_04_TCM 0;
BA_ "GenSigTimeoutTime_BSM" SG_ 2651930635 Digit_04_TCM 0;
BA_ "GenSigTimeoutTime_CADM" SG_ 2651930635 Digit_04_TCM 0;
BA_ "GenSigTimeoutTime_DMSM" SG_ 2651930635 Digit_04_TCM 0;
BA_ "GenSigTimeoutTime_DTCM" SG_ 2651930635 Digit_04_TCM 0;
BA_ "GenSigTimeoutTime_ECM" SG_ 2651930635 Digit_04_TCM 0;
BA_ "GenSigTimeoutTime_EVCU2" SG_ 2651930635 Digit_04_TCM 0;
BA_ "GenSigTimeoutTime_GNMM" SG_ 2651930635 Digit_04_TCM 0;
BA_ "GenSigTimeoutTime_HCP" SG_ 2651930635 Digit_04_TCM 0;
BA_ "GenSigTimeoutTime_IPC" SG_ 2651930635 Digit_04_TCM 0;
BA_ "GenSigTimeoutTime_RFHM" SG_ 2651930635 Digit_04_TCM 0;
BA_ "GenSigTimeoutTime_SGW" SG_ 2651930635 Digit_04_TCM 0;
BA_ "GenSigTimeoutTime_TCM" SG_ 2651930635 Digit_04_TCM 0;
BA_ "GenSigTimeoutTime_AGSM" SG_ 2651930635 Digit_05_TCM 0;
BA_ "GenSigTimeoutTime_BSM" SG_ 2651930635 Digit_05_TCM 0;
BA_ "GenSigTimeoutTime_CADM" SG_ 2651930635 Digit_05_TCM 0;
BA_ "GenSigTimeoutTime_DMSM" SG_ 2651930635 Digit_05_TCM 0;
BA_ "GenSigTimeoutTime_DTCM" SG_ 2651930635 Digit_05_TCM 0;
BA_ "GenSigTimeoutTime_ECM" SG_ 2651930635 Digit_05_TCM 0;
BA_ "GenSigTimeoutTime_EVCU2" SG_ 2651930635 Digit_05_TCM 0;
BA_ "GenSigTimeoutTime_GNMM" SG_ 2651930635 Digit_05_TCM 0;
BA_ "GenSigTimeoutTime_HCP" SG_ 2651930635 Digit_05_TCM 0;
BA_ "GenSigTimeoutTime_IPC" SG_ 2651930635 Digit_05_TCM 0;
BA_ "GenSigTimeoutTime_RFHM" SG_ 2651930635 Digit_05_TCM 0;
BA_ "GenSigTimeoutTime_SGW" SG_ 2651930635 Digit_05_TCM 0;
BA_ "GenSigTimeoutTime_TCM" SG_ 2651930635 Digit_05_TCM 0;
BA_ "GenSigTimeoutTime_AGSM" SG_ 2651930635 Digit_06_TCM 0;
BA_ "GenSigTimeoutTime_BSM" SG_ 2651930635 Digit_06_TCM 0;
BA_ "GenSigTimeoutTime_CADM" SG_ 2651930635 Digit_06_TCM 0;
BA_ "GenSigTimeoutTime_DMSM" SG_ 2651930635 Digit_06_TCM 0;
BA_ "GenSigTimeoutTime_DTCM" SG_ 2651930635 Digit_06_TCM 0;
BA_ "GenSigTimeoutTime_ECM" SG_ 2651930635 Digit_06_TCM 0;
BA_ "GenSigTimeoutTime_EVCU2" SG_ 2651930635 Digit_06_TCM 0;
BA_ "GenSigTimeoutTime_GNMM" SG_ 2651930635 Digit_06_TCM 0;
BA_ "GenSigTimeoutTime_HCP" SG_ 2651930635 Digit_06_TCM 0;
BA_ "GenSigTimeoutTime_IPC" SG_ 2651930635 Digit_06_TCM 0;
BA_ "GenSigTimeoutTime_RFHM" SG_ 2651930635 Digit_06_TCM 0;
BA_ "GenSigTimeoutTime_SGW" SG_ 2651930635 Digit_06_TCM 0;
BA_ "GenSigTimeoutTime_TCM" SG_ 2651930635 Digit_06_TCM 0;
BA_ "GenSigTimeoutTime_AGSM" SG_ 2651930635 Digit_07_TCM 0;
BA_ "GenSigTimeoutTime_BSM" SG_ 2651930635 Digit_07_TCM 0;
BA_ "GenSigTimeoutTime_CADM" SG_ 2651930635 Digit_07_TCM 0;
BA_ "GenSigTimeoutTime_DMSM" SG_ 2651930635 Digit_07_TCM 0;
BA_ "GenSigTimeoutTime_DTCM" SG_ 2651930635 Digit_07_TCM 0;
BA_ "GenSigTimeoutTime_ECM" SG_ 2651930635 Digit_07_TCM 0;
BA_ "GenSigTimeoutTime_EVCU2" SG_ 2651930635 Digit_07_TCM 0;
BA_ "GenSigTimeoutTime_GNMM" SG_ 2651930635 Digit_07_TCM 0;
BA_ "GenSigTimeoutTime_HCP" SG_ 2651930635 Digit_07_TCM 0;
BA_ "GenSigTimeoutTime_IPC" SG_ 2651930635 Digit_07_TCM 0;
BA_ "GenSigTimeoutTime_RFHM" SG_ 2651930635 Digit_07_TCM 0;
BA_ "GenSigTimeoutTime_SGW" SG_ 2651930635 Digit_07_TCM 0;
BA_ "GenSigTimeoutTime_TCM" SG_ 2651930635 Digit_07_TCM 0;
BA_ "GenSigTimeoutTime_AGSM" SG_ 2651930635 Digit_08_TCM 0;
BA_ "GenSigTimeoutTime_BSM" SG_ 2651930635 Digit_08_TCM 0;
BA_ "GenSigTimeoutTime_CADM" SG_ 2651930635 Digit_08_TCM 0;
BA_ "GenSigTimeoutTime_DMSM" SG_ 2651930635 Digit_08_TCM 0;
BA_ "GenSigTimeoutTime_DTCM" SG_ 2651930635 Digit_08_TCM 0;
BA_ "GenSigTimeoutTime_ECM" SG_ 2651930635 Digit_08_TCM 0;
BA_ "GenSigTimeoutTime_EVCU2" SG_ 2651930635 Digit_08_TCM 0;
BA_ "GenSigTimeoutTime_GNMM" SG_ 2651930635 Digit_08_TCM 0;
BA_ "GenSigTimeoutTime_HCP" SG_ 2651930635 Digit_08_TCM 0;
BA_ "GenSigTimeoutTime_IPC" SG_ 2651930635 Digit_08_TCM 0;
BA_ "GenSigTimeoutTime_RFHM" SG_ 2651930635 Digit_08_TCM 0;
BA_ "GenSigTimeoutTime_SGW" SG_ 2651930635 Digit_08_TCM 0;
BA_ "GenSigTimeoutTime_TCM" SG_ 2651930635 Digit_08_TCM 0;
BA_ "GenSigTimeoutTime_AGSM" SG_ 2651930635 Digit_09_TCM 0;
BA_ "GenSigTimeoutTime_BSM" SG_ 2651930635 Digit_09_TCM 0;
BA_ "GenSigTimeoutTime_CADM" SG_ 2651930635 Digit_09_TCM 0;
BA_ "GenSigTimeoutTime_DMSM" SG_ 2651930635 Digit_09_TCM 0;
BA_ "GenSigTimeoutTime_DTCM" SG_ 2651930635 Digit_09_TCM 0;
BA_ "GenSigTimeoutTime_ECM" SG_ 2651930635 Digit_09_TCM 0;
BA_ "GenSigTimeoutTime_EVCU2" SG_ 2651930635 Digit_09_TCM 0;
BA_ "GenSigTimeoutTime_GNMM" SG_ 2651930635 Digit_09_TCM 0;
BA_ "GenSigTimeoutTime_HCP" SG_ 2651930635 Digit_09_TCM 0;
BA_ "GenSigTimeoutTime_IPC" SG_ 2651930635 Digit_09_TCM 0;
BA_ "GenSigTimeoutTime_RFHM" SG_ 2651930635 Digit_09_TCM 0;
BA_ "GenSigTimeoutTime_SGW" SG_ 2651930635 Digit_09_TCM 0;
BA_ "GenSigTimeoutTime_TCM" SG_ 2651930635 Digit_09_TCM 0;
BA_ "GenSigTimeoutTime_AGSM" SG_ 2651930635 Digit_10_TCM 0;
BA_ "GenSigTimeoutTime_BSM" SG_ 2651930635 Digit_10_TCM 0;
BA_ "GenSigTimeoutTime_CADM" SG_ 2651930635 Digit_10_TCM 0;
BA_ "GenSigTimeoutTime_DMSM" SG_ 2651930635 Digit_10_TCM 0;
BA_ "GenSigTimeoutTime_DTCM" SG_ 2651930635 Digit_10_TCM 0;
BA_ "GenSigTimeoutTime_ECM" SG_ 2651930635 Digit_10_TCM 0;
BA_ "GenSigTimeoutTime_EVCU2" SG_ 2651930635 Digit_10_TCM 0;
BA_ "GenSigTimeoutTime_GNMM" SG_ 2651930635 Digit_10_TCM 0;
BA_ "GenSigTimeoutTime_HCP" SG_ 2651930635 Digit_10_TCM 0;
BA_ "GenSigTimeoutTime_IPC" SG_ 2651930635 Digit_10_TCM 0;
BA_ "GenSigTimeoutTime_RFHM" SG_ 2651930635 Digit_10_TCM 0;
BA_ "GenSigTimeoutTime_SGW" SG_ 2651930635 Digit_10_TCM 0;
BA_ "GenSigTimeoutTime_TCM" SG_ 2651930635 Digit_10_TCM 0;
BA_ "GenSigTimeoutTime_AGSM" SG_ 2651930635 Digit_11_TCM 0;
BA_ "GenSigTimeoutTime_BSM" SG_ 2651930635 Digit_11_TCM 0;
BA_ "GenSigTimeoutTime_CADM" SG_ 2651930635 Digit_11_TCM 0;
BA_ "GenSigTimeoutTime_DMSM" SG_ 2651930635 Digit_11_TCM 0;
BA_ "GenSigTimeoutTime_DTCM" SG_ 2651930635 Digit_11_TCM 0;
BA_ "GenSigTimeoutTime_ECM" SG_ 2651930635 Digit_11_TCM 0;
BA_ "GenSigTimeoutTime_EVCU2" SG_ 2651930635 Digit_11_TCM 0;
BA_ "GenSigTimeoutTime_GNMM" SG_ 2651930635 Digit_11_TCM 0;
BA_ "GenSigTimeoutTime_HCP" SG_ 2651930635 Digit_11_TCM 0;
BA_ "GenSigTimeoutTime_IPC" SG_ 2651930635 Digit_11_TCM 0;
BA_ "GenSigTimeoutTime_RFHM" SG_ 2651930635 Digit_11_TCM 0;
BA_ "GenSigTimeoutTime_SGW" SG_ 2651930635 Digit_11_TCM 0;
BA_ "GenSigTimeoutTime_TCM" SG_ 2651930635 Digit_11_TCM 0;
BA_ "GenSigSendType" SG_ 2651930751 Digit_01_VRM 1;
BA_ "GenSigTimeoutTime_AGSM" SG_ 2651930751 Digit_01_VRM 0;
BA_ "GenSigTimeoutTime_BSM" SG_ 2651930751 Digit_01_VRM 0;
BA_ "GenSigTimeoutTime_CADM" SG_ 2651930751 Digit_01_VRM 0;
BA_ "GenSigTimeoutTime_DMSM" SG_ 2651930751 Digit_01_VRM 0;
BA_ "GenSigTimeoutTime_DTCM" SG_ 2651930751 Digit_01_VRM 0;
BA_ "GenSigTimeoutTime_ECM" SG_ 2651930751 Digit_01_VRM 0;
BA_ "GenSigTimeoutTime_EVCU2" SG_ 2651930751 Digit_01_VRM 0;
BA_ "GenSigTimeoutTime_GNMM" SG_ 2651930751 Digit_01_VRM 0;
BA_ "GenSigTimeoutTime_HCP" SG_ 2651930751 Digit_01_VRM 0;
BA_ "GenSigTimeoutTime_IPC" SG_ 2651930751 Digit_01_VRM 0;
BA_ "GenSigTimeoutTime_RFHM" SG_ 2651930751 Digit_01_VRM 0;
BA_ "GenSigTimeoutTime_SGW" SG_ 2651930751 Digit_01_VRM 0;
BA_ "GenSigTimeoutTime_TCM" SG_ 2651930751 Digit_01_VRM 0;
BA_ "GenSigTimeoutTime_AGSM" SG_ 2651930751 Digit_02_VRM 0;
BA_ "GenSigTimeoutTime_BSM" SG_ 2651930751 Digit_02_VRM 0;
BA_ "GenSigTimeoutTime_CADM" SG_ 2651930751 Digit_02_VRM 0;
BA_ "GenSigTimeoutTime_DMSM" SG_ 2651930751 Digit_02_VRM 0;
BA_ "GenSigTimeoutTime_DTCM" SG_ 2651930751 Digit_02_VRM 0;
BA_ "GenSigTimeoutTime_ECM" SG_ 2651930751 Digit_02_VRM 0;
BA_ "GenSigTimeoutTime_EVCU2" SG_ 2651930751 Digit_02_VRM 0;
BA_ "GenSigTimeoutTime_GNMM" SG_ 2651930751 Digit_02_VRM 0;
BA_ "GenSigTimeoutTime_HCP" SG_ 2651930751 Digit_02_VRM 0;
BA_ "GenSigTimeoutTime_IPC" SG_ 2651930751 Digit_02_VRM 0;
BA_ "GenSigTimeoutTime_RFHM" SG_ 2651930751 Digit_02_VRM 0;
BA_ "GenSigTimeoutTime_SGW" SG_ 2651930751 Digit_02_VRM 0;
BA_ "GenSigTimeoutTime_TCM" SG_ 2651930751 Digit_02_VRM 0;
BA_ "GenSigTimeoutTime_AGSM" SG_ 2651930751 Digit_03_VRM 0;
BA_ "GenSigTimeoutTime_BSM" SG_ 2651930751 Digit_03_VRM 0;
BA_ "GenSigTimeoutTime_CADM" SG_ 2651930751 Digit_03_VRM 0;
BA_ "GenSigTimeoutTime_DMSM" SG_ 2651930751 Digit_03_VRM 0;
BA_ "GenSigTimeoutTime_DTCM" SG_ 2651930751 Digit_03_VRM 0;
BA_ "GenSigTimeoutTime_ECM" SG_ 2651930751 Digit_03_VRM 0;
BA_ "GenSigTimeoutTime_EVCU2" SG_ 2651930751 Digit_03_VRM 0;
BA_ "GenSigTimeoutTime_GNMM" SG_ 2651930751 Digit_03_VRM 0;
BA_ "GenSigTimeoutTime_HCP" SG_ 2651930751 Digit_03_VRM 0;
BA_ "GenSigTimeoutTime_IPC" SG_ 2651930751 Digit_03_VRM 0;
BA_ "GenSigTimeoutTime_RFHM" SG_ 2651930751 Digit_03_VRM 0;
BA_ "GenSigTimeoutTime_SGW" SG_ 2651930751 Digit_03_VRM 0;
BA_ "GenSigTimeoutTime_TCM" SG_ 2651930751 Digit_03_VRM 0;
BA_ "GenSigTimeoutTime_AGSM" SG_ 2651930751 Digit_04_VRM 0;
BA_ "GenSigTimeoutTime_BSM" SG_ 2651930751 Digit_04_VRM 0;
BA_ "GenSigTimeoutTime_CADM" SG_ 2651930751 Digit_04_VRM 0;
BA_ "GenSigTimeoutTime_DMSM" SG_ 2651930751 Digit_04_VRM 0;
BA_ "GenSigTimeoutTime_DTCM" SG_ 2651930751 Digit_04_VRM 0;
BA_ "GenSigTimeoutTime_ECM" SG_ 2651930751 Digit_04_VRM 0;
BA_ "GenSigTimeoutTime_EVCU2" SG_ 2651930751 Digit_04_VRM 0;
BA_ "GenSigTimeoutTime_GNMM" SG_ 2651930751 Digit_04_VRM 0;
BA_ "GenSigTimeoutTime_HCP" SG_ 2651930751 Digit_04_VRM 0;
BA_ "GenSigTimeoutTime_IPC" SG_ 2651930751 Digit_04_VRM 0;
BA_ "GenSigTimeoutTime_RFHM" SG_ 2651930751 Digit_04_VRM 0;
BA_ "GenSigTimeoutTime_SGW" SG_ 2651930751 Digit_04_VRM 0;
BA_ "GenSigTimeoutTime_TCM" SG_ 2651930751 Digit_04_VRM 0;
BA_ "GenSigTimeoutTime_AGSM" SG_ 2651930751 Digit_05_VRM 0;
BA_ "GenSigTimeoutTime_BSM" SG_ 2651930751 Digit_05_VRM 0;
BA_ "GenSigTimeoutTime_CADM" SG_ 2651930751 Digit_05_VRM 0;
BA_ "GenSigTimeoutTime_DMSM" SG_ 2651930751 Digit_05_VRM 0;
BA_ "GenSigTimeoutTime_DTCM" SG_ 2651930751 Digit_05_VRM 0;
BA_ "GenSigTimeoutTime_ECM" SG_ 2651930751 Digit_05_VRM 0;
BA_ "GenSigTimeoutTime_EVCU2" SG_ 2651930751 Digit_05_VRM 0;
BA_ "GenSigTimeoutTime_GNMM" SG_ 2651930751 Digit_05_VRM 0;
BA_ "GenSigTimeoutTime_HCP" SG_ 2651930751 Digit_05_VRM 0;
BA_ "GenSigTimeoutTime_IPC" SG_ 2651930751 Digit_05_VRM 0;
BA_ "GenSigTimeoutTime_RFHM" SG_ 2651930751 Digit_05_VRM 0;
BA_ "GenSigTimeoutTime_SGW" SG_ 2651930751 Digit_05_VRM 0;
BA_ "GenSigTimeoutTime_TCM" SG_ 2651930751 Digit_05_VRM 0;
BA_ "GenSigTimeoutTime_AGSM" SG_ 2651930751 Digit_06_VRM 0;
BA_ "GenSigTimeoutTime_BSM" SG_ 2651930751 Digit_06_VRM 0;
BA_ "GenSigTimeoutTime_CADM" SG_ 2651930751 Digit_06_VRM 0;
BA_ "GenSigTimeoutTime_DMSM" SG_ 2651930751 Digit_06_VRM 0;
BA_ "GenSigTimeoutTime_DTCM" SG_ 2651930751 Digit_06_VRM 0;
BA_ "GenSigTimeoutTime_ECM" SG_ 2651930751 Digit_06_VRM 0;
BA_ "GenSigTimeoutTime_EVCU2" SG_ 2651930751 Digit_06_VRM 0;
BA_ "GenSigTimeoutTime_GNMM" SG_ 2651930751 Digit_06_VRM 0;
BA_ "GenSigTimeoutTime_HCP" SG_ 2651930751 Digit_06_VRM 0;
BA_ "GenSigTimeoutTime_IPC" SG_ 2651930751 Digit_06_VRM 0;
BA_ "GenSigTimeoutTime_RFHM" SG_ 2651930751 Digit_06_VRM 0;
BA_ "GenSigTimeoutTime_SGW" SG_ 2651930751 Digit_06_VRM 0;
BA_ "GenSigTimeoutTime_TCM" SG_ 2651930751 Digit_06_VRM 0;
BA_ "GenSigTimeoutTime_AGSM" SG_ 2651930751 Digit_07_VRM 0;
BA_ "GenSigTimeoutTime_BSM" SG_ 2651930751 Digit_07_VRM 0;
BA_ "GenSigTimeoutTime_CADM" SG_ 2651930751 Digit_07_VRM 0;
BA_ "GenSigTimeoutTime_DMSM" SG_ 2651930751 Digit_07_VRM 0;
BA_ "GenSigTimeoutTime_DTCM" SG_ 2651930751 Digit_07_VRM 0;
BA_ "GenSigTimeoutTime_ECM" SG_ 2651930751 Digit_07_VRM 0;
BA_ "GenSigTimeoutTime_EVCU2" SG_ 2651930751 Digit_07_VRM 0;
BA_ "GenSigTimeoutTime_GNMM" SG_ 2651930751 Digit_07_VRM 0;
BA_ "GenSigTimeoutTime_HCP" SG_ 2651930751 Digit_07_VRM 0;
BA_ "GenSigTimeoutTime_IPC" SG_ 2651930751 Digit_07_VRM 0;
BA_ "GenSigTimeoutTime_RFHM" SG_ 2651930751 Digit_07_VRM 0;
BA_ "GenSigTimeoutTime_SGW" SG_ 2651930751 Digit_07_VRM 0;
BA_ "GenSigTimeoutTime_TCM" SG_ 2651930751 Digit_07_VRM 0;
BA_ "GenSigTimeoutTime_AGSM" SG_ 2651930751 Digit_08_VRM 0;
BA_ "GenSigTimeoutTime_BSM" SG_ 2651930751 Digit_08_VRM 0;
BA_ "GenSigTimeoutTime_CADM" SG_ 2651930751 Digit_08_VRM 0;
BA_ "GenSigTimeoutTime_DMSM" SG_ 2651930751 Digit_08_VRM 0;
BA_ "GenSigTimeoutTime_DTCM" SG_ 2651930751 Digit_08_VRM 0;
BA_ "GenSigTimeoutTime_ECM" SG_ 2651930751 Digit_08_VRM 0;
BA_ "GenSigTimeoutTime_EVCU2" SG_ 2651930751 Digit_08_VRM 0;
BA_ "GenSigTimeoutTime_GNMM" SG_ 2651930751 Digit_08_VRM 0;
BA_ "GenSigTimeoutTime_HCP" SG_ 2651930751 Digit_08_VRM 0;
BA_ "GenSigTimeoutTime_IPC" SG_ 2651930751 Digit_08_VRM 0;
BA_ "GenSigTimeoutTime_RFHM" SG_ 2651930751 Digit_08_VRM 0;
BA_ "GenSigTimeoutTime_SGW" SG_ 2651930751 Digit_08_VRM 0;
BA_ "GenSigTimeoutTime_TCM" SG_ 2651930751 Digit_08_VRM 0;
BA_ "GenSigTimeoutTime_AGSM" SG_ 2651930751 Digit_09_VRM 0;
BA_ "GenSigTimeoutTime_BSM" SG_ 2651930751 Digit_09_VRM 0;
BA_ "GenSigTimeoutTime_CADM" SG_ 2651930751 Digit_09_VRM 0;
BA_ "GenSigTimeoutTime_DMSM" SG_ 2651930751 Digit_09_VRM 0;
BA_ "GenSigTimeoutTime_DTCM" SG_ 2651930751 Digit_09_VRM 0;
BA_ "GenSigTimeoutTime_ECM" SG_ 2651930751 Digit_09_VRM 0;
BA_ "GenSigTimeoutTime_EVCU2" SG_ 2651930751 Digit_09_VRM 0;
BA_ "GenSigTimeoutTime_GNMM" SG_ 2651930751 Digit_09_VRM 0;
BA_ "GenSigTimeoutTime_HCP" SG_ 2651930751 Digit_09_VRM 0;
BA_ "GenSigTimeoutTime_IPC" SG_ 2651930751 Digit_09_VRM 0;
BA_ "GenSigTimeoutTime_RFHM" SG_ 2651930751 Digit_09_VRM 0;
BA_ "GenSigTimeoutTime_SGW" SG_ 2651930751 Digit_09_VRM 0;
BA_ "GenSigTimeoutTime_TCM" SG_ 2651930751 Digit_09_VRM 0;
BA_ "GenSigTimeoutTime_AGSM" SG_ 2651930751 Digit_10_VRM 0;
BA_ "GenSigTimeoutTime_BSM" SG_ 2651930751 Digit_10_VRM 0;
BA_ "GenSigTimeoutTime_CADM" SG_ 2651930751 Digit_10_VRM 0;
BA_ "GenSigTimeoutTime_DMSM" SG_ 2651930751 Digit_10_VRM 0;
BA_ "GenSigTimeoutTime_DTCM" SG_ 2651930751 Digit_10_VRM 0;
BA_ "GenSigTimeoutTime_ECM" SG_ 2651930751 Digit_10_VRM 0;
BA_ "GenSigTimeoutTime_EVCU2" SG_ 2651930751 Digit_10_VRM 0;
BA_ "GenSigTimeoutTime_GNMM" SG_ 2651930751 Digit_10_VRM 0;
BA_ "GenSigTimeoutTime_HCP" SG_ 2651930751 Digit_10_VRM 0;
BA_ "GenSigTimeoutTime_IPC" SG_ 2651930751 Digit_10_VRM 0;
BA_ "GenSigTimeoutTime_RFHM" SG_ 2651930751 Digit_10_VRM 0;
BA_ "GenSigTimeoutTime_SGW" SG_ 2651930751 Digit_10_VRM 0;
BA_ "GenSigTimeoutTime_TCM" SG_ 2651930751 Digit_10_VRM 0;
BA_ "GenSigTimeoutTime_AGSM" SG_ 2651930751 Digit_11_VRM 0;
BA_ "GenSigTimeoutTime_BSM" SG_ 2651930751 Digit_11_VRM 0;
BA_ "GenSigTimeoutTime_CADM" SG_ 2651930751 Digit_11_VRM 0;
BA_ "GenSigTimeoutTime_DMSM" SG_ 2651930751 Digit_11_VRM 0;
BA_ "GenSigTimeoutTime_DTCM" SG_ 2651930751 Digit_11_VRM 0;
BA_ "GenSigTimeoutTime_ECM" SG_ 2651930751 Digit_11_VRM 0;
BA_ "GenSigTimeoutTime_EVCU2" SG_ 2651930751 Digit_11_VRM 0;
BA_ "GenSigTimeoutTime_GNMM" SG_ 2651930751 Digit_11_VRM 0;
BA_ "GenSigTimeoutTime_HCP" SG_ 2651930751 Digit_11_VRM 0;
BA_ "GenSigTimeoutTime_IPC" SG_ 2651930751 Digit_11_VRM 0;
BA_ "GenSigTimeoutTime_RFHM" SG_ 2651930751 Digit_11_VRM 0;
BA_ "GenSigTimeoutTime_SGW" SG_ 2651930751 Digit_11_VRM 0;
BA_ "GenSigTimeoutTime_TCM" SG_ 2651930751 Digit_11_VRM 0;
BA_ "GenSigSendType" SG_ 1457 Charge_Schedule_Type1_Sts 3;
BA_ "GenSigTimeoutTime_AGSM" SG_ 1457 Charge_Schedule_Type1_Sts 0;
BA_ "GenSigTimeoutTime_BCM" SG_ 1457 Charge_Schedule_Type1_Sts 0;
BA_ "GenSigTimeoutTime_BSM" SG_ 1457 Charge_Schedule_Type1_Sts 0;
BA_ "GenSigTimeoutTime_CADM" SG_ 1457 Charge_Schedule_Type1_Sts 0;
BA_ "GenSigTimeoutTime_DMSM" SG_ 1457 Charge_Schedule_Type1_Sts 0;
BA_ "GenSigTimeoutTime_DTCM" SG_ 1457 Charge_Schedule_Type1_Sts 0;
BA_ "GenSigTimeoutTime_ECM" SG_ 1457 Charge_Schedule_Type1_Sts 0;
BA_ "GenSigTimeoutTime_EVCU2" SG_ 1457 Charge_Schedule_Type1_Sts 0;
BA_ "GenSigTimeoutTime_GNMM" SG_ 1457 Charge_Schedule_Type1_Sts 0;
BA_ "GenSigTimeoutTime_HCP" SG_ 1457 Charge_Schedule_Type1_Sts 0;
BA_ "GenSigTimeoutTime_IPC" SG_ 1457 Charge_Schedule_Type1_Sts 0;
BA_ "GenSigTimeoutTime_RFHM" SG_ 1457 Charge_Schedule_Type1_Sts 0;
BA_ "GenSigTimeoutTime_TCM" SG_ 1457 Charge_Schedule_Type1_Sts 0;
BA_ "GenSigSendType" SG_ 1457 Charge_Schedule_Type2_Sts 3;
BA_ "GenSigTimeoutTime_AGSM" SG_ 1457 Charge_Schedule_Type2_Sts 0;
BA_ "GenSigTimeoutTime_BCM" SG_ 1457 Charge_Schedule_Type2_Sts 0;
BA_ "GenSigTimeoutTime_BSM" SG_ 1457 Charge_Schedule_Type2_Sts 0;
BA_ "GenSigTimeoutTime_CADM" SG_ 1457 Charge_Schedule_Type2_Sts 0;
BA_ "GenSigTimeoutTime_DMSM" SG_ 1457 Charge_Schedule_Type2_Sts 0;
BA_ "GenSigTimeoutTime_DTCM" SG_ 1457 Charge_Schedule_Type2_Sts 0;
BA_ "GenSigTimeoutTime_ECM" SG_ 1457 Charge_Schedule_Type2_Sts 0;
BA_ "GenSigTimeoutTime_EVCU2" SG_ 1457 Charge_Schedule_Type2_Sts 0;
BA_ "GenSigTimeoutTime_GNMM" SG_ 1457 Charge_Schedule_Type2_Sts 0;
BA_ "GenSigTimeoutTime_HCP" SG_ 1457 Charge_Schedule_Type2_Sts 0;
BA_ "GenSigTimeoutTime_IPC" SG_ 1457 Charge_Schedule_Type2_Sts 0;
BA_ "GenSigTimeoutTime_RFHM" SG_ 1457 Charge_Schedule_Type2_Sts 0;
BA_ "GenSigTimeoutTime_TCM" SG_ 1457 Charge_Schedule_Type2_Sts 0;
BA_ "GenSigSendType" SG_ 1457 ChargeUntilFull1_Sts 3;
BA_ "GenSigTimeoutTime_AGSM" SG_ 1457 ChargeUntilFull1_Sts 0;
BA_ "GenSigTimeoutTime_BCM" SG_ 1457 ChargeUntilFull1_Sts 0;
BA_ "GenSigTimeoutTime_BSM" SG_ 1457 ChargeUntilFull1_Sts 0;
BA_ "GenSigTimeoutTime_CADM" SG_ 1457 ChargeUntilFull1_Sts 0;
BA_ "GenSigTimeoutTime_DMSM" SG_ 1457 ChargeUntilFull1_Sts 0;
BA_ "GenSigTimeoutTime_DTCM" SG_ 1457 ChargeUntilFull1_Sts 0;
BA_ "GenSigTimeoutTime_ECM" SG_ 1457 ChargeUntilFull1_Sts 0;
BA_ "GenSigTimeoutTime_EVCU2" SG_ 1457 ChargeUntilFull1_Sts 0;
BA_ "GenSigTimeoutTime_GNMM" SG_ 1457 ChargeUntilFull1_Sts 0;
BA_ "GenSigTimeoutTime_HCP" SG_ 1457 ChargeUntilFull1_Sts 0;
BA_ "GenSigTimeoutTime_IPC" SG_ 1457 ChargeUntilFull1_Sts 0;
BA_ "GenSigTimeoutTime_RFHM" SG_ 1457 ChargeUntilFull1_Sts 0;
BA_ "GenSigTimeoutTime_TCM" SG_ 1457 ChargeUntilFull1_Sts 0;
BA_ "GenSigSendType" SG_ 1457 ChargeUntilFull2_Sts 3;
BA_ "GenSigTimeoutTime_AGSM" SG_ 1457 ChargeUntilFull2_Sts 0;
BA_ "GenSigTimeoutTime_BCM" SG_ 1457 ChargeUntilFull2_Sts 0;
BA_ "GenSigTimeoutTime_BSM" SG_ 1457 ChargeUntilFull2_Sts 0;
BA_ "GenSigTimeoutTime_CADM" SG_ 1457 ChargeUntilFull2_Sts 0;
BA_ "GenSigTimeoutTime_DMSM" SG_ 1457 ChargeUntilFull2_Sts 0;
BA_ "GenSigTimeoutTime_DTCM" SG_ 1457 ChargeUntilFull2_Sts 0;
BA_ "GenSigTimeoutTime_ECM" SG_ 1457 ChargeUntilFull2_Sts 0;
BA_ "GenSigTimeoutTime_EVCU2" SG_ 1457 ChargeUntilFull2_Sts 0;
BA_ "GenSigTimeoutTime_GNMM" SG_ 1457 ChargeUntilFull2_Sts 0;
BA_ "GenSigTimeoutTime_HCP" SG_ 1457 ChargeUntilFull2_Sts 0;
BA_ "GenSigTimeoutTime_IPC" SG_ 1457 ChargeUntilFull2_Sts 0;
BA_ "GenSigTimeoutTime_RFHM" SG_ 1457 ChargeUntilFull2_Sts 0;
BA_ "GenSigTimeoutTime_TCM" SG_ 1457 ChargeUntilFull2_Sts 0;
BA_ "GenSigSendType" SG_ 1457 End_Time_Hr1_Sts 3;
BA_ "GenSigTimeoutTime_AGSM" SG_ 1457 End_Time_Hr1_Sts 0;
BA_ "GenSigTimeoutTime_BCM" SG_ 1457 End_Time_Hr1_Sts 0;
BA_ "GenSigTimeoutTime_BSM" SG_ 1457 End_Time_Hr1_Sts 0;
BA_ "GenSigTimeoutTime_CADM" SG_ 1457 End_Time_Hr1_Sts 0;
BA_ "GenSigTimeoutTime_DMSM" SG_ 1457 End_Time_Hr1_Sts 0;
BA_ "GenSigTimeoutTime_DTCM" SG_ 1457 End_Time_Hr1_Sts 0;
BA_ "GenSigTimeoutTime_ECM" SG_ 1457 End_Time_Hr1_Sts 0;
BA_ "GenSigTimeoutTime_EVCU2" SG_ 1457 End_Time_Hr1_Sts 0;
BA_ "GenSigTimeoutTime_GNMM" SG_ 1457 End_Time_Hr1_Sts 0;
BA_ "GenSigTimeoutTime_HCP" SG_ 1457 End_Time_Hr1_Sts 0;
BA_ "GenSigTimeoutTime_IPC" SG_ 1457 End_Time_Hr1_Sts 0;
BA_ "GenSigTimeoutTime_RFHM" SG_ 1457 End_Time_Hr1_Sts 0;
BA_ "GenSigTimeoutTime_TCM" SG_ 1457 End_Time_Hr1_Sts 0;
BA_ "GenSigSendType" SG_ 1457 End_Time_Hr2_Sts 3;
BA_ "GenSigTimeoutTime_AGSM" SG_ 1457 End_Time_Hr2_Sts 0;
BA_ "GenSigTimeoutTime_BCM" SG_ 1457 End_Time_Hr2_Sts 0;
BA_ "GenSigTimeoutTime_BSM" SG_ 1457 End_Time_Hr2_Sts 0;
BA_ "GenSigTimeoutTime_CADM" SG_ 1457 End_Time_Hr2_Sts 0;
BA_ "GenSigTimeoutTime_DMSM" SG_ 1457 End_Time_Hr2_Sts 0;
BA_ "GenSigTimeoutTime_DTCM" SG_ 1457 End_Time_Hr2_Sts 0;
BA_ "GenSigTimeoutTime_ECM" SG_ 1457 End_Time_Hr2_Sts 0;
BA_ "GenSigTimeoutTime_EVCU2" SG_ 1457 End_Time_Hr2_Sts 0;
BA_ "GenSigTimeoutTime_GNMM" SG_ 1457 End_Time_Hr2_Sts 0;
BA_ "GenSigTimeoutTime_HCP" SG_ 1457 End_Time_Hr2_Sts 0;
BA_ "GenSigTimeoutTime_IPC" SG_ 1457 End_Time_Hr2_Sts 0;
BA_ "GenSigTimeoutTime_RFHM" SG_ 1457 End_Time_Hr2_Sts 0;
BA_ "GenSigTimeoutTime_TCM" SG_ 1457 End_Time_Hr2_Sts 0;
BA_ "GenSigSendType" SG_ 1457 End_Time_Min1_Sts 3;
BA_ "GenSigTimeoutTime_AGSM" SG_ 1457 End_Time_Min1_Sts 0;
BA_ "GenSigTimeoutTime_BCM" SG_ 1457 End_Time_Min1_Sts 0;
BA_ "GenSigTimeoutTime_BSM" SG_ 1457 End_Time_Min1_Sts 0;
BA_ "GenSigTimeoutTime_CADM" SG_ 1457 End_Time_Min1_Sts 0;
BA_ "GenSigTimeoutTime_DMSM" SG_ 1457 End_Time_Min1_Sts 0;
BA_ "GenSigTimeoutTime_DTCM" SG_ 1457 End_Time_Min1_Sts 0;
BA_ "GenSigTimeoutTime_ECM" SG_ 1457 End_Time_Min1_Sts 0;
BA_ "GenSigTimeoutTime_EVCU2" SG_ 1457 End_Time_Min1_Sts 0;
BA_ "GenSigTimeoutTime_GNMM" SG_ 1457 End_Time_Min1_Sts 0;
BA_ "GenSigTimeoutTime_HCP" SG_ 1457 End_Time_Min1_Sts 0;
BA_ "GenSigTimeoutTime_IPC" SG_ 1457 End_Time_Min1_Sts 0;
BA_ "GenSigTimeoutTime_RFHM" SG_ 1457 End_Time_Min1_Sts 0;
BA_ "GenSigTimeoutTime_TCM" SG_ 1457 End_Time_Min1_Sts 0;
BA_ "GenSigSendType" SG_ 1457 End_Time_Min2_Sts 3;
BA_ "GenSigTimeoutTime_AGSM" SG_ 1457 End_Time_Min2_Sts 0;
BA_ "GenSigTimeoutTime_BCM" SG_ 1457 End_Time_Min2_Sts 0;
BA_ "GenSigTimeoutTime_BSM" SG_ 1457 End_Time_Min2_Sts 0;
BA_ "GenSigTimeoutTime_CADM" SG_ 1457 End_Time_Min2_Sts 0;
BA_ "GenSigTimeoutTime_DMSM" SG_ 1457 End_Time_Min2_Sts 0;
BA_ "GenSigTimeoutTime_DTCM" SG_ 1457 End_Time_Min2_Sts 0;
BA_ "GenSigTimeoutTime_ECM" SG_ 1457 End_Time_Min2_Sts 0;
BA_ "GenSigTimeoutTime_EVCU2" SG_ 1457 End_Time_Min2_Sts 0;
BA_ "GenSigTimeoutTime_GNMM" SG_ 1457 End_Time_Min2_Sts 0;
BA_ "GenSigTimeoutTime_HCP" SG_ 1457 End_Time_Min2_Sts 0;
BA_ "GenSigTimeoutTime_IPC" SG_ 1457 End_Time_Min2_Sts 0;
BA_ "GenSigTimeoutTime_RFHM" SG_ 1457 End_Time_Min2_Sts 0;
BA_ "GenSigTimeoutTime_TCM" SG_ 1457 End_Time_Min2_Sts 0;
BA_ "GenSigSendType" SG_ 1457 External_ChargeTarget1_Sts 3;
BA_ "GenSigTimeoutTime_AGSM" SG_ 1457 External_ChargeTarget1_Sts 0;
BA_ "GenSigTimeoutTime_BCM" SG_ 1457 External_ChargeTarget1_Sts 0;
BA_ "GenSigTimeoutTime_BSM" SG_ 1457 External_ChargeTarget1_Sts 0;
BA_ "GenSigTimeoutTime_CADM" SG_ 1457 External_ChargeTarget1_Sts 0;
BA_ "GenSigTimeoutTime_DMSM" SG_ 1457 External_ChargeTarget1_Sts 0;
BA_ "GenSigTimeoutTime_DTCM" SG_ 1457 External_ChargeTarget1_Sts 0;
BA_ "GenSigTimeoutTime_ECM" SG_ 1457 External_ChargeTarget1_Sts 0;
BA_ "GenSigTimeoutTime_EVCU2" SG_ 1457 External_ChargeTarget1_Sts 0;
BA_ "GenSigTimeoutTime_GNMM" SG_ 1457 External_ChargeTarget1_Sts 0;
BA_ "GenSigTimeoutTime_HCP" SG_ 1457 External_ChargeTarget1_Sts 0;
BA_ "GenSigTimeoutTime_IPC" SG_ 1457 External_ChargeTarget1_Sts 0;
BA_ "GenSigTimeoutTime_RFHM" SG_ 1457 External_ChargeTarget1_Sts 0;
BA_ "GenSigTimeoutTime_TCM" SG_ 1457 External_ChargeTarget1_Sts 0;
BA_ "GenSigStartValue" SG_ 1457 External_ChargeTarget2_Sts 15;
BA_ "GenSigSendType" SG_ 1457 External_ChargeTarget2_Sts 3;
BA_ "GenSigTimeoutTime_AGSM" SG_ 1457 External_ChargeTarget2_Sts 0;
BA_ "GenSigTimeoutTime_BCM" SG_ 1457 External_ChargeTarget2_Sts 0;
BA_ "GenSigTimeoutTime_BSM" SG_ 1457 External_ChargeTarget2_Sts 0;
BA_ "GenSigTimeoutTime_CADM" SG_ 1457 External_ChargeTarget2_Sts 0;
BA_ "GenSigTimeoutTime_DMSM" SG_ 1457 External_ChargeTarget2_Sts 0;
BA_ "GenSigTimeoutTime_DTCM" SG_ 1457 External_ChargeTarget2_Sts 0;
BA_ "GenSigTimeoutTime_ECM" SG_ 1457 External_ChargeTarget2_Sts 0;
BA_ "GenSigTimeoutTime_EVCU2" SG_ 1457 External_ChargeTarget2_Sts 0;
BA_ "GenSigTimeoutTime_GNMM" SG_ 1457 External_ChargeTarget2_Sts 0;
BA_ "GenSigTimeoutTime_HCP" SG_ 1457 External_ChargeTarget2_Sts 0;
BA_ "GenSigTimeoutTime_IPC" SG_ 1457 External_ChargeTarget2_Sts 0;
BA_ "GenSigTimeoutTime_RFHM" SG_ 1457 External_ChargeTarget2_Sts 0;
BA_ "GenSigTimeoutTime_TCM" SG_ 1457 External_ChargeTarget2_Sts 0;
BA_ "GenSigStartValue" SG_ 1457 Immediate_ChargeTarget1_Sts 15;
BA_ "GenSigSendType" SG_ 1457 Immediate_ChargeTarget1_Sts 3;
BA_ "GenSigTimeoutTime_AGSM" SG_ 1457 Immediate_ChargeTarget1_Sts 0;
BA_ "GenSigTimeoutTime_BCM" SG_ 1457 Immediate_ChargeTarget1_Sts 0;
BA_ "GenSigTimeoutTime_BSM" SG_ 1457 Immediate_ChargeTarget1_Sts 0;
BA_ "GenSigTimeoutTime_CADM" SG_ 1457 Immediate_ChargeTarget1_Sts 0;
BA_ "GenSigTimeoutTime_DMSM" SG_ 1457 Immediate_ChargeTarget1_Sts 0;
BA_ "GenSigTimeoutTime_DTCM" SG_ 1457 Immediate_ChargeTarget1_Sts 0;
BA_ "GenSigTimeoutTime_ECM" SG_ 1457 Immediate_ChargeTarget1_Sts 0;
BA_ "GenSigTimeoutTime_EVCU2" SG_ 1457 Immediate_ChargeTarget1_Sts 0;
BA_ "GenSigTimeoutTime_GNMM" SG_ 1457 Immediate_ChargeTarget1_Sts 0;
BA_ "GenSigTimeoutTime_HCP" SG_ 1457 Immediate_ChargeTarget1_Sts 0;
BA_ "GenSigTimeoutTime_IPC" SG_ 1457 Immediate_ChargeTarget1_Sts 0;
BA_ "GenSigTimeoutTime_RFHM" SG_ 1457 Immediate_ChargeTarget1_Sts 0;
BA_ "GenSigTimeoutTime_TCM" SG_ 1457 Immediate_ChargeTarget1_Sts 0;
BA_ "GenSigStartValue" SG_ 1457 Immediate_ChargeTarget2_Sts 15;
BA_ "GenSigSendType" SG_ 1457 Immediate_ChargeTarget2_Sts 3;
BA_ "GenSigTimeoutTime_AGSM" SG_ 1457 Immediate_ChargeTarget2_Sts 0;
BA_ "GenSigTimeoutTime_BCM" SG_ 1457 Immediate_ChargeTarget2_Sts 0;
BA_ "GenSigTimeoutTime_BSM" SG_ 1457 Immediate_ChargeTarget2_Sts 0;
BA_ "GenSigTimeoutTime_CADM" SG_ 1457 Immediate_ChargeTarget2_Sts 0;
BA_ "GenSigTimeoutTime_DMSM" SG_ 1457 Immediate_ChargeTarget2_Sts 0;
BA_ "GenSigTimeoutTime_DTCM" SG_ 1457 Immediate_ChargeTarget2_Sts 0;
BA_ "GenSigTimeoutTime_ECM" SG_ 1457 Immediate_ChargeTarget2_Sts 0;
BA_ "GenSigTimeoutTime_EVCU2" SG_ 1457 Immediate_ChargeTarget2_Sts 0;
BA_ "GenSigTimeoutTime_GNMM" SG_ 1457 Immediate_ChargeTarget2_Sts 0;
BA_ "GenSigTimeoutTime_HCP" SG_ 1457 Immediate_ChargeTarget2_Sts 0;
BA_ "GenSigTimeoutTime_IPC" SG_ 1457 Immediate_ChargeTarget2_Sts 0;
BA_ "GenSigTimeoutTime_RFHM" SG_ 1457 Immediate_ChargeTarget2_Sts 0;
BA_ "GenSigTimeoutTime_TCM" SG_ 1457 Immediate_ChargeTarget2_Sts 0;
BA_ "GenSigSendType" SG_ 1457 Schedule_Confirmed1 3;
BA_ "GenSigTimeoutTime_AGSM" SG_ 1457 Schedule_Confirmed1 0;
BA_ "GenSigTimeoutTime_BCM" SG_ 1457 Schedule_Confirmed1 0;
BA_ "GenSigTimeoutTime_BSM" SG_ 1457 Schedule_Confirmed1 0;
BA_ "GenSigTimeoutTime_CADM" SG_ 1457 Schedule_Confirmed1 0;
BA_ "GenSigTimeoutTime_DMSM" SG_ 1457 Schedule_Confirmed1 0;
BA_ "GenSigTimeoutTime_DTCM" SG_ 1457 Schedule_Confirmed1 0;
BA_ "GenSigTimeoutTime_ECM" SG_ 1457 Schedule_Confirmed1 0;
BA_ "GenSigTimeoutTime_EVCU2" SG_ 1457 Schedule_Confirmed1 0;
BA_ "GenSigTimeoutTime_GNMM" SG_ 1457 Schedule_Confirmed1 0;
BA_ "GenSigTimeoutTime_HCP" SG_ 1457 Schedule_Confirmed1 0;
BA_ "GenSigTimeoutTime_IPC" SG_ 1457 Schedule_Confirmed1 0;
BA_ "GenSigTimeoutTime_RFHM" SG_ 1457 Schedule_Confirmed1 0;
BA_ "GenSigTimeoutTime_TCM" SG_ 1457 Schedule_Confirmed1 0;
BA_ "GenSigSendType" SG_ 1457 Schedule_Confirmed2 3;
BA_ "GenSigTimeoutTime_AGSM" SG_ 1457 Schedule_Confirmed2 0;
BA_ "GenSigTimeoutTime_BCM" SG_ 1457 Schedule_Confirmed2 0;
BA_ "GenSigTimeoutTime_BSM" SG_ 1457 Schedule_Confirmed2 0;
BA_ "GenSigTimeoutTime_CADM" SG_ 1457 Schedule_Confirmed2 0;
BA_ "GenSigTimeoutTime_DMSM" SG_ 1457 Schedule_Confirmed2 0;
BA_ "GenSigTimeoutTime_DTCM" SG_ 1457 Schedule_Confirmed2 0;
BA_ "GenSigTimeoutTime_ECM" SG_ 1457 Schedule_Confirmed2 0;
BA_ "GenSigTimeoutTime_EVCU2" SG_ 1457 Schedule_Confirmed2 0;
BA_ "GenSigTimeoutTime_GNMM" SG_ 1457 Schedule_Confirmed2 0;
BA_ "GenSigTimeoutTime_HCP" SG_ 1457 Schedule_Confirmed2 0;
BA_ "GenSigTimeoutTime_IPC" SG_ 1457 Schedule_Confirmed2 0;
BA_ "GenSigTimeoutTime_RFHM" SG_ 1457 Schedule_Confirmed2 0;
BA_ "GenSigTimeoutTime_TCM" SG_ 1457 Schedule_Confirmed2 0;
BA_ "GenSigSendType" SG_ 1457 Schedule_Day1_Sts 3;
BA_ "GenSigTimeoutTime_AGSM" SG_ 1457 Schedule_Day1_Sts 0;
BA_ "GenSigTimeoutTime_BCM" SG_ 1457 Schedule_Day1_Sts 0;
BA_ "GenSigTimeoutTime_BSM" SG_ 1457 Schedule_Day1_Sts 0;
BA_ "GenSigTimeoutTime_CADM" SG_ 1457 Schedule_Day1_Sts 0;
BA_ "GenSigTimeoutTime_DMSM" SG_ 1457 Schedule_Day1_Sts 0;
BA_ "GenSigTimeoutTime_DTCM" SG_ 1457 Schedule_Day1_Sts 0;
BA_ "GenSigTimeoutTime_ECM" SG_ 1457 Schedule_Day1_Sts 0;
BA_ "GenSigTimeoutTime_EVCU2" SG_ 1457 Schedule_Day1_Sts 0;
BA_ "GenSigTimeoutTime_GNMM" SG_ 1457 Schedule_Day1_Sts 0;
BA_ "GenSigTimeoutTime_HCP" SG_ 1457 Schedule_Day1_Sts 0;
BA_ "GenSigTimeoutTime_IPC" SG_ 1457 Schedule_Day1_Sts 0;
BA_ "GenSigTimeoutTime_RFHM" SG_ 1457 Schedule_Day1_Sts 0;
BA_ "GenSigTimeoutTime_TCM" SG_ 1457 Schedule_Day1_Sts 0;
BA_ "GenSigSendType" SG_ 1457 Schedule_Day2_Sts 3;
BA_ "GenSigTimeoutTime_AGSM" SG_ 1457 Schedule_Day2_Sts 0;
BA_ "GenSigTimeoutTime_BCM" SG_ 1457 Schedule_Day2_Sts 0;
BA_ "GenSigTimeoutTime_BSM" SG_ 1457 Schedule_Day2_Sts 0;
BA_ "GenSigTimeoutTime_CADM" SG_ 1457 Schedule_Day2_Sts 0;
BA_ "GenSigTimeoutTime_DMSM" SG_ 1457 Schedule_Day2_Sts 0;
BA_ "GenSigTimeoutTime_DTCM" SG_ 1457 Schedule_Day2_Sts 0;
BA_ "GenSigTimeoutTime_ECM" SG_ 1457 Schedule_Day2_Sts 0;
BA_ "GenSigTimeoutTime_EVCU2" SG_ 1457 Schedule_Day2_Sts 0;
BA_ "GenSigTimeoutTime_GNMM" SG_ 1457 Schedule_Day2_Sts 0;
BA_ "GenSigTimeoutTime_HCP" SG_ 1457 Schedule_Day2_Sts 0;
BA_ "GenSigTimeoutTime_IPC" SG_ 1457 Schedule_Day2_Sts 0;
BA_ "GenSigTimeoutTime_RFHM" SG_ 1457 Schedule_Day2_Sts 0;
BA_ "GenSigTimeoutTime_TCM" SG_ 1457 Schedule_Day2_Sts 0;
BA_ "GenSigSendType" SG_ 1457 Start_Time_Hr1_Sts 3;
BA_ "GenSigTimeoutTime_AGSM" SG_ 1457 Start_Time_Hr1_Sts 0;
BA_ "GenSigTimeoutTime_BCM" SG_ 1457 Start_Time_Hr1_Sts 0;
BA_ "GenSigTimeoutTime_BSM" SG_ 1457 Start_Time_Hr1_Sts 0;
BA_ "GenSigTimeoutTime_CADM" SG_ 1457 Start_Time_Hr1_Sts 0;
BA_ "GenSigTimeoutTime_DMSM" SG_ 1457 Start_Time_Hr1_Sts 0;
BA_ "GenSigTimeoutTime_DTCM" SG_ 1457 Start_Time_Hr1_Sts 0;
BA_ "GenSigTimeoutTime_ECM" SG_ 1457 Start_Time_Hr1_Sts 0;
BA_ "GenSigTimeoutTime_EVCU2" SG_ 1457 Start_Time_Hr1_Sts 0;
BA_ "GenSigTimeoutTime_GNMM" SG_ 1457 Start_Time_Hr1_Sts 0;
BA_ "GenSigTimeoutTime_HCP" SG_ 1457 Start_Time_Hr1_Sts 0;
BA_ "GenSigTimeoutTime_IPC" SG_ 1457 Start_Time_Hr1_Sts 0;
BA_ "GenSigTimeoutTime_RFHM" SG_ 1457 Start_Time_Hr1_Sts 0;
BA_ "GenSigTimeoutTime_TCM" SG_ 1457 Start_Time_Hr1_Sts 0;
BA_ "GenSigSendType" SG_ 1457 Start_Time_Hr2_Sts 3;
BA_ "GenSigTimeoutTime_AGSM" SG_ 1457 Start_Time_Hr2_Sts 0;
BA_ "GenSigTimeoutTime_BCM" SG_ 1457 Start_Time_Hr2_Sts 0;
BA_ "GenSigTimeoutTime_BSM" SG_ 1457 Start_Time_Hr2_Sts 0;
BA_ "GenSigTimeoutTime_CADM" SG_ 1457 Start_Time_Hr2_Sts 0;
BA_ "GenSigTimeoutTime_DMSM" SG_ 1457 Start_Time_Hr2_Sts 0;
BA_ "GenSigTimeoutTime_DTCM" SG_ 1457 Start_Time_Hr2_Sts 0;
BA_ "GenSigTimeoutTime_ECM" SG_ 1457 Start_Time_Hr2_Sts 0;
BA_ "GenSigTimeoutTime_EVCU2" SG_ 1457 Start_Time_Hr2_Sts 0;
BA_ "GenSigTimeoutTime_GNMM" SG_ 1457 Start_Time_Hr2_Sts 0;
BA_ "GenSigTimeoutTime_HCP" SG_ 1457 Start_Time_Hr2_Sts 0;
BA_ "GenSigTimeoutTime_IPC" SG_ 1457 Start_Time_Hr2_Sts 0;
BA_ "GenSigTimeoutTime_RFHM" SG_ 1457 Start_Time_Hr2_Sts 0;
BA_ "GenSigTimeoutTime_TCM" SG_ 1457 Start_Time_Hr2_Sts 0;
BA_ "GenSigSendType" SG_ 1457 Start_Time_Min1_Sts 3;
BA_ "GenSigTimeoutTime_AGSM" SG_ 1457 Start_Time_Min1_Sts 0;
BA_ "GenSigTimeoutTime_BCM" SG_ 1457 Start_Time_Min1_Sts 0;
BA_ "GenSigTimeoutTime_BSM" SG_ 1457 Start_Time_Min1_Sts 0;
BA_ "GenSigTimeoutTime_CADM" SG_ 1457 Start_Time_Min1_Sts 0;
BA_ "GenSigTimeoutTime_DMSM" SG_ 1457 Start_Time_Min1_Sts 0;
BA_ "GenSigTimeoutTime_DTCM" SG_ 1457 Start_Time_Min1_Sts 0;
BA_ "GenSigTimeoutTime_ECM" SG_ 1457 Start_Time_Min1_Sts 0;
BA_ "GenSigTimeoutTime_EVCU2" SG_ 1457 Start_Time_Min1_Sts 0;
BA_ "GenSigTimeoutTime_GNMM" SG_ 1457 Start_Time_Min1_Sts 0;
BA_ "GenSigTimeoutTime_HCP" SG_ 1457 Start_Time_Min1_Sts 0;
BA_ "GenSigTimeoutTime_IPC" SG_ 1457 Start_Time_Min1_Sts 0;
BA_ "GenSigTimeoutTime_RFHM" SG_ 1457 Start_Time_Min1_Sts 0;
BA_ "GenSigTimeoutTime_TCM" SG_ 1457 Start_Time_Min1_Sts 0;
BA_ "GenSigSendType" SG_ 1457 Start_Time_Min2_Sts 3;
BA_ "GenSigTimeoutTime_AGSM" SG_ 1457 Start_Time_Min2_Sts 0;
BA_ "GenSigTimeoutTime_BCM" SG_ 1457 Start_Time_Min2_Sts 0;
BA_ "GenSigTimeoutTime_BSM" SG_ 1457 Start_Time_Min2_Sts 0;
BA_ "GenSigTimeoutTime_CADM" SG_ 1457 Start_Time_Min2_Sts 0;
BA_ "GenSigTimeoutTime_DMSM" SG_ 1457 Start_Time_Min2_Sts 0;
BA_ "GenSigTimeoutTime_DTCM" SG_ 1457 Start_Time_Min2_Sts 0;
BA_ "GenSigTimeoutTime_ECM" SG_ 1457 Start_Time_Min2_Sts 0;
BA_ "GenSigTimeoutTime_EVCU2" SG_ 1457 Start_Time_Min2_Sts 0;
BA_ "GenSigTimeoutTime_GNMM" SG_ 1457 Start_Time_Min2_Sts 0;
BA_ "GenSigTimeoutTime_HCP" SG_ 1457 Start_Time_Min2_Sts 0;
BA_ "GenSigTimeoutTime_IPC" SG_ 1457 Start_Time_Min2_Sts 0;
BA_ "GenSigTimeoutTime_RFHM" SG_ 1457 Start_Time_Min2_Sts 0;
BA_ "GenSigTimeoutTime_TCM" SG_ 1457 Start_Time_Min2_Sts 0;
BA_ "GenSigSendType" SG_ 1464 Charge_Schedule_Type1 3;
BA_ "GenSigTimeoutTime_AGSM" SG_ 1464 Charge_Schedule_Type1 0;
BA_ "GenSigTimeoutTime_BCM" SG_ 1464 Charge_Schedule_Type1 0;
BA_ "GenSigTimeoutTime_BSM" SG_ 1464 Charge_Schedule_Type1 0;
BA_ "GenSigTimeoutTime_CADM" SG_ 1464 Charge_Schedule_Type1 0;
BA_ "GenSigTimeoutTime_DMSM" SG_ 1464 Charge_Schedule_Type1 0;
BA_ "GenSigTimeoutTime_DTCM" SG_ 1464 Charge_Schedule_Type1 0;
BA_ "GenSigTimeoutTime_ECM" SG_ 1464 Charge_Schedule_Type1 0;
BA_ "GenSigTimeoutTime_GNMM" SG_ 1464 Charge_Schedule_Type1 0;
BA_ "GenSigTimeoutTime_HCP" SG_ 1464 Charge_Schedule_Type1 0;
BA_ "GenSigTimeoutTime_IPC" SG_ 1464 Charge_Schedule_Type1 0;
BA_ "GenSigTimeoutTime_RFHM" SG_ 1464 Charge_Schedule_Type1 0;
BA_ "GenSigTimeoutTime_SGW" SG_ 1464 Charge_Schedule_Type1 0;
BA_ "GenSigTimeoutTime_TCM" SG_ 1464 Charge_Schedule_Type1 0;
BA_ "GenSigSendType" SG_ 1464 Charge_Schedule_Type2 3;
BA_ "GenSigTimeoutTime_AGSM" SG_ 1464 Charge_Schedule_Type2 0;
BA_ "GenSigTimeoutTime_BCM" SG_ 1464 Charge_Schedule_Type2 0;
BA_ "GenSigTimeoutTime_BSM" SG_ 1464 Charge_Schedule_Type2 0;
BA_ "GenSigTimeoutTime_CADM" SG_ 1464 Charge_Schedule_Type2 0;
BA_ "GenSigTimeoutTime_DMSM" SG_ 1464 Charge_Schedule_Type2 0;
BA_ "GenSigTimeoutTime_DTCM" SG_ 1464 Charge_Schedule_Type2 0;
BA_ "GenSigTimeoutTime_ECM" SG_ 1464 Charge_Schedule_Type2 0;
BA_ "GenSigTimeoutTime_GNMM" SG_ 1464 Charge_Schedule_Type2 0;
BA_ "GenSigTimeoutTime_HCP" SG_ 1464 Charge_Schedule_Type2 0;
BA_ "GenSigTimeoutTime_IPC" SG_ 1464 Charge_Schedule_Type2 0;
BA_ "GenSigTimeoutTime_RFHM" SG_ 1464 Charge_Schedule_Type2 0;
BA_ "GenSigTimeoutTime_SGW" SG_ 1464 Charge_Schedule_Type2 0;
BA_ "GenSigTimeoutTime_TCM" SG_ 1464 Charge_Schedule_Type2 0;
BA_ "GenSigSendType" SG_ 1464 ChargeUntilFull1 3;
BA_ "GenSigTimeoutTime_AGSM" SG_ 1464 ChargeUntilFull1 0;
BA_ "GenSigTimeoutTime_BCM" SG_ 1464 ChargeUntilFull1 0;
BA_ "GenSigTimeoutTime_BSM" SG_ 1464 ChargeUntilFull1 0;
BA_ "GenSigTimeoutTime_CADM" SG_ 1464 ChargeUntilFull1 0;
BA_ "GenSigTimeoutTime_DMSM" SG_ 1464 ChargeUntilFull1 0;
BA_ "GenSigTimeoutTime_DTCM" SG_ 1464 ChargeUntilFull1 0;
BA_ "GenSigTimeoutTime_ECM" SG_ 1464 ChargeUntilFull1 0;
BA_ "GenSigTimeoutTime_GNMM" SG_ 1464 ChargeUntilFull1 0;
BA_ "GenSigTimeoutTime_HCP" SG_ 1464 ChargeUntilFull1 0;
BA_ "GenSigTimeoutTime_IPC" SG_ 1464 ChargeUntilFull1 0;
BA_ "GenSigTimeoutTime_RFHM" SG_ 1464 ChargeUntilFull1 0;
BA_ "GenSigTimeoutTime_SGW" SG_ 1464 ChargeUntilFull1 0;
BA_ "GenSigTimeoutTime_TCM" SG_ 1464 ChargeUntilFull1 0;
BA_ "GenSigSendType" SG_ 1464 ChargeUntilFull2 3;
BA_ "GenSigTimeoutTime_AGSM" SG_ 1464 ChargeUntilFull2 0;
BA_ "GenSigTimeoutTime_BCM" SG_ 1464 ChargeUntilFull2 0;
BA_ "GenSigTimeoutTime_BSM" SG_ 1464 ChargeUntilFull2 0;
BA_ "GenSigTimeoutTime_CADM" SG_ 1464 ChargeUntilFull2 0;
BA_ "GenSigTimeoutTime_DMSM" SG_ 1464 ChargeUntilFull2 0;
BA_ "GenSigTimeoutTime_DTCM" SG_ 1464 ChargeUntilFull2 0;
BA_ "GenSigTimeoutTime_ECM" SG_ 1464 ChargeUntilFull2 0;
BA_ "GenSigTimeoutTime_GNMM" SG_ 1464 ChargeUntilFull2 0;
BA_ "GenSigTimeoutTime_HCP" SG_ 1464 ChargeUntilFull2 0;
BA_ "GenSigTimeoutTime_IPC" SG_ 1464 ChargeUntilFull2 0;
BA_ "GenSigTimeoutTime_RFHM" SG_ 1464 ChargeUntilFull2 0;
BA_ "GenSigTimeoutTime_SGW" SG_ 1464 ChargeUntilFull2 0;
BA_ "GenSigTimeoutTime_TCM" SG_ 1464 ChargeUntilFull2 0;
BA_ "GenSigSendType" SG_ 1464 Enable_Schedule1 3;
BA_ "GenSigTimeoutTime_AGSM" SG_ 1464 Enable_Schedule1 0;
BA_ "GenSigTimeoutTime_BCM" SG_ 1464 Enable_Schedule1 0;
BA_ "GenSigTimeoutTime_BSM" SG_ 1464 Enable_Schedule1 0;
BA_ "GenSigTimeoutTime_CADM" SG_ 1464 Enable_Schedule1 0;
BA_ "GenSigTimeoutTime_DMSM" SG_ 1464 Enable_Schedule1 0;
BA_ "GenSigTimeoutTime_DTCM" SG_ 1464 Enable_Schedule1 0;
BA_ "GenSigTimeoutTime_ECM" SG_ 1464 Enable_Schedule1 0;
BA_ "GenSigTimeoutTime_GNMM" SG_ 1464 Enable_Schedule1 0;
BA_ "GenSigTimeoutTime_HCP" SG_ 1464 Enable_Schedule1 0;
BA_ "GenSigTimeoutTime_IPC" SG_ 1464 Enable_Schedule1 0;
BA_ "GenSigTimeoutTime_RFHM" SG_ 1464 Enable_Schedule1 0;
BA_ "GenSigTimeoutTime_SGW" SG_ 1464 Enable_Schedule1 0;
BA_ "GenSigTimeoutTime_TCM" SG_ 1464 Enable_Schedule1 0;
BA_ "GenSigSendType" SG_ 1464 Enable_Schedule2 3;
BA_ "GenSigTimeoutTime_AGSM" SG_ 1464 Enable_Schedule2 0;
BA_ "GenSigTimeoutTime_BCM" SG_ 1464 Enable_Schedule2 0;
BA_ "GenSigTimeoutTime_BSM" SG_ 1464 Enable_Schedule2 0;
BA_ "GenSigTimeoutTime_CADM" SG_ 1464 Enable_Schedule2 0;
BA_ "GenSigTimeoutTime_DMSM" SG_ 1464 Enable_Schedule2 0;
BA_ "GenSigTimeoutTime_DTCM" SG_ 1464 Enable_Schedule2 0;
BA_ "GenSigTimeoutTime_ECM" SG_ 1464 Enable_Schedule2 0;
BA_ "GenSigTimeoutTime_GNMM" SG_ 1464 Enable_Schedule2 0;
BA_ "GenSigTimeoutTime_HCP" SG_ 1464 Enable_Schedule2 0;
BA_ "GenSigTimeoutTime_IPC" SG_ 1464 Enable_Schedule2 0;
BA_ "GenSigTimeoutTime_RFHM" SG_ 1464 Enable_Schedule2 0;
BA_ "GenSigTimeoutTime_SGW" SG_ 1464 Enable_Schedule2 0;
BA_ "GenSigTimeoutTime_TCM" SG_ 1464 Enable_Schedule2 0;
BA_ "GenSigSendType" SG_ 1464 End_Time_Hr1 3;
BA_ "GenSigTimeoutTime_AGSM" SG_ 1464 End_Time_Hr1 0;
BA_ "GenSigTimeoutTime_BCM" SG_ 1464 End_Time_Hr1 0;
BA_ "GenSigTimeoutTime_BSM" SG_ 1464 End_Time_Hr1 0;
BA_ "GenSigTimeoutTime_CADM" SG_ 1464 End_Time_Hr1 0;
BA_ "GenSigTimeoutTime_DMSM" SG_ 1464 End_Time_Hr1 0;
BA_ "GenSigTimeoutTime_DTCM" SG_ 1464 End_Time_Hr1 0;
BA_ "GenSigTimeoutTime_ECM" SG_ 1464 End_Time_Hr1 0;
BA_ "GenSigTimeoutTime_GNMM" SG_ 1464 End_Time_Hr1 0;
BA_ "GenSigTimeoutTime_HCP" SG_ 1464 End_Time_Hr1 0;
BA_ "GenSigTimeoutTime_IPC" SG_ 1464 End_Time_Hr1 0;
BA_ "GenSigTimeoutTime_RFHM" SG_ 1464 End_Time_Hr1 0;
BA_ "GenSigTimeoutTime_SGW" SG_ 1464 End_Time_Hr1 0;
BA_ "GenSigTimeoutTime_TCM" SG_ 1464 End_Time_Hr1 0;
BA_ "GenSigSendType" SG_ 1464 End_Time_Hr2 3;
BA_ "GenSigTimeoutTime_AGSM" SG_ 1464 End_Time_Hr2 0;
BA_ "GenSigTimeoutTime_BCM" SG_ 1464 End_Time_Hr2 0;
BA_ "GenSigTimeoutTime_BSM" SG_ 1464 End_Time_Hr2 0;
BA_ "GenSigTimeoutTime_CADM" SG_ 1464 End_Time_Hr2 0;
BA_ "GenSigTimeoutTime_DMSM" SG_ 1464 End_Time_Hr2 0;
BA_ "GenSigTimeoutTime_DTCM" SG_ 1464 End_Time_Hr2 0;
BA_ "GenSigTimeoutTime_ECM" SG_ 1464 End_Time_Hr2 0;
BA_ "GenSigTimeoutTime_GNMM" SG_ 1464 End_Time_Hr2 0;
BA_ "GenSigTimeoutTime_HCP" SG_ 1464 End_Time_Hr2 0;
BA_ "GenSigTimeoutTime_IPC" SG_ 1464 End_Time_Hr2 0;
BA_ "GenSigTimeoutTime_RFHM" SG_ 1464 End_Time_Hr2 0;
BA_ "GenSigTimeoutTime_SGW" SG_ 1464 End_Time_Hr2 0;
BA_ "GenSigTimeoutTime_TCM" SG_ 1464 End_Time_Hr2 0;
BA_ "GenSigSendType" SG_ 1464 End_Time_Min1 3;
BA_ "GenSigTimeoutTime_AGSM" SG_ 1464 End_Time_Min1 0;
BA_ "GenSigTimeoutTime_BCM" SG_ 1464 End_Time_Min1 0;
BA_ "GenSigTimeoutTime_BSM" SG_ 1464 End_Time_Min1 0;
BA_ "GenSigTimeoutTime_CADM" SG_ 1464 End_Time_Min1 0;
BA_ "GenSigTimeoutTime_DMSM" SG_ 1464 End_Time_Min1 0;
BA_ "GenSigTimeoutTime_DTCM" SG_ 1464 End_Time_Min1 0;
BA_ "GenSigTimeoutTime_ECM" SG_ 1464 End_Time_Min1 0;
BA_ "GenSigTimeoutTime_GNMM" SG_ 1464 End_Time_Min1 0;
BA_ "GenSigTimeoutTime_HCP" SG_ 1464 End_Time_Min1 0;
BA_ "GenSigTimeoutTime_IPC" SG_ 1464 End_Time_Min1 0;
BA_ "GenSigTimeoutTime_RFHM" SG_ 1464 End_Time_Min1 0;
BA_ "GenSigTimeoutTime_SGW" SG_ 1464 End_Time_Min1 0;
BA_ "GenSigTimeoutTime_TCM" SG_ 1464 End_Time_Min1 0;
BA_ "GenSigSendType" SG_ 1464 End_Time_Min2 3;
BA_ "GenSigTimeoutTime_AGSM" SG_ 1464 End_Time_Min2 0;
BA_ "GenSigTimeoutTime_BCM" SG_ 1464 End_Time_Min2 0;
BA_ "GenSigTimeoutTime_BSM" SG_ 1464 End_Time_Min2 0;
BA_ "GenSigTimeoutTime_CADM" SG_ 1464 End_Time_Min2 0;
BA_ "GenSigTimeoutTime_DMSM" SG_ 1464 End_Time_Min2 0;
BA_ "GenSigTimeoutTime_DTCM" SG_ 1464 End_Time_Min2 0;
BA_ "GenSigTimeoutTime_ECM" SG_ 1464 End_Time_Min2 0;
BA_ "GenSigTimeoutTime_GNMM" SG_ 1464 End_Time_Min2 0;
BA_ "GenSigTimeoutTime_HCP" SG_ 1464 End_Time_Min2 0;
BA_ "GenSigTimeoutTime_IPC" SG_ 1464 End_Time_Min2 0;
BA_ "GenSigTimeoutTime_RFHM" SG_ 1464 End_Time_Min2 0;
BA_ "GenSigTimeoutTime_SGW" SG_ 1464 End_Time_Min2 0;
BA_ "GenSigTimeoutTime_TCM" SG_ 1464 End_Time_Min2 0;
BA_ "GenSigStartValue" SG_ 1464 External_ChargeTarget1 15;
BA_ "GenSigSendType" SG_ 1464 External_ChargeTarget1 3;
BA_ "GenSigTimeoutTime_AGSM" SG_ 1464 External_ChargeTarget1 0;
BA_ "GenSigTimeoutTime_BCM" SG_ 1464 External_ChargeTarget1 0;
BA_ "GenSigTimeoutTime_BSM" SG_ 1464 External_ChargeTarget1 0;
BA_ "GenSigTimeoutTime_CADM" SG_ 1464 External_ChargeTarget1 0;
BA_ "GenSigTimeoutTime_DMSM" SG_ 1464 External_ChargeTarget1 0;
BA_ "GenSigTimeoutTime_DTCM" SG_ 1464 External_ChargeTarget1 0;
BA_ "GenSigTimeoutTime_ECM" SG_ 1464 External_ChargeTarget1 0;
BA_ "GenSigTimeoutTime_GNMM" SG_ 1464 External_ChargeTarget1 0;
BA_ "GenSigTimeoutTime_HCP" SG_ 1464 External_ChargeTarget1 0;
BA_ "GenSigTimeoutTime_IPC" SG_ 1464 External_ChargeTarget1 0;
BA_ "GenSigTimeoutTime_RFHM" SG_ 1464 External_ChargeTarget1 0;
BA_ "GenSigTimeoutTime_SGW" SG_ 1464 External_ChargeTarget1 0;
BA_ "GenSigTimeoutTime_TCM" SG_ 1464 External_ChargeTarget1 0;
BA_ "GenSigStartValue" SG_ 1464 External_ChargeTarget2 15;
BA_ "GenSigSendType" SG_ 1464 External_ChargeTarget2 3;
BA_ "GenSigTimeoutTime_AGSM" SG_ 1464 External_ChargeTarget2 0;
BA_ "GenSigTimeoutTime_BCM" SG_ 1464 External_ChargeTarget2 0;
BA_ "GenSigTimeoutTime_BSM" SG_ 1464 External_ChargeTarget2 0;
BA_ "GenSigTimeoutTime_CADM" SG_ 1464 External_ChargeTarget2 0;
BA_ "GenSigTimeoutTime_DMSM" SG_ 1464 External_ChargeTarget2 0;
BA_ "GenSigTimeoutTime_DTCM" SG_ 1464 External_ChargeTarget2 0;
BA_ "GenSigTimeoutTime_ECM" SG_ 1464 External_ChargeTarget2 0;
BA_ "GenSigTimeoutTime_GNMM" SG_ 1464 External_ChargeTarget2 0;
BA_ "GenSigTimeoutTime_HCP" SG_ 1464 External_ChargeTarget2 0;
BA_ "GenSigTimeoutTime_IPC" SG_ 1464 External_ChargeTarget2 0;
BA_ "GenSigTimeoutTime_RFHM" SG_ 1464 External_ChargeTarget2 0;
BA_ "GenSigTimeoutTime_SGW" SG_ 1464 External_ChargeTarget2 0;
BA_ "GenSigTimeoutTime_TCM" SG_ 1464 External_ChargeTarget2 0;
BA_ "GenSigStartValue" SG_ 1464 Immediate_ChargeTarget1 15;
BA_ "GenSigSendType" SG_ 1464 Immediate_ChargeTarget1 3;
BA_ "GenSigTimeoutTime_AGSM" SG_ 1464 Immediate_ChargeTarget1 0;
BA_ "GenSigTimeoutTime_BCM" SG_ 1464 Immediate_ChargeTarget1 0;
BA_ "GenSigTimeoutTime_BSM" SG_ 1464 Immediate_ChargeTarget1 0;
BA_ "GenSigTimeoutTime_CADM" SG_ 1464 Immediate_ChargeTarget1 0;
BA_ "GenSigTimeoutTime_DMSM" SG_ 1464 Immediate_ChargeTarget1 0;
BA_ "GenSigTimeoutTime_DTCM" SG_ 1464 Immediate_ChargeTarget1 0;
BA_ "GenSigTimeoutTime_ECM" SG_ 1464 Immediate_ChargeTarget1 0;
BA_ "GenSigTimeoutTime_GNMM" SG_ 1464 Immediate_ChargeTarget1 0;
BA_ "GenSigTimeoutTime_HCP" SG_ 1464 Immediate_ChargeTarget1 0;
BA_ "GenSigTimeoutTime_IPC" SG_ 1464 Immediate_ChargeTarget1 0;
BA_ "GenSigTimeoutTime_RFHM" SG_ 1464 Immediate_ChargeTarget1 0;
BA_ "GenSigTimeoutTime_SGW" SG_ 1464 Immediate_ChargeTarget1 0;
BA_ "GenSigTimeoutTime_TCM" SG_ 1464 Immediate_ChargeTarget1 0;
BA_ "GenSigStartValue" SG_ 1464 Immediate_ChargeTarget2 15;
BA_ "GenSigSendType" SG_ 1464 Immediate_ChargeTarget2 3;
BA_ "GenSigTimeoutTime_AGSM" SG_ 1464 Immediate_ChargeTarget2 0;
BA_ "GenSigTimeoutTime_BCM" SG_ 1464 Immediate_ChargeTarget2 0;
BA_ "GenSigTimeoutTime_BSM" SG_ 1464 Immediate_ChargeTarget2 0;
BA_ "GenSigTimeoutTime_CADM" SG_ 1464 Immediate_ChargeTarget2 0;
BA_ "GenSigTimeoutTime_DMSM" SG_ 1464 Immediate_ChargeTarget2 0;
BA_ "GenSigTimeoutTime_DTCM" SG_ 1464 Immediate_ChargeTarget2 0;
BA_ "GenSigTimeoutTime_ECM" SG_ 1464 Immediate_ChargeTarget2 0;
BA_ "GenSigTimeoutTime_GNMM" SG_ 1464 Immediate_ChargeTarget2 0;
BA_ "GenSigTimeoutTime_HCP" SG_ 1464 Immediate_ChargeTarget2 0;
BA_ "GenSigTimeoutTime_IPC" SG_ 1464 Immediate_ChargeTarget2 0;
BA_ "GenSigTimeoutTime_RFHM" SG_ 1464 Immediate_ChargeTarget2 0;
BA_ "GenSigTimeoutTime_SGW" SG_ 1464 Immediate_ChargeTarget2 0;
BA_ "GenSigTimeoutTime_TCM" SG_ 1464 Immediate_ChargeTarget2 0;
BA_ "GenSigSendType" SG_ 1464 Schedule_Day1 3;
BA_ "GenSigTimeoutTime_AGSM" SG_ 1464 Schedule_Day1 0;
BA_ "GenSigTimeoutTime_BCM" SG_ 1464 Schedule_Day1 0;
BA_ "GenSigTimeoutTime_BSM" SG_ 1464 Schedule_Day1 0;
BA_ "GenSigTimeoutTime_CADM" SG_ 1464 Schedule_Day1 0;
BA_ "GenSigTimeoutTime_DMSM" SG_ 1464 Schedule_Day1 0;
BA_ "GenSigTimeoutTime_DTCM" SG_ 1464 Schedule_Day1 0;
BA_ "GenSigTimeoutTime_ECM" SG_ 1464 Schedule_Day1 0;
BA_ "GenSigTimeoutTime_GNMM" SG_ 1464 Schedule_Day1 0;
BA_ "GenSigTimeoutTime_HCP" SG_ 1464 Schedule_Day1 0;
BA_ "GenSigTimeoutTime_IPC" SG_ 1464 Schedule_Day1 0;
BA_ "GenSigTimeoutTime_RFHM" SG_ 1464 Schedule_Day1 0;
BA_ "GenSigTimeoutTime_SGW" SG_ 1464 Schedule_Day1 0;
BA_ "GenSigTimeoutTime_TCM" SG_ 1464 Schedule_Day1 0;
BA_ "GenSigSendType" SG_ 1464 Schedule_Day2 3;
BA_ "GenSigTimeoutTime_AGSM" SG_ 1464 Schedule_Day2 0;
BA_ "GenSigTimeoutTime_BCM" SG_ 1464 Schedule_Day2 0;
BA_ "GenSigTimeoutTime_BSM" SG_ 1464 Schedule_Day2 0;
BA_ "GenSigTimeoutTime_CADM" SG_ 1464 Schedule_Day2 0;
BA_ "GenSigTimeoutTime_DMSM" SG_ 1464 Schedule_Day2 0;
BA_ "GenSigTimeoutTime_DTCM" SG_ 1464 Schedule_Day2 0;
BA_ "GenSigTimeoutTime_ECM" SG_ 1464 Schedule_Day2 0;
BA_ "GenSigTimeoutTime_GNMM" SG_ 1464 Schedule_Day2 0;
BA_ "GenSigTimeoutTime_HCP" SG_ 1464 Schedule_Day2 0;
BA_ "GenSigTimeoutTime_IPC" SG_ 1464 Schedule_Day2 0;
BA_ "GenSigTimeoutTime_RFHM" SG_ 1464 Schedule_Day2 0;
BA_ "GenSigTimeoutTime_SGW" SG_ 1464 Schedule_Day2 0;
BA_ "GenSigTimeoutTime_TCM" SG_ 1464 Schedule_Day2 0;
BA_ "GenSigSendType" SG_ 1464 Start_Time_Hr1 3;
BA_ "GenSigTimeoutTime_AGSM" SG_ 1464 Start_Time_Hr1 0;
BA_ "GenSigTimeoutTime_BCM" SG_ 1464 Start_Time_Hr1 0;
BA_ "GenSigTimeoutTime_BSM" SG_ 1464 Start_Time_Hr1 0;
BA_ "GenSigTimeoutTime_CADM" SG_ 1464 Start_Time_Hr1 0;
BA_ "GenSigTimeoutTime_DMSM" SG_ 1464 Start_Time_Hr1 0;
BA_ "GenSigTimeoutTime_DTCM" SG_ 1464 Start_Time_Hr1 0;
BA_ "GenSigTimeoutTime_ECM" SG_ 1464 Start_Time_Hr1 0;
BA_ "GenSigTimeoutTime_GNMM" SG_ 1464 Start_Time_Hr1 0;
BA_ "GenSigTimeoutTime_HCP" SG_ 1464 Start_Time_Hr1 0;
BA_ "GenSigTimeoutTime_IPC" SG_ 1464 Start_Time_Hr1 0;
BA_ "GenSigTimeoutTime_RFHM" SG_ 1464 Start_Time_Hr1 0;
BA_ "GenSigTimeoutTime_SGW" SG_ 1464 Start_Time_Hr1 0;
BA_ "GenSigTimeoutTime_TCM" SG_ 1464 Start_Time_Hr1 0;
BA_ "GenSigSendType" SG_ 1464 Start_Time_Hr2 3;
BA_ "GenSigTimeoutTime_AGSM" SG_ 1464 Start_Time_Hr2 0;
BA_ "GenSigTimeoutTime_BCM" SG_ 1464 Start_Time_Hr2 0;
BA_ "GenSigTimeoutTime_BSM" SG_ 1464 Start_Time_Hr2 0;
BA_ "GenSigTimeoutTime_CADM" SG_ 1464 Start_Time_Hr2 0;
BA_ "GenSigTimeoutTime_DMSM" SG_ 1464 Start_Time_Hr2 0;
BA_ "GenSigTimeoutTime_DTCM" SG_ 1464 Start_Time_Hr2 0;
BA_ "GenSigTimeoutTime_ECM" SG_ 1464 Start_Time_Hr2 0;
BA_ "GenSigTimeoutTime_GNMM" SG_ 1464 Start_Time_Hr2 0;
BA_ "GenSigTimeoutTime_HCP" SG_ 1464 Start_Time_Hr2 0;
BA_ "GenSigTimeoutTime_IPC" SG_ 1464 Start_Time_Hr2 0;
BA_ "GenSigTimeoutTime_RFHM" SG_ 1464 Start_Time_Hr2 0;
BA_ "GenSigTimeoutTime_SGW" SG_ 1464 Start_Time_Hr2 0;
BA_ "GenSigTimeoutTime_TCM" SG_ 1464 Start_Time_Hr2 0;
BA_ "GenSigSendType" SG_ 1464 Start_Time_Min1 3;
BA_ "GenSigTimeoutTime_AGSM" SG_ 1464 Start_Time_Min1 0;
BA_ "GenSigTimeoutTime_BCM" SG_ 1464 Start_Time_Min1 0;
BA_ "GenSigTimeoutTime_BSM" SG_ 1464 Start_Time_Min1 0;
BA_ "GenSigTimeoutTime_CADM" SG_ 1464 Start_Time_Min1 0;
BA_ "GenSigTimeoutTime_DMSM" SG_ 1464 Start_Time_Min1 0;
BA_ "GenSigTimeoutTime_DTCM" SG_ 1464 Start_Time_Min1 0;
BA_ "GenSigTimeoutTime_ECM" SG_ 1464 Start_Time_Min1 0;
BA_ "GenSigTimeoutTime_GNMM" SG_ 1464 Start_Time_Min1 0;
BA_ "GenSigTimeoutTime_HCP" SG_ 1464 Start_Time_Min1 0;
BA_ "GenSigTimeoutTime_IPC" SG_ 1464 Start_Time_Min1 0;
BA_ "GenSigTimeoutTime_RFHM" SG_ 1464 Start_Time_Min1 0;
BA_ "GenSigTimeoutTime_SGW" SG_ 1464 Start_Time_Min1 0;
BA_ "GenSigTimeoutTime_TCM" SG_ 1464 Start_Time_Min1 0;
BA_ "GenSigSendType" SG_ 1464 Start_Time_Min2 3;
BA_ "GenSigTimeoutTime_AGSM" SG_ 1464 Start_Time_Min2 0;
BA_ "GenSigTimeoutTime_BCM" SG_ 1464 Start_Time_Min2 0;
BA_ "GenSigTimeoutTime_BSM" SG_ 1464 Start_Time_Min2 0;
BA_ "GenSigTimeoutTime_CADM" SG_ 1464 Start_Time_Min2 0;
BA_ "GenSigTimeoutTime_DMSM" SG_ 1464 Start_Time_Min2 0;
BA_ "GenSigTimeoutTime_DTCM" SG_ 1464 Start_Time_Min2 0;
BA_ "GenSigTimeoutTime_ECM" SG_ 1464 Start_Time_Min2 0;
BA_ "GenSigTimeoutTime_GNMM" SG_ 1464 Start_Time_Min2 0;
BA_ "GenSigTimeoutTime_HCP" SG_ 1464 Start_Time_Min2 0;
BA_ "GenSigTimeoutTime_IPC" SG_ 1464 Start_Time_Min2 0;
BA_ "GenSigTimeoutTime_RFHM" SG_ 1464 Start_Time_Min2 0;
BA_ "GenSigTimeoutTime_SGW" SG_ 1464 Start_Time_Min2 0;
BA_ "GenSigTimeoutTime_TCM" SG_ 1464 Start_Time_Min2 0;
BA_ "GenSigSendType" SG_ 1464 Submit_Schedule1 3;
BA_ "GenSigTimeoutTime_AGSM" SG_ 1464 Submit_Schedule1 0;
BA_ "GenSigTimeoutTime_BCM" SG_ 1464 Submit_Schedule1 0;
BA_ "GenSigTimeoutTime_BSM" SG_ 1464 Submit_Schedule1 0;
BA_ "GenSigTimeoutTime_CADM" SG_ 1464 Submit_Schedule1 0;
BA_ "GenSigTimeoutTime_DMSM" SG_ 1464 Submit_Schedule1 0;
BA_ "GenSigTimeoutTime_DTCM" SG_ 1464 Submit_Schedule1 0;
BA_ "GenSigTimeoutTime_ECM" SG_ 1464 Submit_Schedule1 0;
BA_ "GenSigTimeoutTime_GNMM" SG_ 1464 Submit_Schedule1 0;
BA_ "GenSigTimeoutTime_HCP" SG_ 1464 Submit_Schedule1 0;
BA_ "GenSigTimeoutTime_IPC" SG_ 1464 Submit_Schedule1 0;
BA_ "GenSigTimeoutTime_RFHM" SG_ 1464 Submit_Schedule1 0;
BA_ "GenSigTimeoutTime_SGW" SG_ 1464 Submit_Schedule1 0;
BA_ "GenSigTimeoutTime_TCM" SG_ 1464 Submit_Schedule1 0;
BA_ "GenSigSendType" SG_ 1464 Submit_Schedule2 3;
BA_ "GenSigTimeoutTime_AGSM" SG_ 1464 Submit_Schedule2 0;
BA_ "GenSigTimeoutTime_BCM" SG_ 1464 Submit_Schedule2 0;
BA_ "GenSigTimeoutTime_BSM" SG_ 1464 Submit_Schedule2 0;
BA_ "GenSigTimeoutTime_CADM" SG_ 1464 Submit_Schedule2 0;
BA_ "GenSigTimeoutTime_DMSM" SG_ 1464 Submit_Schedule2 0;
BA_ "GenSigTimeoutTime_DTCM" SG_ 1464 Submit_Schedule2 0;
BA_ "GenSigTimeoutTime_ECM" SG_ 1464 Submit_Schedule2 0;
BA_ "GenSigTimeoutTime_GNMM" SG_ 1464 Submit_Schedule2 0;
BA_ "GenSigTimeoutTime_HCP" SG_ 1464 Submit_Schedule2 0;
BA_ "GenSigTimeoutTime_IPC" SG_ 1464 Submit_Schedule2 0;
BA_ "GenSigTimeoutTime_RFHM" SG_ 1464 Submit_Schedule2 0;
BA_ "GenSigTimeoutTime_SGW" SG_ 1464 Submit_Schedule2 0;
BA_ "GenSigTimeoutTime_TCM" SG_ 1464 Submit_Schedule2 0;
VAL_ 1457 Charge_Schedule_Type1_Sts 0 "No_Selection" 1 "Standard_Charge" 2 "External_Charge" 3 "Reserved";
VAL_ 1457 Charge_Schedule_Type2_Sts 0 "No_Selection" 1 "Standard_Charge" 2 "External_Charge" 3 "Reserved";
VAL_ 1457 ChargeUntilFull1_Sts 0 "Charge Until Full Not selected" 1 "Charge Until Full";
VAL_ 1457 ChargeUntilFull2_Sts 0 "Charge Until Full Not selected" 1 "Charge Until Full";
VAL_ 1457 End_Time_Hr1_Sts 31 "SNA";
VAL_ 1457 End_Time_Hr2_Sts 31 "SNA";
VAL_ 1457 End_Time_Min1_Sts 15 "SNA";
VAL_ 1457 End_Time_Min2_Sts 15 "SNA";
VAL_ 1457 External_ChargeTarget1_Sts 15 "No_Selection";
VAL_ 1457 External_ChargeTarget2_Sts 15 "No_Selection";
VAL_ 1457 Immediate_ChargeTarget1_Sts 15 "No_Selection";
VAL_ 1457 Immediate_ChargeTarget2_Sts 15 "No_Selection";
VAL_ 1457 Schedule_Confirmed1 0 "Disable" 1 "Enable";
VAL_ 1457 Schedule_Confirmed2 0 "Disable" 1 "Enable";
VAL_ 1457 Schedule_Day1_Sts 0 "No Selection" 1 "M" 2 "T" 3 "TM" 4 "W" 5 "WM" 6 "WT" 7 "WTM" 8 "Th" 9 "ThM" 10 "ThT" 11 "ThTM" 12 "ThW" 13 "ThWM" 14 "ThWT" 15 "ThWTM" 16 "F" 17 "FM" 18 "FT" 19 "FTM" 20 "FW" 21 "FWM" 22 "FWT" 23 "FWTM" 24 "FTh" 25 "FThM" 26 "FThT" 27 "FThTM" 28 "FThW" 29 "FThWM" 30 "FThWT" 31 "FThWTM" 32 "S" 33 "SM" 34 "ST" 35 "STM" 36 "SW" 37 "SWM" 38 "SWT" 39 "SWTM" 40 "STh" 41 "SThM" 42 "SThT" 43 "SThTM" 44 "SThW" 45 "SThWM" 46 "SThWT" 47 "SThWTM" 48 "SF" 49 "SFM" 50 "SFT" 51 "SFTM" 52 "SFW" 53 "SFWM" 54 "SFWT" 55 "SFWTM" 56 "SFTh" 57 "SFThM" 58 "SFThT" 59 "SFThTM" 60 "SFThW" 61 "SFThWM" 62 "SFThWT" 63 "SFThWTM" 64 "Sa" 65 "SaM" 66 "SaT" 67 "SaTM" 68 "SaW" 69 "SaWM" 70 "SaWT" 71 "SaWTM" 72 "SaTh" 73 "SaThM" 74 "SaThT" 75 "SaThTM" 76 "SaThW" 77 "SaThWM" 78 "SaThWT" 79 "SaThWTM" 80 "SaF" 81 "SaFM" 82 "SaFT" 83 "SaFTM" 84 "SaFW" 85 "SaFWM" 86 "SaFWT" 87 "SaFWTM" 88 "SaFTh" 89 "SaFThM" 90 "SaFThT" 91 "SaFThTM" 92 "SaFThW" 93 "SaFThWM" 94 "SaFThWT" 95 "SaFThWTM" 96 "SaS" 97 "SaSM" 98 "SaST" 99 "SaSTM" 100 "SaSW" 101 "SaSWM" 102 "SaSWT" 103 "SaSWTM" 104 "SaSTh" 105 "SaSThM" 106 "SaSThT" 107 "SaSThTM" 108 "SaSThW" 109 "SaSThWM" 110 "SaSThWT" 111 "SaSThWTM" 112 "SaSF" 113 "SaSFM" 114 "SaSFT" 115 "SaSFTM" 116 "SaSFW" 117 "SaSFWM" 118 "SaSFWT" 119 "SaSFWTM" 120 "SaSFTh" 121 "SaSFThM" 122 "SaSFThT" 123 "SaSFThTM" 124 "SaSFThW" 125 "SaSFThWM" 126 "SaSFThWT" 127 "SaSFThWTM" 255 "SNA";
VAL_ 1457 Schedule_Day2_Sts 0 "No Selection" 1 "M" 2 "T" 3 "TM" 4 "W" 5 "WM" 6 "WT" 7 "WTM" 8 "Th" 9 "ThM" 10 "ThT" 11 "ThTM" 12 "ThW" 13 "ThWM" 14 "ThWT" 15 "ThWTM" 16 "F" 17 "FM" 18 "FT" 19 "FTM" 20 "FW" 21 "FWM" 22 "FWT" 23 "FWTM" 24 "FTh" 25 "FThM" 26 "FThT" 27 "FThTM" 28 "FThW" 29 "FThWM" 30 "FThWT" 31 "FThWTM" 32 "S" 33 "SM" 34 "ST" 35 "STM" 36 "SW" 37 "SWM" 38 "SWT" 39 "SWTM" 40 "STh" 41 "SThM" 42 "SThT" 43 "SThTM" 44 "SThW" 45 "SThWM" 46 "SThWT" 47 "SThWTM" 48 "SF" 49 "SFM" 50 "SFT" 51 "SFTM" 52 "SFW" 53 "SFWM" 54 "SFWT" 55 "SFWTM" 56 "SFTh" 57 "SFThM" 58 "SFThT" 59 "SFThTM" 60 "SFThW" 61 "SFThWM" 62 "SFThWT" 63 "SFThWTM" 64 "Sa" 65 "SaM" 66 "SaT" 67 "SaTM" 68 "SaW" 69 "SaWM" 70 "SaWT" 71 "SaWTM" 72 "SaTh" 73 "SaThM" 74 "SaThT" 75 "SaThTM" 76 "SaThW" 77 "SaThWM" 78 "SaThWT" 79 "SaThWTM" 80 "SaF" 81 "SaFM" 82 "SaFT" 83 "SaFTM" 84 "SaFW" 85 "SaFWM" 86 "SaFWT" 87 "SaFWTM" 88 "SaFTh" 89 "SaFThM" 90 "SaFThT" 91 "SaFThTM" 92 "SaFThW" 93 "SaFThWM" 94 "SaFThWT" 95 "SaFThWTM" 96 "SaS" 97 "SaSM" 98 "SaST" 99 "SaSTM" 100 "SaSW" 101 "SaSWM" 102 "SaSWT" 103 "SaSWTM" 104 "SaSTh" 105 "SaSThM" 106 "SaSThT" 107 "SaSThTM" 108 "SaSThW" 109 "SaSThWM" 110 "SaSThWT" 111 "SaSThWTM" 112 "SaSF" 113 "SaSFM" 114 "SaSFT" 115 "SaSFTM" 116 "SaSFW" 117 "SaSFWM" 118 "SaSFWT" 119 "SaSFWTM" 120 "SaSFTh" 121 "SaSFThM" 122 "SaSFThT" 123 "SaSFThTM" 124 "SaSFThW" 125 "SaSFThWM" 126 "SaSFThWT" 127 "SaSFThWTM" 255 "SNA";
VAL_ 1457 Start_Time_Hr1_Sts 31 "SNA";
VAL_ 1457 Start_Time_Hr2_Sts 31 "SNA";
VAL_ 1457 Start_Time_Min1_Sts 15 "SNA";
VAL_ 1457 Start_Time_Min2_Sts 15 "SNA";
VAL_ 1464 Charge_Schedule_Type1 0 "No_Selection" 1 "Standard_Charge" 2 "External_Charge" 3 "Reserved";
VAL_ 1464 Charge_Schedule_Type2 0 "No_Selection" 1 "Standard_Charge" 2 "External_Charge" 3 "Reserved";
VAL_ 1464 ChargeUntilFull1 0 "Charge Until Full Not selected" 1 "Charge Until Full";
VAL_ 1464 ChargeUntilFull2 0 "Charge Until Full Not selected" 1 "Charge Until Full";
VAL_ 1464 Enable_Schedule1 0 "Disable schedule1" 1 "Enable schedule1";
VAL_ 1464 Enable_Schedule2 0 "Disable schedule2" 1 "Enable schedule2";
VAL_ 1464 End_Time_Hr1 31 "SNA";
VAL_ 1464 End_Time_Hr2 31 "SNA";
VAL_ 1464 End_Time_Min1 15 "SNA";
VAL_ 1464 End_Time_Min2 15 "SNA";
VAL_ 1464 External_ChargeTarget1 15 "No_Selection";
VAL_ 1464 External_ChargeTarget2 15 "No_Selection";
VAL_ 1464 Immediate_ChargeTarget1 15 "No_Selection";
VAL_ 1464 Immediate_ChargeTarget2 15 "No_Selection";
VAL_ 1464 Schedule_Day1 0 "No Selection" 1 "M" 2 "T" 3 "TM" 4 "W" 5 "WM" 6 "WT" 7 "WTM" 8 "Th" 9 "ThM" 10 "ThT" 11 "ThTM" 12 "ThW" 13 "ThWM" 14 "ThWT" 15 "ThWTM" 16 "F" 17 "FM" 18 "FT" 19 "FTM" 20 "FW" 21 "FWM" 22 "FWT" 23 "FWTM" 24 "FTh" 25 "FThM" 26 "FThT" 27 "FThTM" 28 "FThW" 29 "FThWM" 30 "FThWT" 31 "FThWTM" 32 "S" 33 "SM" 34 "ST" 35 "STM" 36 "SW" 37 "SWM" 38 "SWT" 39 "SWTM" 40 "STh" 41 "SThM" 42 "SThT" 43 "SThTM" 44 "SThW" 45 "SThWM" 46 "SThWT" 47 "SThWTM" 48 "SF" 49 "SFM" 50 "SFT" 51 "SFTM" 52 "SFW" 53 "SFWM" 54 "SFWT" 55 "SFWTM" 56 "SFTh" 57 "SFThM" 58 "SFThT" 59 "SFThTM" 60 "SFThW" 61 "SFThWM" 62 "SFThWT" 63 "SFThWTM" 64 "Sa" 65 "SaM" 66 "SaT" 67 "SaTM" 68 "SaW" 69 "SaWM" 70 "SaWT" 71 "SaWTM" 72 "SaTh" 73 "SaThM" 74 "SaThT" 75 "SaThTM" 76 "SaThW" 77 "SaThWM" 78 "SaThWT" 79 "SaThWTM" 80 "SaF" 81 "SaFM" 82 "SaFT" 83 "SaFTM" 84 "SaFW" 85 "SaFWM" 86 "SaFWT" 87 "SaFWTM" 88 "SaFTh" 89 "SaFThM" 90 "SaFThT" 91 "SaFThTM" 92 "SaFThW" 93 "SaFThWM" 94 "SaFThWT" 95 "SaFThWTM" 96 "SaS" 97 "SaSM" 98 "SaST" 99 "SaSTM" 100 "SaSW" 101 "SaSWM" 102 "SaSWT" 103 "SaSWTM" 104 "SaSTh" 105 "SaSThM" 106 "SaSThT" 107 "SaSThTM" 108 "SaSThW" 109 "SaSThWM" 110 "SaSThWT" 111 "SaSThWTM" 112 "SaSF" 113 "SaSFM" 114 "SaSFT" 115 "SaSFTM" 116 "SaSFW" 117 "SaSFWM" 118 "SaSFWT" 119 "SaSFWTM" 120 "SaSFTh" 121 "SaSFThM" 122 "SaSFThT" 123 "SaSFThTM" 124 "SaSFThW" 125 "SaSFThWM" 126 "SaSFThWT" 127 "SaSFThWTM" 255 "SNA";
VAL_ 1464 Schedule_Day2 0 "No Selection" 1 "M" 2 "T" 3 "TM" 4 "W" 5 "WM" 6 "WT" 7 "WTM" 8 "Th" 9 "ThM" 10 "ThT" 11 "ThTM" 12 "ThW" 13 "ThWM" 14 "ThWT" 15 "ThWTM" 16 "F" 17 "FM" 18 "FT" 19 "FTM" 20 "FW" 21 "FWM" 22 "FWT" 23 "FWTM" 24 "FTh" 25 "FThM" 26 "FThT" 27 "FThTM" 28 "FThW" 29 "FThWM" 30 "FThWT" 31 "FThWTM" 32 "S" 33 "SM" 34 "ST" 35 "STM" 36 "SW" 37 "SWM" 38 "SWT" 39 "SWTM" 40 "STh" 41 "SThM" 42 "SThT" 43 "SThTM" 44 "SThW" 45 "SThWM" 46 "SThWT" 47 "SThWTM" 48 "SF" 49 "SFM" 50 "SFT" 51 "SFTM" 52 "SFW" 53 "SFWM" 54 "SFWT" 55 "SFWTM" 56 "SFTh" 57 "SFThM" 58 "SFThT" 59 "SFThTM" 60 "SFThW" 61 "SFThWM" 62 "SFThWT" 63 "SFThWTM" 64 "Sa" 65 "SaM" 66 "SaT" 67 "SaTM" 68 "SaW" 69 "SaWM" 70 "SaWT" 71 "SaWTM" 72 "SaTh" 73 "SaThM" 74 "SaThT" 75 "SaThTM" 76 "SaThW" 77 "SaThWM" 78 "SaThWT" 79 "SaThWTM" 80 "SaF" 81 "SaFM" 82 "SaFT" 83 "SaFTM" 84 "SaFW" 85 "SaFWM" 86 "SaFWT" 87 "SaFWTM" 88 "SaFTh" 89 "SaFThM" 90 "SaFThT" 91 "SaFThTM" 92 "SaFThW" 93 "SaFThWM" 94 "SaFThWT" 95 "SaFThWTM" 96 "SaS" 97 "SaSM" 98 "SaST" 99 "SaSTM" 100 "SaSW" 101 "SaSWM" 102 "SaSWT" 103 "SaSWTM" 104 "SaSTh" 105 "SaSThM" 106 "SaSThT" 107 "SaSThTM" 108 "SaSThW" 109 "SaSThWM" 110 "SaSThWT" 111 "SaSThWTM" 112 "SaSF" 113 "SaSFM" 114 "SaSFT" 115 "SaSFTM" 116 "SaSFW" 117 "SaSFWM" 118 "SaSFWT" 119 "SaSFWTM" 120 "SaSFTh" 121 "SaSFThM" 122 "SaSFThT" 123 "SaSFThTM" 124 "SaSFThW" 125 "SaSFThWM" 126 "SaSFThWT" 127 "SaSFThWTM" 255 "SNA";
VAL_ 1464 Start_Time_Hr1 31 "SNA";
VAL_ 1464 Start_Time_Hr2 31 "SNA";
VAL_ 1464 Start_Time_Min1 15 "SNA";
VAL_ 1464 Start_Time_Min2 15 "SNA";
VAL_ 1464 Submit_Schedule1 0 "No Change" 1 "Change in schedule 1";
VAL_ 1464 Submit_Schedule2 0 "No Change" 1 "Change in schedule 2";
